VERSION ""

NS_ :

BS_:

BU_: VCM FAS EBS

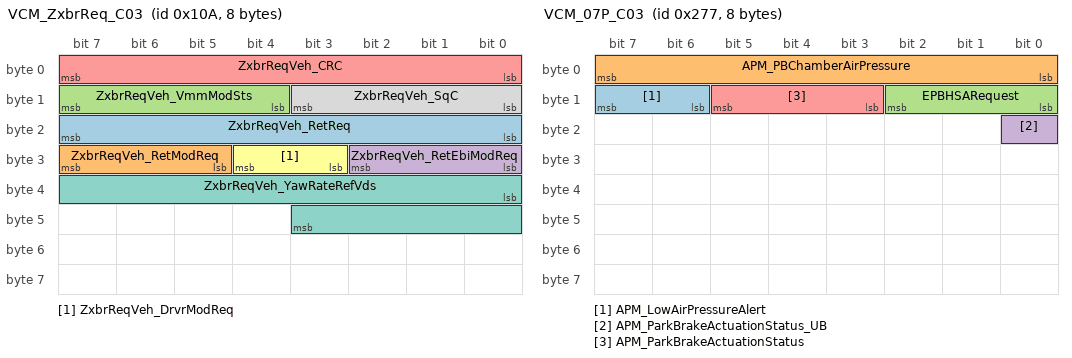
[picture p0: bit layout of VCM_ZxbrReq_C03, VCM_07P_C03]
BO_ 266 VCM_ZxbrReq_C03: 8 VCM
 SG_ ZxbrReqVeh_RetReq : 16|8@1+ (0.005,0) [0|1.275] "NotApplicable"  EBS
 SG_ ZxbrReqVeh_RetModReq : 29|3@1+ (1,0) [0|0] ""  EBS
 SG_ ZxbrReqVeh_VmmModSts : 12|4@1+ (1,0) [0|0] ""  EBS
 SG_ ZxbrReqVeh_RetEbiModReq : 24|3@1+ (1,0) [0|0] ""  EBS
 SG_ ZxbrReqVeh_CRC : 0|8@1+ (1,0) [0|255] ""  EBS
 SG_ ZxbrReqVeh_DrvrModReq : 27|2@1+ (1,0) [0|0] ""  EBS
 SG_ ZxbrReqVeh_YawRateRefVds : 32|12@1+ (0.001,-2) [-2|2.095] "Rad_per_s"  EBS
 SG_ ZxbrReqVeh_SqC : 8|4@1+ (1,0) [0|14] "NotApplicable"  EBS

BO_ 262 VCM_IxbrReqAx456_C03: 48 VCM
 SG_ IxbrReqAxle4_SlipCtrlEna : 41|2@1+ (1,0) [0|0] ""  EBS
 SG_ IxbrReqAxle5_SqC : 128|4@1+ (1,0) [0|14] "NotApplicable"  EBS
 SG_ IxbrReqAxle4_BrkTqReqLe : 43|13@1+ (10,0) [0|81910] "Nm"  EBS
 SG_ IxbrReqAxle4_CRC : 0|8@1+ (1,0) [0|255] ""  EBS
 SG_ IxbrReqAxle5_VehSpdLgtWhlRi : 187|13@1+ (0.01,-40) [-40|41.91] "m_per_s"  EBS
 SG_ IxbrReqAxle6_WhlSlipLimLoLe : 272|9@1+ (0.005,-1) [-1|1.555] "NotApplicable"  EBS
 SG_ IxbrReqAxle5_BrkTqReqRi : 211|13@1+ (10,0) [0|81910] "Nm"  EBS
 SG_ IxbrReqAxle4_BrkTqReqRi : 91|13@1+ (10,0) [0|81910] "Nm"  EBS
 SG_ IxbrReqAxle6_WhlSlipLimHiRi : 344|9@1+ (0.005,-1) [-1|1.555] "NotApplicable"  EBS
 SG_ IxbrReqAxle6_SqC : 248|4@1+ (1,0) [0|14] "NotApplicable"  EBS
 SG_ IxbrReqAxle5_SlipCtrlEna : 161|2@1+ (1,0) [0|0] ""  EBS
 SG_ IxbrReqAxle5_WhlSlipLimLoRi : 200|9@1+ (0.005,-1) [-1|1.555] "NotApplicable"  EBS
 SG_ IxbrReqAxle5_VehSpdLgtWhlLe : 136|13@1+ (0.01,-40) [-40|41.91] "m_per_s"  EBS
 SG_ IxbrReqAxle6_WhlSlipLimLoRi : 320|9@1+ (0.005,-1) [-1|1.555] "NotApplicable"  EBS
 SG_ IxbrReqAxle6_VehSpdLgtWhlRi : 307|13@1+ (0.01,-40) [-40|41.91] "m_per_s"  EBS
 SG_ IxbrReqAxle5_VehSpdLgtWhlQltyLe : 132|4@1+ (1,0) [0|0] ""  EBS
 SG_ IxbrReqAxle6_CRC : 240|8@1+ (1,0) [0|255] ""  EBS
 SG_ IxbrReqAxle5_CRC : 120|8@1+ (1,0) [0|255] ""  EBS
 SG_ IxbrReqAxle4_SqC : 8|4@1+ (1,0) [0|14] "NotApplicable"  EBS
 SG_ IxbrReqAxle4_VehSpdLgtWhlRi : 67|13@1+ (0.01,-40) [-40|41.91] "m_per_s"  EBS
 SG_ IxbrReqAxle4_WhlSlipLimHiLe : 56|9@1+ (0.005,-1) [-1|1.555] "NotApplicable"  EBS
 SG_ IxbrReqAxle4_VehSpdLgtWhlLe : 16|13@1+ (0.01,-40) [-40|41.91] "m_per_s"  EBS
 SG_ IxbrReqAxle4_WhlSlipLimLoLe : 32|9@1+ (0.005,-1) [-1|1.555] "NotApplicable"  EBS
 SG_ IxbrReqAxle6_VehSpdLgtWhlQltyRi : 353|4@1+ (1,0) [0|0] ""  EBS
 SG_ IxbrReqAxle6_BrkTqReqLe : 283|13@1+ (10,0) [0|81910] "Nm"  EBS
 SG_ IxbrReqAxle4_WhlSlipLimLoRi : 80|9@1+ (0.005,-1) [-1|1.555] "NotApplicable"  EBS
 SG_ IxbrReqAxle4_VehSpdLgtWhlQltyRi : 113|4@1+ (1,0) [0|0] ""  EBS
 SG_ IxbrReqAxle4_IxbrModReq : 29|3@1+ (1,0) [0|0] ""  EBS
 SG_ IxbrReqAxle6_BrkTqReqRi : 331|13@1+ (10,0) [0|81910] "Nm"  EBS
 SG_ IxbrReqAxle6_SlipCtrlEna : 281|2@1+ (1,0) [0|0] ""  EBS
 SG_ IxbrReqAxle4_VehSpdLgtWhlQltyLe : 12|4@1+ (1,0) [0|0] ""  EBS
 SG_ IxbrReqAxle6_VehSpdLgtWhlQltyLe : 252|4@1+ (1,0) [0|0] ""  EBS
 SG_ IxbrReqAxle5_BrkTqReqLe : 163|13@1+ (10,0) [0|81910] "Nm"  EBS
 SG_ IxbrReqAxle5_VehSpdLgtWhlQltyRi : 233|4@1+ (1,0) [0|0] ""  EBS
 SG_ IxbrReqAxle5_WhlSlipLimHiRi : 224|9@1+ (0.005,-1) [-1|1.555] "NotApplicable"  EBS
 SG_ IxbrReqAxle5_WhlSlipLimLoLe : 152|9@1+ (0.005,-1) [-1|1.555] "NotApplicable"  EBS
 SG_ IxbrReqAxle5_IxbrModReq : 149|3@1+ (1,0) [0|0] ""  EBS
 SG_ IxbrReqAxle4_WhlSlipLimHiRi : 104|9@1+ (0.005,-1) [-1|1.555] "NotApplicable"  EBS
 SG_ IxbrReqAxle6_IxbrModReq : 269|3@1+ (1,0) [0|0] ""  EBS
 SG_ IxbrReqAxle5_WhlSlipLimHiLe : 176|9@1+ (0.005,-1) [-1|1.555] "NotApplicable"  EBS
 SG_ IxbrReqAxle6_WhlSlipLimHiLe : 296|9@1+ (0.005,-1) [-1|1.555] "NotApplicable"  EBS
 SG_ IxbrReqAxle6_VehSpdLgtWhlLe : 256|13@1+ (0.01,-40) [-40|41.91] "m_per_s"  EBS

BO_ 261 VCM_IxbrReqAx123_C03: 48 VCM
 SG_ IxbrReqAxle3_BrkTqReqLe : 283|13@1+ (10,0) [0|81910] "Nm"  EBS
 SG_ IxbrReqAxle3_WhlSlipLimHiLe : 296|9@1+ (0.005,-1) [-1|1.555] "NotApplicable"  EBS
 SG_ IxbrReqAxle1_BrkTqReqLe : 43|13@1+ (10,0) [0|81910] "Nm"  EBS
 SG_ IxbrReqAxle2_WhlSlipLimHiRi : 224|9@1+ (0.005,-1) [-1|1.555] "NotApplicable"  EBS
 SG_ IxbrReqAxle3_WhlSlipLimLoRi : 320|9@1+ (0.005,-1) [-1|1.555] "NotApplicable"  EBS
 SG_ IxbrReqAxle1_WhlSlipLimLoLe : 32|9@1+ (0.005,-1) [-1|1.555] "NotApplicable"  EBS
 SG_ IxbrReqAxle3_BrkTqReqRi : 331|13@1+ (10,0) [0|81910] "Nm"  EBS
 SG_ IxbrReqAxle2_BrkTqReqLe : 163|13@1+ (10,0) [0|81910] "Nm"  EBS
 SG_ IxbrReqAxle1_VehSpdLgtWhlQltyRi : 113|4@1+ (1,0) [0|0] ""  EBS
 SG_ IxbrReqAxle2_BrkTqReqRi : 211|13@1+ (10,0) [0|81910] "Nm"  EBS
 SG_ IxbrReqAxle1_WhlSlipLimHiLe : 56|9@1+ (0.005,-1) [-1|1.555] "NotApplicable"  EBS
 SG_ IxbrReqAxle1_SlipCtrlEna : 41|2@1+ (1,0) [0|0] ""  EBS
 SG_ IxbrReqAxle1_WhlSlipLimLoRi : 80|9@1+ (0.005,-1) [-1|1.555] "NotApplicable"  EBS
 SG_ IxbrReqAxle2_SlipCtrlEna : 161|2@1+ (1,0) [0|0] ""  EBS
 SG_ IxbrReqAxle1_IxbrModReq : 29|3@1+ (1,0) [0|0] ""  EBS
 SG_ IxbrReqAxle1_SqC : 8|4@1+ (1,0) [0|14] "NotApplicable"  EBS
 SG_ IxbrReqAxle3_VehSpdLgtWhlQltyLe : 252|4@1+ (1,0) [0|0] ""  EBS
 SG_ IxbrReqAxle3_SqC : 248|4@1+ (1,0) [0|14] "NotApplicable"  EBS
 SG_ IxbrReqAxle2_WhlSlipLimLoRi : 200|9@1+ (0.005,-1) [-1|1.555] "NotApplicable"  EBS
 SG_ IxbrReqAxle1_WhlSlipLimHiRi : 104|9@1+ (0.005,-1) [-1|1.555] "NotApplicable"  EBS
 SG_ IxbrReqAxle2_IxbrModReq : 149|3@1+ (1,0) [0|0] ""  EBS
 SG_ IxbrReqAxle3_WhlSlipLimLoLe : 272|9@1+ (0.005,-1) [-1|1.555] "NotApplicable"  EBS
 SG_ IxbrReqAxle2_SqC : 128|4@1+ (1,0) [0|14] "NotApplicable"  EBS
 SG_ IxbrReqAxle1_VehSpdLgtWhlLe : 16|13@1+ (0.01,-40) [-40|41.91] "m_per_s"  EBS
 SG_ IxbrReqAxle3_VehSpdLgtWhlRi : 307|13@1+ (0.01,-40) [-40|41.91] "m_per_s"  EBS
 SG_ IxbrReqAxle3_WhlSlipLimHiRi : 344|9@1+ (0.005,-1) [-1|1.555] "NotApplicable"  EBS
 SG_ IxbrReqAxle2_WhlSlipLimLoLe : 152|9@1+ (0.005,-1) [-1|1.555] "NotApplicable"  EBS
 SG_ IxbrReqAxle2_VehSpdLgtWhlLe : 136|13@1+ (0.01,-40) [-40|41.91] "m_per_s"  EBS
 SG_ IxbrReqAxle2_WhlSlipLimHiLe : 176|9@1+ (0.005,-1) [-1|1.555] "NotApplicable"  EBS
 SG_ IxbrReqAxle3_VehSpdLgtWhlQltyRi : 353|4@1+ (1,0) [0|0] ""  EBS
 SG_ IxbrReqAxle1_VehSpdLgtWhlQltyLe : 12|4@1+ (1,0) [0|0] ""  EBS
 SG_ IxbrReqAxle1_BrkTqReqRi : 91|13@1+ (10,0) [0|81910] "Nm"  EBS
 SG_ IxbrReqAxle1_VehSpdLgtWhlRi : 67|13@1+ (0.01,-40) [-40|41.91] "m_per_s"  EBS
 SG_ IxbrReqAxle3_IxbrModReq : 269|3@1+ (1,0) [0|0] ""  EBS
 SG_ IxbrReqAxle2_CRC : 120|8@1+ (1,0) [0|255] ""  EBS
 SG_ IxbrReqAxle2_VehSpdLgtWhlQltyLe : 132|4@1+ (1,0) [0|0] ""  EBS
 SG_ IxbrReqAxle3_VehSpdLgtWhlLe : 256|13@1+ (0.01,-40) [-40|41.91] "m_per_s"  EBS
 SG_ IxbrReqAxle3_SlipCtrlEna : 281|2@1+ (1,0) [0|0] ""  EBS
 SG_ IxbrReqAxle3_CRC : 240|8@1+ (1,0) [0|255] ""  EBS
 SG_ IxbrReqAxle2_VehSpdLgtWhlRi : 187|13@1+ (0.01,-40) [-40|41.91] "m_per_s"  EBS
 SG_ IxbrReqAxle2_VehSpdLgtWhlQltyRi : 233|4@1+ (1,0) [0|0] ""  EBS
 SG_ IxbrReqAxle1_CRC : 0|8@1+ (1,0) [0|255] ""  EBS

BO_ 554 VCM_EstAxles_C03: 48 VCM
 SG_ EstAxle3_LoadNormLe : 144|8@1+ (100,0) [0|25500] "N"  EBS
 SG_ EstAxle6_WhlRdEstQltyRi : 362|4@1+ (1,0) [0|0] ""  EBS
 SG_ EstAxle5_WhlRdEstQltyRi : 298|4@1+ (1,0) [0|0] ""  EBS
 SG_ EstAxle2_LoadNormQltyLe : 120|4@1+ (1,0) [0|0] ""  EBS
 SG_ EstAxle3_LoadNormQltyRi : 188|4@1+ (1,0) [0|0] ""  EBS
 SG_ EstAxle6_SqC : 328|4@1+ (1,0) [0|14] "NotApplicable"  EBS
 SG_ EstAxle4_LoadNormQltyRi : 252|4@1+ (1,0) [0|0] ""  EBS
 SG_ EstAxle6_LoadNormRi : 344|8@1+ (100,0) [0|25500] "N"  EBS
 SG_ EstAxle5_SqC : 264|4@1+ (1,0) [0|14] "NotApplicable"  EBS
 SG_ EstAxle6_CRC : 320|8@1+ (1,0) [0|255] ""  EBS
 SG_ EstAxle2_WhlRdEstLe : 96|10@1+ (0.001,0.35) [0.35|1.373] "m"  EBS
 SG_ EstAxle3_WhlRdEstRi : 174|10@1+ (0.001,0.35) [0.35|1.373] "m"  EBS
 SG_ EstAxle5_LoadNormQltyRi : 316|4@1+ (1,0) [0|0] ""  EBS
 SG_ EstAxle6_WhlRdEstLe : 352|10@1+ (0.001,0.35) [0.35|1.373] "m"  EBS
 SG_ EstAxle6_WhlRdEstQltyLe : 332|4@1+ (1,0) [0|0] ""  EBS
 SG_ EstAxle6_LoadNormLe : 336|8@1+ (100,0) [0|25500] "N"  EBS
 SG_ EstAxle5_LoadNormRi : 280|8@1+ (100,0) [0|25500] "N"  EBS
 SG_ EstAxle5_LoadNormQltyLe : 312|4@1+ (1,0) [0|0] ""  EBS
 SG_ EstAxle5_CRC : 256|8@1+ (1,0) [0|255] ""  EBS
 SG_ EstAxle1_WhlRdEstRi : 46|10@1+ (0.001,0.35) [0.35|1.373] "m"  EBS
 SG_ EstAxle4_LoadNormRi : 216|8@1+ (100,0) [0|25500] "N"  EBS
 SG_ EstAxle3_WhlRdEstQltyLe : 140|4@1+ (1,0) [0|0] ""  EBS
 SG_ EstAxle4_WhlRdEstRi : 238|10@1+ (0.001,0.35) [0.35|1.373] "m"  EBS
 SG_ EstAxle6_WhlRdEstRi : 366|10@1+ (0.001,0.35) [0.35|1.373] "m"  EBS
 SG_ EstAxle5_LoadNormLe : 272|8@1+ (100,0) [0|25500] "N"  EBS
 SG_ EstAxle5_WhlRdEstLe : 288|10@1+ (0.001,0.35) [0.35|1.373] "m"  EBS
 SG_ EstAxle3_CRC : 128|8@1+ (1,0) [0|255] ""  EBS
 SG_ EstAxle2_LoadNormRi : 88|8@1+ (100,0) [0|25500] "N"  EBS
 SG_ EstAxle4_SqC : 200|4@1+ (1,0) [0|14] "NotApplicable"  EBS
 SG_ EstAxle4_WhlRdEstQltyRi : 234|4@1+ (1,0) [0|0] ""  EBS
 SG_ EstAxle6_LoadNormQltyRi : 380|4@1+ (1,0) [0|0] ""  EBS
 SG_ EstAxle1_LoadNormQltyRi : 60|4@1+ (1,0) [0|0] ""  EBS
 SG_ EstAxle1_LoadNormQltyLe : 56|4@1+ (1,0) [0|0] ""  EBS
 SG_ EstAxle2_LoadNormLe : 80|8@1+ (100,0) [0|25500] "N"  EBS
 SG_ EstAxle4_WhlRdEstQltyLe : 204|4@1+ (1,0) [0|0] ""  EBS
 SG_ EstAxle4_WhlRdEstLe : 224|10@1+ (0.001,0.35) [0.35|1.373] "m"  EBS
 SG_ EstAxle1_WhlRdEstQltyLe : 12|4@1+ (1,0) [0|0] ""  EBS
 SG_ EstAxle2_LoadNormQltyRi : 124|4@1+ (1,0) [0|0] ""  EBS
 SG_ EstAxle3_LoadNormQltyLe : 184|4@1+ (1,0) [0|0] ""  EBS
 SG_ EstAxle4_LoadNormQltyLe : 248|4@1+ (1,0) [0|0] ""  EBS
 SG_ EstAxle2_WhlRdEstQltyRi : 106|4@1+ (1,0) [0|0] ""  EBS
 SG_ EstAxle6_LoadNormQltyLe : 376|4@1+ (1,0) [0|0] ""  EBS
 SG_ EstAxle2_WhlRdEstRi : 110|10@1+ (0.001,0.35) [0.35|1.373] "m"  EBS
 SG_ EstAxle3_WhlRdEstQltyRi : 170|4@1+ (1,0) [0|0] ""  EBS
 SG_ EstAxle1_LoadNormLe : 16|8@1+ (100,0) [0|25500] "N"  EBS
 SG_ EstAxle1_CRC : 0|8@1+ (1,0) [0|255] ""  EBS
 SG_ EstAxle5_WhlRdEstRi : 302|10@1+ (0.001,0.35) [0.35|1.373] "m"  EBS
 SG_ EstAxle2_CRC : 64|8@1+ (1,0) [0|255] ""  EBS
 SG_ EstAxle1_LoadNormRi : 24|8@1+ (100,0) [0|25500] "N"  EBS
 SG_ EstAxle2_WhlRdEstQltyLe : 76|4@1+ (1,0) [0|0] ""  EBS
 SG_ EstAxle4_CRC : 192|8@1+ (1,0) [0|255] ""  EBS
 SG_ EstAxle3_LoadNormRi : 152|8@1+ (100,0) [0|25500] "N"  EBS
 SG_ EstAxle5_WhlRdEstQltyLe : 268|4@1+ (1,0) [0|0] ""  EBS
 SG_ EstAxle3_SqC : 136|4@1+ (1,0) [0|14] "NotApplicable"  EBS
 SG_ EstAxle1_WhlRdEstLe : 32|10@1+ (0.001,0.35) [0.35|1.373] "m"  EBS
 SG_ EstAxle4_LoadNormLe : 208|8@1+ (100,0) [0|25500] "N"  EBS
 SG_ EstAxle1_SqC : 8|4@1+ (1,0) [0|14] "NotApplicable"  EBS
 SG_ EstAxle1_WhlRdEstQltyRi : 42|4@1+ (1,0) [0|0] ""  EBS
 SG_ EstAxle2_SqC : 72|4@1+ (1,0) [0|14] "NotApplicable"  EBS
 SG_ EstAxle3_WhlRdEstLe : 160|10@1+ (0.001,0.35) [0.35|1.373] "m"  EBS

BO_ 631 VCM_07P_C03: 8 VCM
 SG_ APM_LowAirPressureAlert : 14|2@1+ (1,0) [0|0] ""  EBS
 SG_ APM_PBChamberAirPressure : 0|8@1+ (8,0) [0|2040] "kPa"  EBS
 SG_ EPBHSARequest : 8|3@1+ (1,0) [0|0] ""  EBS
 SG_ APM_ParkBrakeActuationStatus_UB : 16|1@1+ (1,0) [0|0] ""  EBS
 SG_ APM_ParkBrakeActuationStatus : 11|3@1+ (1,0) [0|0] ""  EBS

BO_ 1448 VCM_06P_C03: 8 VCM
 SG_ TotalVehicleDistanceHighRes : 0|32@1+ (5,0) [0|21474836475] "m"  FAS
 SG_ AmbientAirTemperature : 32|16@1+ (0.03125,-273) [-273|1774.96875] "DegreeC"  FAS

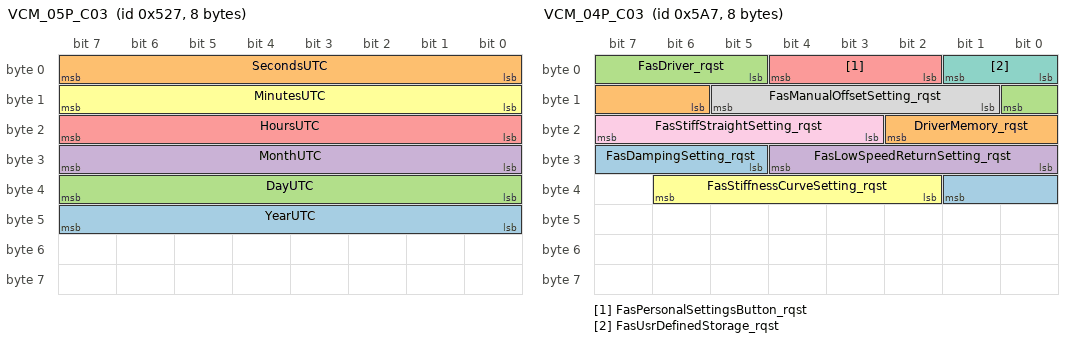
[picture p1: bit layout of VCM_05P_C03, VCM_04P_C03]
BO_ 1319 VCM_05P_C03: 8 VCM
 SG_ YearUTC : 40|8@1+ (1,1985) [1985|2240] "Years"  FAS
 SG_ SecondsUTC : 0|8@1+ (0.25,0) [0|63.75] "s"  FAS
 SG_ DayUTC : 32|8@1+ (0.25,0) [0|63.75] "Days"  FAS
 SG_ MonthUTC : 24|8@1+ (1,0) [0|255] "Months"  FAS
 SG_ HoursUTC : 16|8@1+ (1,0) [0|255] "h"  FAS
 SG_ MinutesUTC : 8|8@1+ (1,0) [0|255] "min"  FAS

BO_ 1447 VCM_04P_C03: 8 VCM
 SG_ FasDampingSetting_rqst : 29|5@1+ (1,-10) [-10|21] ""  FAS
 SG_ DriverMemory_rqst : 14|5@1+ (1,0) [0|0] ""  FAS
 SG_ FasDriver_rqst : 5|4@1+ (1,0) [0|0] ""  FAS
 SG_ FasLowSpeedReturnSetting_rqst : 24|5@1+ (1,-10) [-10|21] ""  FAS
 SG_ FasPersonalSettingsButton_rqst : 2|3@1+ (1,0) [0|0] ""  FAS
 SG_ FasStiffnessCurveSetting_rqst : 34|5@1+ (1,-10) [-10|21] ""  FAS
 SG_ FasUsrDefinedStorage_rqst : 0|2@1+ (1,0) [0|0] ""  FAS
 SG_ FasManualOffsetSetting_rqst : 9|5@1+ (1,-10) [-10|21] ""  FAS
 SG_ FasStiffStraightSetting_rqst : 19|5@1+ (1,-10) [-10|21] ""  FAS

BO_ 1034 VCM_03P_C03: 32 VCM
 SG_ RelativeLevelFrontAxleLeft : 96|16@1+ (0.1,-3200) [-3200|3353.5] "mm"  FAS
 SG_ FrontAxle1Load : 0|16@1+ (0.5,0) [0|32767.5] "kg"  FAS,EBS
 SG_ PusherAxleLoad : 64|16@1+ (0.5,0) [0|32767.5] "kg"  FAS,EBS
 SG_ SecondaryDriveAxleLoad : 48|16@1+ (0.5,0) [0|32767.5] "kg"  FAS,EBS
 SG_ TagAxleLoad : 80|16@1+ (0.5,0) [0|32767.5] "kg"  FAS,EBS
 SG_ ContTrailerBrake_MsgCounter : 136|4@1+ (1,0) [0|15] "Count"  EBS
 SG_ FrontAxle2Load : 16|16@1+ (0.5,0) [0|32767.5] "kg"  FAS,EBS
 SG_ DriveAxleLoad : 32|16@1+ (0.5,0) [0|32767.5] "kg"  EBS,FAS
 SG_ PBAirLvl_AntiCompoundRatio : 156|8@1+ (0.004,0) [0|1.02] ""  EBS
 SG_ ContTrailerBrake_MsgChecksum : 131|5@1+ (1,0) [0|31] ""  EBS
 SG_ PBAirLvl_SqC : 148|4@1+ (1,0) [0|14] "NotApplicable"  EBS
 SG_ PBStatus_CRC : 172|8@1+ (1,0) [0|255] ""  EBS
 SG_ TertiaryDriveAxleLoad : 112|16@1+ (0.5,0) [0|32767.5] "kg"  EBS
 SG_ PBStatus_Actuation : 184|3@1+ (1,0) [0|0] ""  EBS
 SG_ PBStatus_SqC : 180|4@1+ (1,0) [0|14] "NotApplicable"  EBS
 SG_ PBAirLvl_CRC : 140|8@1+ (1,0) [0|255] ""  EBS
 SG_ PBStatus_IntegrityLvl : 188|2@1+ (1,0) [0|0] ""  EBS
 SG_ ContTrailerBrake_Request : 128|3@1+ (1,0) [0|0] ""  EBS
 SG_ PBAirLvl_PressureInChamber : 164|8@1+ (8,0) [0|2040] "kPa"  EBS

BO_ 426 VCM_02P_C03: 32 VCM
 SG_ ChangeKneelACK : 126|2@1+ (1,0) [0|0] ""  EBS
 SG_ LiftAxle1PositionStatus : 112|3@1+ (1,0) [0|0] ""  EBS
 SG_ FrontFerryFunctionCmd : 128|3@1+ (1,0) [0|0] ""  EBS
 SG_ APM_ParkingBrake_stat_UB : 180|1@1+ (1,0) [0|0] ""  EBS
 SG_ ReverseGearEngaged : 22|2@1+ (1,0) [0|0] ""  FAS
 SG_ AirDumpStatus : 104|3@1+ (1,0) [0|0] ""  EBS
 SG_ EngineActiveStatus : 16|4@1+ (1,0) [0|0] ""  FAS
 SG_ FerryFunctionStatus : 107|3@1+ (1,0) [0|0] ""  EBS
 SG_ PitchAngleRef : 56|16@1+ (0.001,-30) [-30|35.535] "deg"  EBS
 SG_ APM_LowVMPBInfoReq : 165|3@1+ (1,0) [0|0] ""  EBS
 SG_ KneelingInformation : 80|4@1+ (1,0) [0|0] ""  EBS
 SG_ FASHapticFeedbackRequest : 28|4@1+ (1,0) [0|0] ""  FAS
 SG_ HeightControlMode : 84|4@1+ (1,0) [0|0] ""  EBS
 SG_ LoadDistributionFuncSelected : 92|4@1+ (1,0) [0|0] ""  EBS
 SG_ PitchAngle : 40|16@1+ (0.001,-30) [-30|35.535] "deg"  EBS
 SG_ RollEndPositionStatus : 123|3@1+ (1,0) [0|0] ""  EBS
 SG_ SupplyPressure : 72|8@1+ (8,0) [0|2040] "kPa"  EBS
 SG_ WheelBasedVehicleSpeed : 0|16@1+ (0.00390625,0) [0|255.99609375] "Km_per_h"  FAS
 SG_ RearAxle2DiffLock_stat : 142|2@1+ (1,0) [0|0] ""  EBS
 SG_ KneelingStatusHMI : 134|2@1+ (1,0) [0|0] ""  EBS
 SG_ HeightAdjustmentAllowed : 110|2@1+ (1,0) [0|0] ""  EBS
 SG_ RideHeightStatus : 100|4@1+ (1,0) [0|0] ""  EBS
 SG_ CentralRearDiffLock_stat : 136|2@1+ (1,0) [0|0] ""  EBS
 SG_ ParkBrakeReleaseMode2 : 172|4@1+ (1,0) [0|0] ""  EBS
 SG_ LiftAxle2PositionStatus : 115|3@1+ (1,0) [0|0] ""  EBS
 SG_ RampHeightOutsideTargetRange : 131|3@1+ (1,0) [0|0] ""  EBS
 SG_ DirInd_Rear_Status : 160|3@1+ (1,0) [0|0] ""  EBS
 SG_ ExternalRequestManualStiffness : 32|4@1+ (0.1,0) [0|1.5] "NotApplicable"  FAS
 SG_ APM_ParkingBrake_stat : 178|2@1+ (1,0) [0|0] ""  EBS
 SG_ VehicleDistanceRollingCounter : 144|16@1+ (0.03125,0) [0|2047.96875] "m"  EBS
 SG_ BackToDriveReqACK : 118|2@1+ (1,0) [0|0] ""  EBS
 SG_ RearAxle1DiffLock_stat : 140|2@1+ (1,0) [0|0] ""  EBS
 SG_ LevelControlInformation : 88|4@1+ (1,0) [0|0] ""  EBS
 SG_ VehicleMode : 36|4@1+ (1,0) [0|0] ""  FAS,EBS
 SG_ ACC_SGO_Status : 24|4@1+ (1,0) [0|0] ""  FAS
 SG_ RearEndPositionStatus : 120|3@1+ (1,0) [0|0] ""  EBS
 SG_ ECSShutdownCmd : 138|2@1+ (1,0) [0|0] ""  EBS
 SG_ APM_ParkBrakeApplicationMode2 : 168|4@1+ (1,0) [0|0] ""  EBS
 SG_ VehicleDynamicSuspProhibitStat : 163|2@1+ (1,0) [0|0] ""  EBS
 SG_ ParkingBrake_stat : 20|2@1+ (1,0) [0|0] ""  FAS
 SG_ RideHeightFunctionStatus : 96|4@1+ (1,0) [0|0] ""  EBS
 SG_ APM_TrailerCircPressureStatus : 176|2@1+ (1,0) [0|0] ""  EBS

CM_ "COM_MATRIX_T3_1.9.0";
CM_ BU_ VCM "Vehicle Control Module";
CM_ BU_ FAS "Front Active Steering";
CM_ BU_ EBS "Electronic Braking System";
BA_DEF_ BO_  "GenMsgStartDelayTime" INT 0 0;
BA_DEF_ BO_  "GenMsgDelayTime" INT 0 0;
BA_DEF_ BO_  "GenMsgCycleTime" INT 0 0;
BA_DEF_ BO_  "GenMsgSendType" ENUM  "Cyclic","NotUsed","NotUsed","NotUsed","NotUsed","NotUsed","NotUsed","IfActive","NoMsgSendType","NotUsed";
BA_DEF_ SG_  "GenSigStartValue" INT 0 0;
BA_DEF_ SG_  "GenSigCycleTimeActive" INT 0 0;
BA_DEF_ SG_  "GenSigCycleTime" INT 0 0;
BA_DEF_ SG_  "GenSigSendType" ENUM  "Cyclic","OnWrite","OnWriteWithRepetition","OnChange","OnChangeWithRepetition","IfActive","IfActiveWithRepetition","NoSigSendType","NotUsed","NotUsed","NotUsed","NotUsed","NotUsed";
BA_DEF_  "Baudrate" INT 0 1000000;
BA_DEF_  "NmType" STRING ;
BA_DEF_  "Manufacturer" STRING ;
BA_DEF_  "VersionYear" INT 0 99;
BA_DEF_  "VersionNumber" INT 0 99;
BA_DEF_  "VersionMonth" INT 1 12;
BA_DEF_  "VersionDay" INT 1 31;
BA_DEF_ BO_  "VFrameFormat" ENUM  "StandardCAN","ExtendedCAN","reserved","J1939PG","reserved","reserved","reserved","reserved","reserved","reserved","reserved","reserved","reserved","reserved","StandardCAN_FD","ExtendedCAN_FD";
BA_DEF_ BU_  "TpOwnSystemEcuNumber" HEX 0 255;
BA_DEF_ SG_  "SigType" ENUM  "Default","Range","RangeSigned","ASCII","Discrete","Control","ReferencePGN","DTC","StringDelimiter","StringLength","StringLengthControl";
BA_DEF_ BU_  "NmStationAddress" INT 0 255;
BA_DEF_  "NmAsrWaitBusSleepTime" INT 0 65535;
BA_DEF_  "NmAsrTimeoutTime" INT 0 65535;
BA_DEF_  "NmAsrRepeatMessageTime" INT 0 65535;
BA_DEF_ BU_  "NmAsrNodeIdentifier" HEX 0 253;
BA_DEF_ BU_  "NmAsrNode" ENUM  "No","Yes";
BA_DEF_  "NmAsrMessageCount" INT 1 256;
BA_DEF_ BO_  "NmAsrMessage" ENUM  "No","Yes";
BA_DEF_  "NmAsrCanMsgCycleTime" INT 0 65535;
BA_DEF_  "NmAsrBaseAddress" HEX 0 536870911;
BA_DEF_ SG_  "NeedsUpdateBit" ENUM  "No","Yes";
BA_DEF_ SG_  "MmAnSignal" ENUM  "No","Yes";
BA_DEF_ BU_  "IsOBDrelevant" ENUM  "No","Yes";
BA_DEF_ SG_  "GenSigMaxLatency" INT 0 65535;
BA_DEF_ SG_  "GenSigILSupport" ENUM  "Yes","No";
BA_DEF_ BO_  "GenMsgILSupport" ENUM  "No","Yes";
BA_DEF_ SG_  "E2EProfile" STRING ;
BA_DEF_  "E2EP05WindowSize" INT 0 65535;
BA_DEF_  "E2EP05ProfileName" STRING ;
BA_DEF_  "E2EP05MinOkStateValid" INT 0 65535;
BA_DEF_  "E2EP05MinOkStateInvalid" INT 0 65535;
BA_DEF_  "E2EP05MinOkStateInit" INT 0 65535;
BA_DEF_  "E2EP05MaxErrorStateValid" INT 0 65535;
BA_DEF_  "E2EP05MaxErrorStateInvalid" INT 0 65535;
BA_DEF_  "E2EP05MaxErrorStateInit" INT 0 65535;
BA_DEF_  "E2EP05MaxDeltaCounter" INT 0 65535;
BA_DEF_  "E2EP01WindowSize" INT 0 65535;
BA_DEF_  "E2EP01SyncCounterInit" INT 0 65535;
BA_DEF_  "E2EP01ProfileName" STRING ;
BA_DEF_  "E2EP01MinOkStateValid" INT 0 65535;
BA_DEF_  "E2EP01MinOkStateInvalid" INT 0 65535;
BA_DEF_  "E2EP01MinOkStateInit" INT 0 65535;
BA_DEF_  "E2EP01MaxNoNewOrRepeatedData" INT 0 65535;
BA_DEF_  "E2EP01MaxErrorStateValid" INT 0 65535;
BA_DEF_  "E2EP01MaxErrorStateInvalid" INT 0 65535;
BA_DEF_  "E2EP01MaxErrorStateInit" INT 0 65535;
BA_DEF_  "E2EP01MaxDeltaCounter" INT 0 65535;
BA_DEF_  "E2EP01DataIdMode" ENUM  "all16Bit","alternating8Bit","lower12Bit","lower8Bit";
BA_DEF_  "E2EP01CounterOffset" INT 0 65535;
BA_DEF_ SG_  "E2EDataLength" INT 0 65535;
BA_DEF_ SG_  "E2EDataId" INT 0 65535;
BA_DEF_ BU_  "DiagnosticClientAddress" HEX 0 255;
BA_DEF_ BO_  "DiagUUDTResponse" ENUM  "No","Yes";
BA_DEF_ BO_  "DiagState" ENUM  "No","Yes";
BA_DEF_ BU_  "DiagRole" ENUM  "None","OBDTester","ExternalTester","InternalTester";
BA_DEF_ BO_  "DiagResponse" ENUM  "No","Yes";
BA_DEF_ BO_  "DiagRequest" ENUM  "No","Yes";
BA_DEF_ BO_  "DiagConnection" HEX 0 65535;
BA_DEF_  "DBName" STRING ;
BA_DEF_ BO_  "CanTpFcFrameId" HEX 0 2147483647;
BA_DEF_ BO_  "CanTpBs" INT 0 255;
BA_DEF_ BO_  "CANFD_BRS" ENUM  "0","1";
BA_DEF_  "BusType" STRING ;
BA_DEF_  "BaudrateCANFD" INT 0 5000000;
BA_DEF_REL_ BU_SG_REL_  "GenSigTimeoutTime" INT 0 65535;
BA_DEF_REL_ BU_SG_REL_  "GenSigFirstTimeoutTime" INT 0 65535;
BA_DEF_DEF_  "GenMsgStartDelayTime" 0;
BA_DEF_DEF_  "GenMsgDelayTime" 0;
BA_DEF_DEF_  "GenMsgCycleTime" 0;
BA_DEF_DEF_  "GenMsgSendType" "Cyclic";
BA_DEF_DEF_  "GenSigStartValue" 0;
BA_DEF_DEF_  "GenSigCycleTimeActive" 0;
BA_DEF_DEF_  "GenSigCycleTime" 0;
BA_DEF_DEF_  "GenSigSendType" "Cyclic";
BA_DEF_DEF_  "Baudrate" 500000;
BA_DEF_DEF_  "NmType" "";
BA_DEF_DEF_  "Manufacturer" "VOLVO_AB";
BA_DEF_DEF_  "VersionYear" 0;
BA_DEF_DEF_  "VersionNumber" 0;
BA_DEF_DEF_  "VersionMonth" 1;
BA_DEF_DEF_  "VersionDay" 1;
BA_DEF_DEF_  "VFrameFormat" "ExtendedCAN";
BA_DEF_DEF_  "TpOwnSystemEcuNumber" 0;
BA_DEF_DEF_  "SigType" "Default";
BA_DEF_DEF_  "NmStationAddress" 254;
BA_DEF_DEF_  "NmAsrWaitBusSleepTime" 750;
BA_DEF_DEF_  "NmAsrTimeoutTime" 5000;
BA_DEF_DEF_  "NmAsrRepeatMessageTime" 300;
BA_DEF_DEF_  "NmAsrNodeIdentifier" 0;
BA_DEF_DEF_  "NmAsrNode" "Yes";
BA_DEF_DEF_  "NmAsrMessageCount" 256;
BA_DEF_DEF_  "NmAsrMessage" "No";
BA_DEF_DEF_  "NmAsrCanMsgCycleTime" 200;
BA_DEF_DEF_  "NmAsrBaseAddress" 486506496;
BA_DEF_DEF_  "NeedsUpdateBit" "No";
BA_DEF_DEF_  "MmAnSignal" "No";
BA_DEF_DEF_  "IsOBDrelevant" "No";
BA_DEF_DEF_  "GenSigMaxLatency" 0;
BA_DEF_DEF_  "GenSigILSupport" "Yes";
BA_DEF_DEF_  "GenMsgILSupport" "Yes";
BA_DEF_DEF_  "E2EProfile" "none";
BA_DEF_DEF_  "E2EP05WindowSize" 5;
BA_DEF_DEF_  "E2EP05ProfileName" "PROFILE_05";
BA_DEF_DEF_  "E2EP05MinOkStateValid" 1;
BA_DEF_DEF_  "E2EP05MinOkStateInvalid" 3;
BA_DEF_DEF_  "E2EP05MinOkStateInit" 1;
BA_DEF_DEF_  "E2EP05MaxErrorStateValid" 3;
BA_DEF_DEF_  "E2EP05MaxErrorStateInvalid" 1;
BA_DEF_DEF_  "E2EP05MaxErrorStateInit" 2;
BA_DEF_DEF_  "E2EP05MaxDeltaCounter" 1;
BA_DEF_DEF_  "E2EP01WindowSize" 5;
BA_DEF_DEF_  "E2EP01SyncCounterInit" 1;
BA_DEF_DEF_  "E2EP01ProfileName" "PROFILE_01";
BA_DEF_DEF_  "E2EP01MinOkStateValid" 1;
BA_DEF_DEF_  "E2EP01MinOkStateInvalid" 3;
BA_DEF_DEF_  "E2EP01MinOkStateInit" 1;
BA_DEF_DEF_  "E2EP01MaxNoNewOrRepeatedData" 5;
BA_DEF_DEF_  "E2EP01MaxErrorStateValid" 3;
BA_DEF_DEF_  "E2EP01MaxErrorStateInvalid" 1;
BA_DEF_DEF_  "E2EP01MaxErrorStateInit" 2;
BA_DEF_DEF_  "E2EP01MaxDeltaCounter" 1;
BA_DEF_DEF_  "E2EP01DataIdMode" "all16Bit";
BA_DEF_DEF_  "E2EP01CounterOffset" 8;
BA_DEF_DEF_  "E2EDataLength" 0;
BA_DEF_DEF_  "E2EDataId" 0;
BA_DEF_DEF_  "DiagnosticClientAddress" 0;
BA_DEF_DEF_  "DiagUUDTResponse" "No";
BA_DEF_DEF_  "DiagState" "No";
BA_DEF_DEF_  "DiagRole" "None";
BA_DEF_DEF_  "DiagResponse" "No";
BA_DEF_DEF_  "DiagRequest" "No";
BA_DEF_DEF_  "DiagConnection" 0;
BA_DEF_DEF_  "DBName" "";
BA_DEF_DEF_  "CanTpFcFrameId" 2147483647;
BA_DEF_DEF_  "CanTpBs" 255;
BA_DEF_DEF_  "CANFD_BRS" "0";
BA_DEF_DEF_  "BusType" "";
BA_DEF_DEF_  "BaudrateCANFD" 0;
BA_DEF_DEF_REL_ "GenSigTimeoutTime" 0;
BA_DEF_DEF_REL_ "GenSigFirstTimeoutTime" 0;
BA_ "NmType" "NmAsr";
BA_ "BusType" "CAN FD";
BA_ "BaudrateCANFD" 1000000;
BA_ "VersionDay" 24;
BA_ "VersionMonth" 2;
BA_ "VersionNumber" 1;
BA_ "VersionYear" 22;
BA_ "DBName" "CAN03";
BA_ "DiagRole" BU_ VCM 3;
BA_ "DiagnosticClientAddress" BU_ VCM 244;
BA_ "IsOBDrelevant" BU_ VCM 1;
BA_ "TpOwnSystemEcuNumber" BU_ VCM 36;
BA_ "NmAsrNodeIdentifier" BU_ VCM 36;
BA_ "TpOwnSystemEcuNumber" BU_ FAS 48;
BA_ "NmAsrNodeIdentifier" BU_ FAS 48;
BA_ "TpOwnSystemEcuNumber" BU_ EBS 40;
BA_ "NmAsrNodeIdentifier" BU_ EBS 40;
BA_ "CANFD_BRS" BO_ 266 1;
BA_ "GenMsgCycleTime" BO_ 266 10;
BA_ "VFrameFormat" BO_ 266 14;
BA_ "CANFD_BRS" BO_ 262 1;
BA_ "GenMsgCycleTime" BO_ 262 10;
BA_ "GenMsgStartDelayTime" BO_ 262 5;
BA_ "VFrameFormat" BO_ 262 14;
BA_ "CANFD_BRS" BO_ 261 1;
BA_ "GenMsgCycleTime" BO_ 261 10;
BA_ "VFrameFormat" BO_ 261 14;
BA_ "CANFD_BRS" BO_ 554 1;
BA_ "GenMsgCycleTime" BO_ 554 50;
BA_ "GenMsgStartDelayTime" BO_ 554 10;
BA_ "VFrameFormat" BO_ 554 14;
BA_ "GenMsgCycleTime" BO_ 631 50;
BA_ "GenMsgStartDelayTime" BO_ 631 35;
BA_ "VFrameFormat" BO_ 631 14;
BA_ "CANFD_BRS" BO_ 1448 1;
BA_ "GenMsgCycleTime" BO_ 1448 1000;
BA_ "GenMsgStartDelayTime" BO_ 1448 225;
BA_ "VFrameFormat" BO_ 1448 14;
BA_ "CANFD_BRS" BO_ 1319 1;
BA_ "GenMsgCycleTime" BO_ 1319 250;
BA_ "GenMsgStartDelayTime" BO_ 1319 50;
BA_ "VFrameFormat" BO_ 1319 14;
BA_ "CANFD_BRS" BO_ 1447 1;
BA_ "GenMsgCycleTime" BO_ 1447 1000;
BA_ "GenMsgStartDelayTime" BO_ 1447 110;
BA_ "VFrameFormat" BO_ 1447 14;
BA_ "CANFD_BRS" BO_ 1034 1;
BA_ "GenMsgCycleTime" BO_ 1034 100;
BA_ "GenMsgStartDelayTime" BO_ 1034 25;
BA_ "VFrameFormat" BO_ 1034 14;
BA_ "CANFD_BRS" BO_ 426 1;
BA_ "GenMsgCycleTime" BO_ 426 20;
BA_ "GenMsgStartDelayTime" BO_ 426 5;
BA_ "VFrameFormat" BO_ 426 14;
BA_ "GenSigCycleTime" SG_ 266 ZxbrReqVeh_RetReq 100;
BA_ "GenSigCycleTimeActive" SG_ 266 ZxbrReqVeh_RetReq 100;
BA_ "GenSigStartValue" SG_ 266 ZxbrReqVeh_RetReq 255;
BA_ "GenSigCycleTime" SG_ 266 ZxbrReqVeh_RetModReq 100;
BA_ "GenSigCycleTimeActive" SG_ 266 ZxbrReqVeh_RetModReq 100;
BA_ "GenSigStartValue" SG_ 266 ZxbrReqVeh_RetModReq 7;
BA_ "GenSigCycleTime" SG_ 266 ZxbrReqVeh_VmmModSts 100;
BA_ "GenSigCycleTimeActive" SG_ 266 ZxbrReqVeh_VmmModSts 100;
BA_ "GenSigStartValue" SG_ 266 ZxbrReqVeh_VmmModSts 15;
BA_ "GenSigCycleTime" SG_ 266 ZxbrReqVeh_RetEbiModReq 100;
BA_ "GenSigCycleTimeActive" SG_ 266 ZxbrReqVeh_RetEbiModReq 100;
BA_ "GenSigStartValue" SG_ 266 ZxbrReqVeh_RetEbiModReq 7;
BA_ "GenSigCycleTime" SG_ 266 ZxbrReqVeh_CRC 100;
BA_ "GenSigCycleTimeActive" SG_ 266 ZxbrReqVeh_CRC 100;
BA_ "GenSigStartValue" SG_ 266 ZxbrReqVeh_CRC 255;
BA_ "E2EDataId" SG_ 266 ZxbrReqVeh_CRC 198;
BA_ "E2EDataLength" SG_ 266 ZxbrReqVeh_CRC 48;
BA_ "E2EProfile" SG_ 266 ZxbrReqVeh_CRC "P01";
BA_ "GenSigCycleTime" SG_ 266 ZxbrReqVeh_DrvrModReq 100;
BA_ "GenSigCycleTimeActive" SG_ 266 ZxbrReqVeh_DrvrModReq 100;
BA_ "GenSigStartValue" SG_ 266 ZxbrReqVeh_DrvrModReq 3;
BA_ "GenSigCycleTime" SG_ 266 ZxbrReqVeh_YawRateRefVds 100;
BA_ "GenSigCycleTimeActive" SG_ 266 ZxbrReqVeh_YawRateRefVds 100;
BA_ "GenSigStartValue" SG_ 266 ZxbrReqVeh_YawRateRefVds 4095;
BA_ "GenSigCycleTime" SG_ 266 ZxbrReqVeh_SqC 100;
BA_ "GenSigCycleTimeActive" SG_ 266 ZxbrReqVeh_SqC 100;
BA_ "GenSigStartValue" SG_ 266 ZxbrReqVeh_SqC 14;
BA_ "GenSigCycleTime" SG_ 262 IxbrReqAxle4_SlipCtrlEna 100;
BA_ "GenSigCycleTimeActive" SG_ 262 IxbrReqAxle4_SlipCtrlEna 100;
BA_ "GenSigStartValue" SG_ 262 IxbrReqAxle4_SlipCtrlEna 3;
BA_ "GenSigCycleTime" SG_ 262 IxbrReqAxle5_SqC 100;
BA_ "GenSigCycleTimeActive" SG_ 262 IxbrReqAxle5_SqC 100;
BA_ "GenSigStartValue" SG_ 262 IxbrReqAxle5_SqC 14;
BA_ "GenSigCycleTime" SG_ 262 IxbrReqAxle4_BrkTqReqLe 100;
BA_ "GenSigCycleTimeActive" SG_ 262 IxbrReqAxle4_BrkTqReqLe 100;
BA_ "GenSigStartValue" SG_ 262 IxbrReqAxle4_BrkTqReqLe 8191;
BA_ "GenSigCycleTime" SG_ 262 IxbrReqAxle4_CRC 100;
BA_ "GenSigCycleTimeActive" SG_ 262 IxbrReqAxle4_CRC 100;
BA_ "GenSigStartValue" SG_ 262 IxbrReqAxle4_CRC 255;
BA_ "E2EDataId" SG_ 262 IxbrReqAxle4_CRC 218;
BA_ "E2EDataLength" SG_ 262 IxbrReqAxle4_CRC 120;
BA_ "E2EProfile" SG_ 262 IxbrReqAxle4_CRC "P01";
BA_ "GenSigCycleTime" SG_ 262 IxbrReqAxle5_VehSpdLgtWhlRi 100;
BA_ "GenSigCycleTimeActive" SG_ 262 IxbrReqAxle5_VehSpdLgtWhlRi 100;
BA_ "GenSigStartValue" SG_ 262 IxbrReqAxle5_VehSpdLgtWhlRi 8191;
BA_ "GenSigCycleTime" SG_ 262 IxbrReqAxle6_WhlSlipLimLoLe 100;
BA_ "GenSigCycleTimeActive" SG_ 262 IxbrReqAxle6_WhlSlipLimLoLe 100;
BA_ "GenSigStartValue" SG_ 262 IxbrReqAxle6_WhlSlipLimLoLe 511;
BA_ "GenSigCycleTime" SG_ 262 IxbrReqAxle5_BrkTqReqRi 100;
BA_ "GenSigCycleTimeActive" SG_ 262 IxbrReqAxle5_BrkTqReqRi 100;
BA_ "GenSigStartValue" SG_ 262 IxbrReqAxle5_BrkTqReqRi 8191;
BA_ "GenSigCycleTime" SG_ 262 IxbrReqAxle4_BrkTqReqRi 100;
BA_ "GenSigCycleTimeActive" SG_ 262 IxbrReqAxle4_BrkTqReqRi 100;
BA_ "GenSigStartValue" SG_ 262 IxbrReqAxle4_BrkTqReqRi 8191;
BA_ "GenSigCycleTime" SG_ 262 IxbrReqAxle6_WhlSlipLimHiRi 100;
BA_ "GenSigCycleTimeActive" SG_ 262 IxbrReqAxle6_WhlSlipLimHiRi 100;
BA_ "GenSigStartValue" SG_ 262 IxbrReqAxle6_WhlSlipLimHiRi 511;
BA_ "GenSigCycleTime" SG_ 262 IxbrReqAxle6_SqC 100;
BA_ "GenSigCycleTimeActive" SG_ 262 IxbrReqAxle6_SqC 100;
BA_ "GenSigStartValue" SG_ 262 IxbrReqAxle6_SqC 14;
BA_ "GenSigCycleTime" SG_ 262 IxbrReqAxle5_SlipCtrlEna 100;
BA_ "GenSigCycleTimeActive" SG_ 262 IxbrReqAxle5_SlipCtrlEna 100;
BA_ "GenSigStartValue" SG_ 262 IxbrReqAxle5_SlipCtrlEna 3;
BA_ "GenSigCycleTime" SG_ 262 IxbrReqAxle5_WhlSlipLimLoRi 100;
BA_ "GenSigCycleTimeActive" SG_ 262 IxbrReqAxle5_WhlSlipLimLoRi 100;
BA_ "GenSigStartValue" SG_ 262 IxbrReqAxle5_WhlSlipLimLoRi 511;
BA_ "GenSigCycleTime" SG_ 262 IxbrReqAxle5_VehSpdLgtWhlLe 100;
BA_ "GenSigCycleTimeActive" SG_ 262 IxbrReqAxle5_VehSpdLgtWhlLe 100;
BA_ "GenSigStartValue" SG_ 262 IxbrReqAxle5_VehSpdLgtWhlLe 8191;
BA_ "GenSigCycleTime" SG_ 262 IxbrReqAxle6_WhlSlipLimLoRi 100;
BA_ "GenSigCycleTimeActive" SG_ 262 IxbrReqAxle6_WhlSlipLimLoRi 100;
BA_ "GenSigStartValue" SG_ 262 IxbrReqAxle6_WhlSlipLimLoRi 511;
BA_ "GenSigCycleTime" SG_ 262 IxbrReqAxle6_VehSpdLgtWhlRi 100;
BA_ "GenSigCycleTimeActive" SG_ 262 IxbrReqAxle6_VehSpdLgtWhlRi 100;
BA_ "GenSigStartValue" SG_ 262 IxbrReqAxle6_VehSpdLgtWhlRi 8191;
BA_ "GenSigCycleTime" SG_ 262 IxbrReqAxle5_VehSpdLgtWhlQltyLe 100;
BA_ "GenSigCycleTimeActive" SG_ 262 IxbrReqAxle5_VehSpdLgtWhlQltyLe 100;
BA_ "GenSigStartValue" SG_ 262 IxbrReqAxle5_VehSpdLgtWhlQltyLe 15;
BA_ "GenSigCycleTime" SG_ 262 IxbrReqAxle6_CRC 100;
BA_ "GenSigCycleTimeActive" SG_ 262 IxbrReqAxle6_CRC 100;
BA_ "GenSigStartValue" SG_ 262 IxbrReqAxle6_CRC 255;
BA_ "E2EDataId" SG_ 262 IxbrReqAxle6_CRC 220;
BA_ "E2EDataLength" SG_ 262 IxbrReqAxle6_CRC 120;
BA_ "E2EProfile" SG_ 262 IxbrReqAxle6_CRC "P01";
BA_ "GenSigCycleTime" SG_ 262 IxbrReqAxle5_CRC 100;
BA_ "GenSigCycleTimeActive" SG_ 262 IxbrReqAxle5_CRC 100;
BA_ "GenSigStartValue" SG_ 262 IxbrReqAxle5_CRC 255;
BA_ "E2EDataId" SG_ 262 IxbrReqAxle5_CRC 219;
BA_ "E2EDataLength" SG_ 262 IxbrReqAxle5_CRC 120;
BA_ "E2EProfile" SG_ 262 IxbrReqAxle5_CRC "P01";
BA_ "GenSigCycleTime" SG_ 262 IxbrReqAxle4_SqC 100;
BA_ "GenSigCycleTimeActive" SG_ 262 IxbrReqAxle4_SqC 100;
BA_ "GenSigStartValue" SG_ 262 IxbrReqAxle4_SqC 14;
BA_ "GenSigCycleTime" SG_ 262 IxbrReqAxle4_VehSpdLgtWhlRi 100;
BA_ "GenSigCycleTimeActive" SG_ 262 IxbrReqAxle4_VehSpdLgtWhlRi 100;
BA_ "GenSigStartValue" SG_ 262 IxbrReqAxle4_VehSpdLgtWhlRi 8191;
BA_ "GenSigCycleTime" SG_ 262 IxbrReqAxle4_WhlSlipLimHiLe 100;
BA_ "GenSigCycleTimeActive" SG_ 262 IxbrReqAxle4_WhlSlipLimHiLe 100;
BA_ "GenSigStartValue" SG_ 262 IxbrReqAxle4_WhlSlipLimHiLe 511;
BA_ "GenSigCycleTime" SG_ 262 IxbrReqAxle4_VehSpdLgtWhlLe 100;
BA_ "GenSigCycleTimeActive" SG_ 262 IxbrReqAxle4_VehSpdLgtWhlLe 100;
BA_ "GenSigStartValue" SG_ 262 IxbrReqAxle4_VehSpdLgtWhlLe 8191;
BA_ "GenSigCycleTime" SG_ 262 IxbrReqAxle4_WhlSlipLimLoLe 100;
BA_ "GenSigCycleTimeActive" SG_ 262 IxbrReqAxle4_WhlSlipLimLoLe 100;
BA_ "GenSigStartValue" SG_ 262 IxbrReqAxle4_WhlSlipLimLoLe 511;
BA_ "GenSigCycleTime" SG_ 262 IxbrReqAxle6_VehSpdLgtWhlQltyRi 100;
BA_ "GenSigCycleTimeActive" SG_ 262 IxbrReqAxle6_VehSpdLgtWhlQltyRi 100;
BA_ "GenSigStartValue" SG_ 262 IxbrReqAxle6_VehSpdLgtWhlQltyRi 15;
BA_ "GenSigCycleTime" SG_ 262 IxbrReqAxle6_BrkTqReqLe 100;
BA_ "GenSigCycleTimeActive" SG_ 262 IxbrReqAxle6_BrkTqReqLe 100;
BA_ "GenSigStartValue" SG_ 262 IxbrReqAxle6_BrkTqReqLe 8191;
BA_ "GenSigCycleTime" SG_ 262 IxbrReqAxle4_WhlSlipLimLoRi 100;
BA_ "GenSigCycleTimeActive" SG_ 262 IxbrReqAxle4_WhlSlipLimLoRi 100;
BA_ "GenSigStartValue" SG_ 262 IxbrReqAxle4_WhlSlipLimLoRi 511;
BA_ "GenSigCycleTime" SG_ 262 IxbrReqAxle4_VehSpdLgtWhlQltyRi 100;
BA_ "GenSigCycleTimeActive" SG_ 262 IxbrReqAxle4_VehSpdLgtWhlQltyRi 100;
BA_ "GenSigStartValue" SG_ 262 IxbrReqAxle4_VehSpdLgtWhlQltyRi 15;
BA_ "GenSigCycleTime" SG_ 262 IxbrReqAxle4_IxbrModReq 100;
BA_ "GenSigCycleTimeActive" SG_ 262 IxbrReqAxle4_IxbrModReq 100;
BA_ "GenSigStartValue" SG_ 262 IxbrReqAxle4_IxbrModReq 7;
BA_ "GenSigCycleTime" SG_ 262 IxbrReqAxle6_BrkTqReqRi 100;
BA_ "GenSigCycleTimeActive" SG_ 262 IxbrReqAxle6_BrkTqReqRi 100;
BA_ "GenSigStartValue" SG_ 262 IxbrReqAxle6_BrkTqReqRi 8191;
BA_ "GenSigCycleTime" SG_ 262 IxbrReqAxle6_SlipCtrlEna 100;
BA_ "GenSigCycleTimeActive" SG_ 262 IxbrReqAxle6_SlipCtrlEna 100;
BA_ "GenSigStartValue" SG_ 262 IxbrReqAxle6_SlipCtrlEna 3;
BA_ "GenSigCycleTime" SG_ 262 IxbrReqAxle4_VehSpdLgtWhlQltyLe 100;
BA_ "GenSigCycleTimeActive" SG_ 262 IxbrReqAxle4_VehSpdLgtWhlQltyLe 100;
BA_ "GenSigStartValue" SG_ 262 IxbrReqAxle4_VehSpdLgtWhlQltyLe 15;
BA_ "GenSigCycleTime" SG_ 262 IxbrReqAxle6_VehSpdLgtWhlQltyLe 100;
BA_ "GenSigCycleTimeActive" SG_ 262 IxbrReqAxle6_VehSpdLgtWhlQltyLe 100;
BA_ "GenSigStartValue" SG_ 262 IxbrReqAxle6_VehSpdLgtWhlQltyLe 15;
BA_ "GenSigCycleTime" SG_ 262 IxbrReqAxle5_BrkTqReqLe 100;
BA_ "GenSigCycleTimeActive" SG_ 262 IxbrReqAxle5_BrkTqReqLe 100;
BA_ "GenSigStartValue" SG_ 262 IxbrReqAxle5_BrkTqReqLe 8191;
BA_ "GenSigCycleTime" SG_ 262 IxbrReqAxle5_VehSpdLgtWhlQltyRi 100;
BA_ "GenSigCycleTimeActive" SG_ 262 IxbrReqAxle5_VehSpdLgtWhlQltyRi 100;
BA_ "GenSigStartValue" SG_ 262 IxbrReqAxle5_VehSpdLgtWhlQltyRi 15;
BA_ "GenSigCycleTime" SG_ 262 IxbrReqAxle5_WhlSlipLimHiRi 100;
BA_ "GenSigCycleTimeActive" SG_ 262 IxbrReqAxle5_WhlSlipLimHiRi 100;
BA_ "GenSigStartValue" SG_ 262 IxbrReqAxle5_WhlSlipLimHiRi 511;
BA_ "GenSigCycleTime" SG_ 262 IxbrReqAxle5_WhlSlipLimLoLe 100;
BA_ "GenSigCycleTimeActive" SG_ 262 IxbrReqAxle5_WhlSlipLimLoLe 100;
BA_ "GenSigStartValue" SG_ 262 IxbrReqAxle5_WhlSlipLimLoLe 511;
BA_ "GenSigCycleTime" SG_ 262 IxbrReqAxle5_IxbrModReq 100;
BA_ "GenSigCycleTimeActive" SG_ 262 IxbrReqAxle5_IxbrModReq 100;
BA_ "GenSigStartValue" SG_ 262 IxbrReqAxle5_IxbrModReq 7;
BA_ "GenSigCycleTime" SG_ 262 IxbrReqAxle4_WhlSlipLimHiRi 100;
BA_ "GenSigCycleTimeActive" SG_ 262 IxbrReqAxle4_WhlSlipLimHiRi 100;
BA_ "GenSigStartValue" SG_ 262 IxbrReqAxle4_WhlSlipLimHiRi 511;
BA_ "GenSigCycleTime" SG_ 262 IxbrReqAxle6_IxbrModReq 100;
BA_ "GenSigCycleTimeActive" SG_ 262 IxbrReqAxle6_IxbrModReq 100;
BA_ "GenSigStartValue" SG_ 262 IxbrReqAxle6_IxbrModReq 7;
BA_ "GenSigCycleTime" SG_ 262 IxbrReqAxle5_WhlSlipLimHiLe 100;
BA_ "GenSigCycleTimeActive" SG_ 262 IxbrReqAxle5_WhlSlipLimHiLe 100;
BA_ "GenSigStartValue" SG_ 262 IxbrReqAxle5_WhlSlipLimHiLe 511;
BA_ "GenSigCycleTime" SG_ 262 IxbrReqAxle6_WhlSlipLimHiLe 100;
BA_ "GenSigCycleTimeActive" SG_ 262 IxbrReqAxle6_WhlSlipLimHiLe 100;
BA_ "GenSigStartValue" SG_ 262 IxbrReqAxle6_WhlSlipLimHiLe 511;
BA_ "GenSigCycleTime" SG_ 262 IxbrReqAxle6_VehSpdLgtWhlLe 100;
BA_ "GenSigCycleTimeActive" SG_ 262 IxbrReqAxle6_VehSpdLgtWhlLe 100;
BA_ "GenSigStartValue" SG_ 262 IxbrReqAxle6_VehSpdLgtWhlLe 8191;
BA_ "GenSigCycleTime" SG_ 261 IxbrReqAxle3_BrkTqReqLe 100;
BA_ "GenSigCycleTimeActive" SG_ 261 IxbrReqAxle3_BrkTqReqLe 100;
BA_ "GenSigStartValue" SG_ 261 IxbrReqAxle3_BrkTqReqLe 8191;
BA_ "GenSigCycleTime" SG_ 261 IxbrReqAxle3_WhlSlipLimHiLe 100;
BA_ "GenSigCycleTimeActive" SG_ 261 IxbrReqAxle3_WhlSlipLimHiLe 100;
BA_ "GenSigStartValue" SG_ 261 IxbrReqAxle3_WhlSlipLimHiLe 511;
BA_ "GenSigCycleTime" SG_ 261 IxbrReqAxle1_BrkTqReqLe 100;
BA_ "GenSigCycleTimeActive" SG_ 261 IxbrReqAxle1_BrkTqReqLe 100;
BA_ "GenSigStartValue" SG_ 261 IxbrReqAxle1_BrkTqReqLe 8191;
BA_ "GenSigCycleTime" SG_ 261 IxbrReqAxle2_WhlSlipLimHiRi 100;
BA_ "GenSigCycleTimeActive" SG_ 261 IxbrReqAxle2_WhlSlipLimHiRi 100;
BA_ "GenSigStartValue" SG_ 261 IxbrReqAxle2_WhlSlipLimHiRi 511;
BA_ "GenSigCycleTime" SG_ 261 IxbrReqAxle3_WhlSlipLimLoRi 100;
BA_ "GenSigCycleTimeActive" SG_ 261 IxbrReqAxle3_WhlSlipLimLoRi 100;
BA_ "GenSigStartValue" SG_ 261 IxbrReqAxle3_WhlSlipLimLoRi 511;
BA_ "GenSigCycleTime" SG_ 261 IxbrReqAxle1_WhlSlipLimLoLe 100;
BA_ "GenSigCycleTimeActive" SG_ 261 IxbrReqAxle1_WhlSlipLimLoLe 100;
BA_ "GenSigStartValue" SG_ 261 IxbrReqAxle1_WhlSlipLimLoLe 511;
BA_ "GenSigCycleTime" SG_ 261 IxbrReqAxle3_BrkTqReqRi 100;
BA_ "GenSigCycleTimeActive" SG_ 261 IxbrReqAxle3_BrkTqReqRi 100;
BA_ "GenSigStartValue" SG_ 261 IxbrReqAxle3_BrkTqReqRi 8191;
BA_ "GenSigCycleTime" SG_ 261 IxbrReqAxle2_BrkTqReqLe 100;
BA_ "GenSigCycleTimeActive" SG_ 261 IxbrReqAxle2_BrkTqReqLe 100;
BA_ "GenSigStartValue" SG_ 261 IxbrReqAxle2_BrkTqReqLe 8191;
BA_ "GenSigCycleTime" SG_ 261 IxbrReqAxle1_VehSpdLgtWhlQltyRi 100;
BA_ "GenSigCycleTimeActive" SG_ 261 IxbrReqAxle1_VehSpdLgtWhlQltyRi 100;
BA_ "GenSigStartValue" SG_ 261 IxbrReqAxle1_VehSpdLgtWhlQltyRi 15;
BA_ "GenSigCycleTime" SG_ 261 IxbrReqAxle2_BrkTqReqRi 100;
BA_ "GenSigCycleTimeActive" SG_ 261 IxbrReqAxle2_BrkTqReqRi 100;
BA_ "GenSigStartValue" SG_ 261 IxbrReqAxle2_BrkTqReqRi 8191;
BA_ "GenSigCycleTime" SG_ 261 IxbrReqAxle1_WhlSlipLimHiLe 100;
BA_ "GenSigCycleTimeActive" SG_ 261 IxbrReqAxle1_WhlSlipLimHiLe 100;
BA_ "GenSigStartValue" SG_ 261 IxbrReqAxle1_WhlSlipLimHiLe 511;
BA_ "GenSigCycleTime" SG_ 261 IxbrReqAxle1_SlipCtrlEna 100;
BA_ "GenSigCycleTimeActive" SG_ 261 IxbrReqAxle1_SlipCtrlEna 100;
BA_ "GenSigStartValue" SG_ 261 IxbrReqAxle1_SlipCtrlEna 3;
BA_ "GenSigCycleTime" SG_ 261 IxbrReqAxle1_WhlSlipLimLoRi 100;
BA_ "GenSigCycleTimeActive" SG_ 261 IxbrReqAxle1_WhlSlipLimLoRi 100;
BA_ "GenSigStartValue" SG_ 261 IxbrReqAxle1_WhlSlipLimLoRi 511;
BA_ "GenSigCycleTime" SG_ 261 IxbrReqAxle2_SlipCtrlEna 100;
BA_ "GenSigCycleTimeActive" SG_ 261 IxbrReqAxle2_SlipCtrlEna 100;
BA_ "GenSigStartValue" SG_ 261 IxbrReqAxle2_SlipCtrlEna 3;
BA_ "GenSigCycleTime" SG_ 261 IxbrReqAxle1_IxbrModReq 100;
BA_ "GenSigCycleTimeActive" SG_ 261 IxbrReqAxle1_IxbrModReq 100;
BA_ "GenSigStartValue" SG_ 261 IxbrReqAxle1_IxbrModReq 7;
BA_ "GenSigCycleTime" SG_ 261 IxbrReqAxle1_SqC 100;
BA_ "GenSigCycleTimeActive" SG_ 261 IxbrReqAxle1_SqC 100;
BA_ "GenSigStartValue" SG_ 261 IxbrReqAxle1_SqC 14;
BA_ "GenSigCycleTime" SG_ 261 IxbrReqAxle3_VehSpdLgtWhlQltyLe 100;
BA_ "GenSigCycleTimeActive" SG_ 261 IxbrReqAxle3_VehSpdLgtWhlQltyLe 100;
BA_ "GenSigStartValue" SG_ 261 IxbrReqAxle3_VehSpdLgtWhlQltyLe 15;
BA_ "GenSigCycleTime" SG_ 261 IxbrReqAxle3_SqC 100;
BA_ "GenSigCycleTimeActive" SG_ 261 IxbrReqAxle3_SqC 100;
BA_ "GenSigStartValue" SG_ 261 IxbrReqAxle3_SqC 14;
BA_ "GenSigCycleTime" SG_ 261 IxbrReqAxle2_WhlSlipLimLoRi 100;
BA_ "GenSigCycleTimeActive" SG_ 261 IxbrReqAxle2_WhlSlipLimLoRi 100;
BA_ "GenSigStartValue" SG_ 261 IxbrReqAxle2_WhlSlipLimLoRi 511;
BA_ "GenSigCycleTime" SG_ 261 IxbrReqAxle1_WhlSlipLimHiRi 100;
BA_ "GenSigCycleTimeActive" SG_ 261 IxbrReqAxle1_WhlSlipLimHiRi 100;
BA_ "GenSigStartValue" SG_ 261 IxbrReqAxle1_WhlSlipLimHiRi 511;
BA_ "GenSigCycleTime" SG_ 261 IxbrReqAxle2_IxbrModReq 100;
BA_ "GenSigCycleTimeActive" SG_ 261 IxbrReqAxle2_IxbrModReq 100;
BA_ "GenSigStartValue" SG_ 261 IxbrReqAxle2_IxbrModReq 7;
BA_ "GenSigCycleTime" SG_ 261 IxbrReqAxle3_WhlSlipLimLoLe 100;
BA_ "GenSigCycleTimeActive" SG_ 261 IxbrReqAxle3_WhlSlipLimLoLe 100;
BA_ "GenSigStartValue" SG_ 261 IxbrReqAxle3_WhlSlipLimLoLe 511;
BA_ "GenSigCycleTime" SG_ 261 IxbrReqAxle2_SqC 100;
BA_ "GenSigCycleTimeActive" SG_ 261 IxbrReqAxle2_SqC 100;
BA_ "GenSigStartValue" SG_ 261 IxbrReqAxle2_SqC 14;
BA_ "GenSigCycleTime" SG_ 261 IxbrReqAxle1_VehSpdLgtWhlLe 100;
BA_ "GenSigCycleTimeActive" SG_ 261 IxbrReqAxle1_VehSpdLgtWhlLe 100;
BA_ "GenSigStartValue" SG_ 261 IxbrReqAxle1_VehSpdLgtWhlLe 8191;
BA_ "GenSigCycleTime" SG_ 261 IxbrReqAxle3_VehSpdLgtWhlRi 100;
BA_ "GenSigCycleTimeActive" SG_ 261 IxbrReqAxle3_VehSpdLgtWhlRi 100;
BA_ "GenSigStartValue" SG_ 261 IxbrReqAxle3_VehSpdLgtWhlRi 8191;
BA_ "GenSigCycleTime" SG_ 261 IxbrReqAxle3_WhlSlipLimHiRi 100;
BA_ "GenSigCycleTimeActive" SG_ 261 IxbrReqAxle3_WhlSlipLimHiRi 100;
BA_ "GenSigStartValue" SG_ 261 IxbrReqAxle3_WhlSlipLimHiRi 511;
BA_ "GenSigCycleTime" SG_ 261 IxbrReqAxle2_WhlSlipLimLoLe 100;
BA_ "GenSigCycleTimeActive" SG_ 261 IxbrReqAxle2_WhlSlipLimLoLe 100;
BA_ "GenSigStartValue" SG_ 261 IxbrReqAxle2_WhlSlipLimLoLe 511;
BA_ "GenSigCycleTime" SG_ 261 IxbrReqAxle2_VehSpdLgtWhlLe 100;
BA_ "GenSigCycleTimeActive" SG_ 261 IxbrReqAxle2_VehSpdLgtWhlLe 100;
BA_ "GenSigStartValue" SG_ 261 IxbrReqAxle2_VehSpdLgtWhlLe 8191;
BA_ "GenSigCycleTime" SG_ 261 IxbrReqAxle2_WhlSlipLimHiLe 100;
BA_ "GenSigCycleTimeActive" SG_ 261 IxbrReqAxle2_WhlSlipLimHiLe 100;
BA_ "GenSigStartValue" SG_ 261 IxbrReqAxle2_WhlSlipLimHiLe 511;
BA_ "GenSigCycleTime" SG_ 261 IxbrReqAxle3_VehSpdLgtWhlQltyRi 100;
BA_ "GenSigCycleTimeActive" SG_ 261 IxbrReqAxle3_VehSpdLgtWhlQltyRi 100;
BA_ "GenSigStartValue" SG_ 261 IxbrReqAxle3_VehSpdLgtWhlQltyRi 15;
BA_ "GenSigCycleTime" SG_ 261 IxbrReqAxle1_VehSpdLgtWhlQltyLe 100;
BA_ "GenSigCycleTimeActive" SG_ 261 IxbrReqAxle1_VehSpdLgtWhlQltyLe 100;
BA_ "GenSigStartValue" SG_ 261 IxbrReqAxle1_VehSpdLgtWhlQltyLe 15;
BA_ "GenSigCycleTime" SG_ 261 IxbrReqAxle1_BrkTqReqRi 100;
BA_ "GenSigCycleTimeActive" SG_ 261 IxbrReqAxle1_BrkTqReqRi 100;
BA_ "GenSigStartValue" SG_ 261 IxbrReqAxle1_BrkTqReqRi 8191;
BA_ "GenSigCycleTime" SG_ 261 IxbrReqAxle1_VehSpdLgtWhlRi 100;
BA_ "GenSigCycleTimeActive" SG_ 261 IxbrReqAxle1_VehSpdLgtWhlRi 100;
BA_ "GenSigStartValue" SG_ 261 IxbrReqAxle1_VehSpdLgtWhlRi 8191;
BA_ "GenSigCycleTime" SG_ 261 IxbrReqAxle3_IxbrModReq 100;
BA_ "GenSigCycleTimeActive" SG_ 261 IxbrReqAxle3_IxbrModReq 100;
BA_ "GenSigStartValue" SG_ 261 IxbrReqAxle3_IxbrModReq 7;
BA_ "GenSigCycleTime" SG_ 261 IxbrReqAxle2_CRC 100;
BA_ "GenSigCycleTimeActive" SG_ 261 IxbrReqAxle2_CRC 100;
BA_ "GenSigStartValue" SG_ 261 IxbrReqAxle2_CRC 255;
BA_ "E2EDataId" SG_ 261 IxbrReqAxle2_CRC 216;
BA_ "E2EDataLength" SG_ 261 IxbrReqAxle2_CRC 120;
BA_ "E2EProfile" SG_ 261 IxbrReqAxle2_CRC "P01";
BA_ "GenSigCycleTime" SG_ 261 IxbrReqAxle2_VehSpdLgtWhlQltyLe 100;
BA_ "GenSigCycleTimeActive" SG_ 261 IxbrReqAxle2_VehSpdLgtWhlQltyLe 100;
BA_ "GenSigStartValue" SG_ 261 IxbrReqAxle2_VehSpdLgtWhlQltyLe 15;
BA_ "GenSigCycleTime" SG_ 261 IxbrReqAxle3_VehSpdLgtWhlLe 100;
BA_ "GenSigCycleTimeActive" SG_ 261 IxbrReqAxle3_VehSpdLgtWhlLe 100;
BA_ "GenSigStartValue" SG_ 261 IxbrReqAxle3_VehSpdLgtWhlLe 8191;
BA_ "GenSigCycleTime" SG_ 261 IxbrReqAxle3_SlipCtrlEna 100;
BA_ "GenSigCycleTimeActive" SG_ 261 IxbrReqAxle3_SlipCtrlEna 100;
BA_ "GenSigStartValue" SG_ 261 IxbrReqAxle3_SlipCtrlEna 3;
BA_ "GenSigCycleTime" SG_ 261 IxbrReqAxle3_CRC 100;
BA_ "GenSigCycleTimeActive" SG_ 261 IxbrReqAxle3_CRC 100;
BA_ "GenSigStartValue" SG_ 261 IxbrReqAxle3_CRC 255;
BA_ "E2EDataId" SG_ 261 IxbrReqAxle3_CRC 217;
BA_ "E2EDataLength" SG_ 261 IxbrReqAxle3_CRC 120;
BA_ "E2EProfile" SG_ 261 IxbrReqAxle3_CRC "P01";
BA_ "GenSigCycleTime" SG_ 261 IxbrReqAxle2_VehSpdLgtWhlRi 100;
BA_ "GenSigCycleTimeActive" SG_ 261 IxbrReqAxle2_VehSpdLgtWhlRi 100;
BA_ "GenSigStartValue" SG_ 261 IxbrReqAxle2_VehSpdLgtWhlRi 8191;
BA_ "GenSigCycleTime" SG_ 261 IxbrReqAxle2_VehSpdLgtWhlQltyRi 100;
BA_ "GenSigCycleTimeActive" SG_ 261 IxbrReqAxle2_VehSpdLgtWhlQltyRi 100;
BA_ "GenSigStartValue" SG_ 261 IxbrReqAxle2_VehSpdLgtWhlQltyRi 15;
BA_ "GenSigCycleTime" SG_ 261 IxbrReqAxle1_CRC 100;
BA_ "GenSigCycleTimeActive" SG_ 261 IxbrReqAxle1_CRC 100;
BA_ "GenSigStartValue" SG_ 261 IxbrReqAxle1_CRC 255;
BA_ "E2EDataId" SG_ 261 IxbrReqAxle1_CRC 215;
BA_ "E2EDataLength" SG_ 261 IxbrReqAxle1_CRC 120;
BA_ "E2EProfile" SG_ 261 IxbrReqAxle1_CRC "P01";
BA_ "GenSigCycleTime" SG_ 554 EstAxle3_LoadNormLe 100;
BA_ "GenSigCycleTimeActive" SG_ 554 EstAxle3_LoadNormLe 100;
BA_ "GenSigStartValue" SG_ 554 EstAxle3_LoadNormLe 255;
BA_ "GenSigCycleTime" SG_ 554 EstAxle6_WhlRdEstQltyRi 100;
BA_ "GenSigCycleTimeActive" SG_ 554 EstAxle6_WhlRdEstQltyRi 100;
BA_ "GenSigStartValue" SG_ 554 EstAxle6_WhlRdEstQltyRi 15;
BA_ "GenSigCycleTime" SG_ 554 EstAxle5_WhlRdEstQltyRi 100;
BA_ "GenSigCycleTimeActive" SG_ 554 EstAxle5_WhlRdEstQltyRi 100;
BA_ "GenSigStartValue" SG_ 554 EstAxle5_WhlRdEstQltyRi 15;
BA_ "GenSigCycleTime" SG_ 554 EstAxle2_LoadNormQltyLe 100;
BA_ "GenSigCycleTimeActive" SG_ 554 EstAxle2_LoadNormQltyLe 100;
BA_ "GenSigStartValue" SG_ 554 EstAxle2_LoadNormQltyLe 15;
BA_ "GenSigCycleTime" SG_ 554 EstAxle3_LoadNormQltyRi 100;
BA_ "GenSigCycleTimeActive" SG_ 554 EstAxle3_LoadNormQltyRi 100;
BA_ "GenSigStartValue" SG_ 554 EstAxle3_LoadNormQltyRi 15;
BA_ "GenSigCycleTime" SG_ 554 EstAxle6_SqC 100;
BA_ "GenSigCycleTimeActive" SG_ 554 EstAxle6_SqC 100;
BA_ "GenSigStartValue" SG_ 554 EstAxle6_SqC 14;
BA_ "GenSigCycleTime" SG_ 554 EstAxle4_LoadNormQltyRi 100;
BA_ "GenSigCycleTimeActive" SG_ 554 EstAxle4_LoadNormQltyRi 100;
BA_ "GenSigStartValue" SG_ 554 EstAxle4_LoadNormQltyRi 15;
BA_ "GenSigCycleTime" SG_ 554 EstAxle6_LoadNormRi 100;
BA_ "GenSigCycleTimeActive" SG_ 554 EstAxle6_LoadNormRi 100;
BA_ "GenSigStartValue" SG_ 554 EstAxle6_LoadNormRi 255;
BA_ "GenSigCycleTime" SG_ 554 EstAxle5_SqC 100;
BA_ "GenSigCycleTimeActive" SG_ 554 EstAxle5_SqC 100;
BA_ "GenSigStartValue" SG_ 554 EstAxle5_SqC 14;
BA_ "GenSigCycleTime" SG_ 554 EstAxle6_CRC 100;
BA_ "GenSigCycleTimeActive" SG_ 554 EstAxle6_CRC 100;
BA_ "GenSigStartValue" SG_ 554 EstAxle6_CRC 255;
BA_ "E2EDataId" SG_ 554 EstAxle6_CRC 214;
BA_ "E2EDataLength" SG_ 554 EstAxle6_CRC 64;
BA_ "E2EProfile" SG_ 554 EstAxle6_CRC "P01";
BA_ "GenSigCycleTime" SG_ 554 EstAxle2_WhlRdEstLe 100;
BA_ "GenSigCycleTimeActive" SG_ 554 EstAxle2_WhlRdEstLe 100;
BA_ "GenSigStartValue" SG_ 554 EstAxle2_WhlRdEstLe 1023;
BA_ "GenSigCycleTime" SG_ 554 EstAxle3_WhlRdEstRi 100;
BA_ "GenSigCycleTimeActive" SG_ 554 EstAxle3_WhlRdEstRi 100;
BA_ "GenSigStartValue" SG_ 554 EstAxle3_WhlRdEstRi 1023;
BA_ "GenSigCycleTime" SG_ 554 EstAxle5_LoadNormQltyRi 100;
BA_ "GenSigCycleTimeActive" SG_ 554 EstAxle5_LoadNormQltyRi 100;
BA_ "GenSigStartValue" SG_ 554 EstAxle5_LoadNormQltyRi 15;
BA_ "GenSigCycleTime" SG_ 554 EstAxle6_WhlRdEstLe 100;
BA_ "GenSigCycleTimeActive" SG_ 554 EstAxle6_WhlRdEstLe 100;
BA_ "GenSigStartValue" SG_ 554 EstAxle6_WhlRdEstLe 1023;
BA_ "GenSigCycleTime" SG_ 554 EstAxle6_WhlRdEstQltyLe 100;
BA_ "GenSigCycleTimeActive" SG_ 554 EstAxle6_WhlRdEstQltyLe 100;
BA_ "GenSigStartValue" SG_ 554 EstAxle6_WhlRdEstQltyLe 15;
BA_ "GenSigCycleTime" SG_ 554 EstAxle6_LoadNormLe 100;
BA_ "GenSigCycleTimeActive" SG_ 554 EstAxle6_LoadNormLe 100;
BA_ "GenSigStartValue" SG_ 554 EstAxle6_LoadNormLe 255;
BA_ "GenSigCycleTime" SG_ 554 EstAxle5_LoadNormRi 100;
BA_ "GenSigCycleTimeActive" SG_ 554 EstAxle5_LoadNormRi 100;
BA_ "GenSigStartValue" SG_ 554 EstAxle5_LoadNormRi 255;
BA_ "GenSigCycleTime" SG_ 554 EstAxle5_LoadNormQltyLe 100;
BA_ "GenSigCycleTimeActive" SG_ 554 EstAxle5_LoadNormQltyLe 100;
BA_ "GenSigStartValue" SG_ 554 EstAxle5_LoadNormQltyLe 15;
BA_ "GenSigCycleTime" SG_ 554 EstAxle5_CRC 100;
BA_ "GenSigCycleTimeActive" SG_ 554 EstAxle5_CRC 100;
BA_ "GenSigStartValue" SG_ 554 EstAxle5_CRC 255;
BA_ "E2EDataId" SG_ 554 EstAxle5_CRC 213;
BA_ "E2EDataLength" SG_ 554 EstAxle5_CRC 64;
BA_ "E2EProfile" SG_ 554 EstAxle5_CRC "P01";
BA_ "GenSigCycleTime" SG_ 554 EstAxle1_WhlRdEstRi 100;
BA_ "GenSigCycleTimeActive" SG_ 554 EstAxle1_WhlRdEstRi 100;
BA_ "GenSigStartValue" SG_ 554 EstAxle1_WhlRdEstRi 1023;
BA_ "GenSigCycleTime" SG_ 554 EstAxle4_LoadNormRi 100;
BA_ "GenSigCycleTimeActive" SG_ 554 EstAxle4_LoadNormRi 100;
BA_ "GenSigStartValue" SG_ 554 EstAxle4_LoadNormRi 255;
BA_ "GenSigCycleTime" SG_ 554 EstAxle3_WhlRdEstQltyLe 100;
BA_ "GenSigCycleTimeActive" SG_ 554 EstAxle3_WhlRdEstQltyLe 100;
BA_ "GenSigStartValue" SG_ 554 EstAxle3_WhlRdEstQltyLe 15;
BA_ "GenSigCycleTime" SG_ 554 EstAxle4_WhlRdEstRi 100;
BA_ "GenSigCycleTimeActive" SG_ 554 EstAxle4_WhlRdEstRi 100;
BA_ "GenSigStartValue" SG_ 554 EstAxle4_WhlRdEstRi 1023;
BA_ "GenSigCycleTime" SG_ 554 EstAxle6_WhlRdEstRi 100;
BA_ "GenSigCycleTimeActive" SG_ 554 EstAxle6_WhlRdEstRi 100;
BA_ "GenSigStartValue" SG_ 554 EstAxle6_WhlRdEstRi 1023;
BA_ "GenSigCycleTime" SG_ 554 EstAxle5_LoadNormLe 100;
BA_ "GenSigCycleTimeActive" SG_ 554 EstAxle5_LoadNormLe 100;
BA_ "GenSigStartValue" SG_ 554 EstAxle5_LoadNormLe 255;
BA_ "GenSigCycleTime" SG_ 554 EstAxle5_WhlRdEstLe 100;
BA_ "GenSigCycleTimeActive" SG_ 554 EstAxle5_WhlRdEstLe 100;
BA_ "GenSigStartValue" SG_ 554 EstAxle5_WhlRdEstLe 1023;
BA_ "GenSigCycleTime" SG_ 554 EstAxle3_CRC 100;
BA_ "GenSigCycleTimeActive" SG_ 554 EstAxle3_CRC 100;
BA_ "GenSigStartValue" SG_ 554 EstAxle3_CRC 255;
BA_ "E2EDataId" SG_ 554 EstAxle3_CRC 211;
BA_ "E2EDataLength" SG_ 554 EstAxle3_CRC 64;
BA_ "E2EProfile" SG_ 554 EstAxle3_CRC "P01";
BA_ "GenSigCycleTime" SG_ 554 EstAxle2_LoadNormRi 100;
BA_ "GenSigCycleTimeActive" SG_ 554 EstAxle2_LoadNormRi 100;
BA_ "GenSigStartValue" SG_ 554 EstAxle2_LoadNormRi 255;
BA_ "GenSigCycleTime" SG_ 554 EstAxle4_SqC 100;
BA_ "GenSigCycleTimeActive" SG_ 554 EstAxle4_SqC 100;
BA_ "GenSigStartValue" SG_ 554 EstAxle4_SqC 14;
BA_ "GenSigCycleTime" SG_ 554 EstAxle4_WhlRdEstQltyRi 100;
BA_ "GenSigCycleTimeActive" SG_ 554 EstAxle4_WhlRdEstQltyRi 100;
BA_ "GenSigStartValue" SG_ 554 EstAxle4_WhlRdEstQltyRi 15;
BA_ "GenSigCycleTime" SG_ 554 EstAxle6_LoadNormQltyRi 100;
BA_ "GenSigCycleTimeActive" SG_ 554 EstAxle6_LoadNormQltyRi 100;
BA_ "GenSigStartValue" SG_ 554 EstAxle6_LoadNormQltyRi 15;
BA_ "GenSigCycleTime" SG_ 554 EstAxle1_LoadNormQltyRi 100;
BA_ "GenSigCycleTimeActive" SG_ 554 EstAxle1_LoadNormQltyRi 100;
BA_ "GenSigStartValue" SG_ 554 EstAxle1_LoadNormQltyRi 15;
BA_ "GenSigCycleTime" SG_ 554 EstAxle1_LoadNormQltyLe 100;
BA_ "GenSigCycleTimeActive" SG_ 554 EstAxle1_LoadNormQltyLe 100;
BA_ "GenSigStartValue" SG_ 554 EstAxle1_LoadNormQltyLe 15;
BA_ "GenSigCycleTime" SG_ 554 EstAxle2_LoadNormLe 100;
BA_ "GenSigCycleTimeActive" SG_ 554 EstAxle2_LoadNormLe 100;
BA_ "GenSigStartValue" SG_ 554 EstAxle2_LoadNormLe 255;
BA_ "GenSigCycleTime" SG_ 554 EstAxle4_WhlRdEstQltyLe 100;
BA_ "GenSigCycleTimeActive" SG_ 554 EstAxle4_WhlRdEstQltyLe 100;
BA_ "GenSigStartValue" SG_ 554 EstAxle4_WhlRdEstQltyLe 15;
BA_ "GenSigCycleTime" SG_ 554 EstAxle4_WhlRdEstLe 100;
BA_ "GenSigCycleTimeActive" SG_ 554 EstAxle4_WhlRdEstLe 100;
BA_ "GenSigStartValue" SG_ 554 EstAxle4_WhlRdEstLe 1023;
BA_ "GenSigCycleTime" SG_ 554 EstAxle1_WhlRdEstQltyLe 100;
BA_ "GenSigCycleTimeActive" SG_ 554 EstAxle1_WhlRdEstQltyLe 100;
BA_ "GenSigStartValue" SG_ 554 EstAxle1_WhlRdEstQltyLe 15;
BA_ "GenSigCycleTime" SG_ 554 EstAxle2_LoadNormQltyRi 100;
BA_ "GenSigCycleTimeActive" SG_ 554 EstAxle2_LoadNormQltyRi 100;
BA_ "GenSigStartValue" SG_ 554 EstAxle2_LoadNormQltyRi 15;
BA_ "GenSigCycleTime" SG_ 554 EstAxle3_LoadNormQltyLe 100;
BA_ "GenSigCycleTimeActive" SG_ 554 EstAxle3_LoadNormQltyLe 100;
BA_ "GenSigStartValue" SG_ 554 EstAxle3_LoadNormQltyLe 15;
BA_ "GenSigCycleTime" SG_ 554 EstAxle4_LoadNormQltyLe 100;
BA_ "GenSigCycleTimeActive" SG_ 554 EstAxle4_LoadNormQltyLe 100;
BA_ "GenSigStartValue" SG_ 554 EstAxle4_LoadNormQltyLe 15;
BA_ "GenSigCycleTime" SG_ 554 EstAxle2_WhlRdEstQltyRi 100;
BA_ "GenSigCycleTimeActive" SG_ 554 EstAxle2_WhlRdEstQltyRi 100;
BA_ "GenSigStartValue" SG_ 554 EstAxle2_WhlRdEstQltyRi 15;
BA_ "GenSigCycleTime" SG_ 554 EstAxle6_LoadNormQltyLe 100;
BA_ "GenSigCycleTimeActive" SG_ 554 EstAxle6_LoadNormQltyLe 100;
BA_ "GenSigStartValue" SG_ 554 EstAxle6_LoadNormQltyLe 15;
BA_ "GenSigCycleTime" SG_ 554 EstAxle2_WhlRdEstRi 100;
BA_ "GenSigCycleTimeActive" SG_ 554 EstAxle2_WhlRdEstRi 100;
BA_ "GenSigStartValue" SG_ 554 EstAxle2_WhlRdEstRi 1023;
BA_ "GenSigCycleTime" SG_ 554 EstAxle3_WhlRdEstQltyRi 100;
BA_ "GenSigCycleTimeActive" SG_ 554 EstAxle3_WhlRdEstQltyRi 100;
BA_ "GenSigStartValue" SG_ 554 EstAxle3_WhlRdEstQltyRi 15;
BA_ "GenSigCycleTime" SG_ 554 EstAxle1_LoadNormLe 100;
BA_ "GenSigCycleTimeActive" SG_ 554 EstAxle1_LoadNormLe 100;
BA_ "GenSigStartValue" SG_ 554 EstAxle1_LoadNormLe 255;
BA_ "GenSigCycleTime" SG_ 554 EstAxle1_CRC 100;
BA_ "GenSigCycleTimeActive" SG_ 554 EstAxle1_CRC 100;
BA_ "GenSigStartValue" SG_ 554 EstAxle1_CRC 255;
BA_ "E2EDataId" SG_ 554 EstAxle1_CRC 209;
BA_ "E2EDataLength" SG_ 554 EstAxle1_CRC 64;
BA_ "E2EProfile" SG_ 554 EstAxle1_CRC "P01";
BA_ "GenSigCycleTime" SG_ 554 EstAxle5_WhlRdEstRi 100;
BA_ "GenSigCycleTimeActive" SG_ 554 EstAxle5_WhlRdEstRi 100;
BA_ "GenSigStartValue" SG_ 554 EstAxle5_WhlRdEstRi 1023;
BA_ "GenSigCycleTime" SG_ 554 EstAxle2_CRC 100;
BA_ "GenSigCycleTimeActive" SG_ 554 EstAxle2_CRC 100;
BA_ "GenSigStartValue" SG_ 554 EstAxle2_CRC 255;
BA_ "E2EDataId" SG_ 554 EstAxle2_CRC 210;
BA_ "E2EDataLength" SG_ 554 EstAxle2_CRC 64;
BA_ "E2EProfile" SG_ 554 EstAxle2_CRC "P01";
BA_ "GenSigCycleTime" SG_ 554 EstAxle1_LoadNormRi 100;
BA_ "GenSigCycleTimeActive" SG_ 554 EstAxle1_LoadNormRi 100;
BA_ "GenSigStartValue" SG_ 554 EstAxle1_LoadNormRi 255;
BA_ "GenSigCycleTime" SG_ 554 EstAxle2_WhlRdEstQltyLe 100;
BA_ "GenSigCycleTimeActive" SG_ 554 EstAxle2_WhlRdEstQltyLe 100;
BA_ "GenSigStartValue" SG_ 554 EstAxle2_WhlRdEstQltyLe 15;
BA_ "GenSigCycleTime" SG_ 554 EstAxle4_CRC 100;
BA_ "GenSigCycleTimeActive" SG_ 554 EstAxle4_CRC 100;
BA_ "GenSigStartValue" SG_ 554 EstAxle4_CRC 255;
BA_ "E2EDataId" SG_ 554 EstAxle4_CRC 212;
BA_ "E2EDataLength" SG_ 554 EstAxle4_CRC 64;
BA_ "E2EProfile" SG_ 554 EstAxle4_CRC "P01";
BA_ "GenSigCycleTime" SG_ 554 EstAxle3_LoadNormRi 100;
BA_ "GenSigCycleTimeActive" SG_ 554 EstAxle3_LoadNormRi 100;
BA_ "GenSigStartValue" SG_ 554 EstAxle3_LoadNormRi 255;
BA_ "GenSigCycleTime" SG_ 554 EstAxle5_WhlRdEstQltyLe 100;
BA_ "GenSigCycleTimeActive" SG_ 554 EstAxle5_WhlRdEstQltyLe 100;
BA_ "GenSigStartValue" SG_ 554 EstAxle5_WhlRdEstQltyLe 15;
BA_ "GenSigCycleTime" SG_ 554 EstAxle3_SqC 100;
BA_ "GenSigCycleTimeActive" SG_ 554 EstAxle3_SqC 100;
BA_ "GenSigStartValue" SG_ 554 EstAxle3_SqC 14;
BA_ "GenSigCycleTime" SG_ 554 EstAxle1_WhlRdEstLe 100;
BA_ "GenSigCycleTimeActive" SG_ 554 EstAxle1_WhlRdEstLe 100;
BA_ "GenSigStartValue" SG_ 554 EstAxle1_WhlRdEstLe 1023;
BA_ "GenSigCycleTime" SG_ 554 EstAxle4_LoadNormLe 100;
BA_ "GenSigCycleTimeActive" SG_ 554 EstAxle4_LoadNormLe 100;
BA_ "GenSigStartValue" SG_ 554 EstAxle4_LoadNormLe 255;
BA_ "GenSigCycleTime" SG_ 554 EstAxle1_SqC 100;
BA_ "GenSigCycleTimeActive" SG_ 554 EstAxle1_SqC 100;
BA_ "GenSigStartValue" SG_ 554 EstAxle1_SqC 14;
BA_ "GenSigCycleTime" SG_ 554 EstAxle1_WhlRdEstQltyRi 100;
BA_ "GenSigCycleTimeActive" SG_ 554 EstAxle1_WhlRdEstQltyRi 100;
BA_ "GenSigStartValue" SG_ 554 EstAxle1_WhlRdEstQltyRi 15;
BA_ "GenSigCycleTime" SG_ 554 EstAxle2_SqC 100;
BA_ "GenSigCycleTimeActive" SG_ 554 EstAxle2_SqC 100;
BA_ "GenSigStartValue" SG_ 554 EstAxle2_SqC 14;
BA_ "GenSigCycleTime" SG_ 554 EstAxle3_WhlRdEstLe 100;
BA_ "GenSigCycleTimeActive" SG_ 554 EstAxle3_WhlRdEstLe 100;
BA_ "GenSigStartValue" SG_ 554 EstAxle3_WhlRdEstLe 1023;
BA_ "GenSigCycleTime" SG_ 631 APM_LowAirPressureAlert 100;
BA_ "GenSigCycleTimeActive" SG_ 631 APM_LowAirPressureAlert 100;
BA_ "GenSigStartValue" SG_ 631 APM_LowAirPressureAlert 3;
BA_ "GenSigMaxLatency" SG_ 631 APM_LowAirPressureAlert 50;
BA_ "GenSigCycleTime" SG_ 631 APM_PBChamberAirPressure 100;
BA_ "GenSigCycleTimeActive" SG_ 631 APM_PBChamberAirPressure 100;
BA_ "GenSigStartValue" SG_ 631 APM_PBChamberAirPressure 255;
BA_ "GenSigMaxLatency" SG_ 631 APM_PBChamberAirPressure 50;
BA_ "GenSigCycleTime" SG_ 631 EPBHSARequest 100;
BA_ "GenSigCycleTimeActive" SG_ 631 EPBHSARequest 100;
BA_ "GenSigStartValue" SG_ 631 EPBHSARequest 7;
BA_ "GenSigMaxLatency" SG_ 631 EPBHSARequest 50;
BA_ "GenSigSendType" SG_ 631 APM_ParkBrakeActuationStatus_UB 7;
BA_ "GenSigCycleTime" SG_ 631 APM_ParkBrakeActuationStatus 100;
BA_ "GenSigCycleTimeActive" SG_ 631 APM_ParkBrakeActuationStatus 100;
BA_ "GenSigStartValue" SG_ 631 APM_ParkBrakeActuationStatus 7;
BA_ "GenSigMaxLatency" SG_ 631 APM_ParkBrakeActuationStatus 50;
BA_ "NeedsUpdateBit" SG_ 631 APM_ParkBrakeActuationStatus 1;
BA_ "GenSigCycleTime" SG_ 1448 TotalVehicleDistanceHighRes 100;
BA_ "GenSigCycleTimeActive" SG_ 1448 TotalVehicleDistanceHighRes 100;
BA_ "GenSigStartValue" SG_ 1448 TotalVehicleDistanceHighRes 4294967295;
BA_ "GenSigCycleTime" SG_ 1448 AmbientAirTemperature 100;
BA_ "GenSigCycleTimeActive" SG_ 1448 AmbientAirTemperature 100;
BA_ "GenSigStartValue" SG_ 1448 AmbientAirTemperature 65535;
BA_ "GenSigCycleTime" SG_ 1319 YearUTC 100;
BA_ "GenSigCycleTimeActive" SG_ 1319 YearUTC 100;
BA_ "GenSigStartValue" SG_ 1319 YearUTC 255;
BA_ "GenSigCycleTime" SG_ 1319 SecondsUTC 100;
BA_ "GenSigCycleTimeActive" SG_ 1319 SecondsUTC 100;
BA_ "GenSigStartValue" SG_ 1319 SecondsUTC 255;
BA_ "GenSigCycleTime" SG_ 1319 DayUTC 100;
BA_ "GenSigCycleTimeActive" SG_ 1319 DayUTC 100;
BA_ "GenSigStartValue" SG_ 1319 DayUTC 255;
BA_ "GenSigCycleTime" SG_ 1319 MonthUTC 100;
BA_ "GenSigCycleTimeActive" SG_ 1319 MonthUTC 100;
BA_ "GenSigStartValue" SG_ 1319 MonthUTC 255;
BA_ "GenSigCycleTime" SG_ 1319 HoursUTC 100;
BA_ "GenSigCycleTimeActive" SG_ 1319 HoursUTC 100;
BA_ "GenSigStartValue" SG_ 1319 HoursUTC 255;
BA_ "GenSigCycleTime" SG_ 1319 MinutesUTC 100;
BA_ "GenSigCycleTimeActive" SG_ 1319 MinutesUTC 100;
BA_ "GenSigStartValue" SG_ 1319 MinutesUTC 255;
BA_ "GenSigCycleTime" SG_ 1447 FasDampingSetting_rqst 100;
BA_ "GenSigCycleTimeActive" SG_ 1447 FasDampingSetting_rqst 100;
BA_ "GenSigStartValue" SG_ 1447 FasDampingSetting_rqst 31;
BA_ "GenSigMaxLatency" SG_ 1447 FasDampingSetting_rqst 1000;
BA_ "GenSigCycleTime" SG_ 1447 DriverMemory_rqst 100;
BA_ "GenSigCycleTimeActive" SG_ 1447 DriverMemory_rqst 100;
BA_ "GenSigStartValue" SG_ 1447 DriverMemory_rqst 31;
BA_ "GenSigMaxLatency" SG_ 1447 DriverMemory_rqst 1000;
BA_ "GenSigCycleTime" SG_ 1447 FasDriver_rqst 100;
BA_ "GenSigCycleTimeActive" SG_ 1447 FasDriver_rqst 100;
BA_ "GenSigStartValue" SG_ 1447 FasDriver_rqst 15;
BA_ "GenSigMaxLatency" SG_ 1447 FasDriver_rqst 1000;
BA_ "GenSigCycleTime" SG_ 1447 FasLowSpeedReturnSetting_rqst 100;
BA_ "GenSigCycleTimeActive" SG_ 1447 FasLowSpeedReturnSetting_rqst 100;
BA_ "GenSigStartValue" SG_ 1447 FasLowSpeedReturnSetting_rqst 31;
BA_ "GenSigMaxLatency" SG_ 1447 FasLowSpeedReturnSetting_rqst 1000;
BA_ "GenSigCycleTime" SG_ 1447 FasPersonalSettingsButton_rqst 100;
BA_ "GenSigCycleTimeActive" SG_ 1447 FasPersonalSettingsButton_rqst 100;
BA_ "GenSigStartValue" SG_ 1447 FasPersonalSettingsButton_rqst 7;
BA_ "GenSigMaxLatency" SG_ 1447 FasPersonalSettingsButton_rqst 1000;
BA_ "GenSigCycleTime" SG_ 1447 FasStiffnessCurveSetting_rqst 100;
BA_ "GenSigCycleTimeActive" SG_ 1447 FasStiffnessCurveSetting_rqst 100;
BA_ "GenSigStartValue" SG_ 1447 FasStiffnessCurveSetting_rqst 31;
BA_ "GenSigMaxLatency" SG_ 1447 FasStiffnessCurveSetting_rqst 1000;
BA_ "GenSigCycleTime" SG_ 1447 FasUsrDefinedStorage_rqst 100;
BA_ "GenSigCycleTimeActive" SG_ 1447 FasUsrDefinedStorage_rqst 100;
BA_ "GenSigStartValue" SG_ 1447 FasUsrDefinedStorage_rqst 3;
BA_ "GenSigMaxLatency" SG_ 1447 FasUsrDefinedStorage_rqst 1000;
BA_ "GenSigCycleTime" SG_ 1447 FasManualOffsetSetting_rqst 100;
BA_ "GenSigCycleTimeActive" SG_ 1447 FasManualOffsetSetting_rqst 100;
BA_ "GenSigStartValue" SG_ 1447 FasManualOffsetSetting_rqst 31;
BA_ "GenSigMaxLatency" SG_ 1447 FasManualOffsetSetting_rqst 1000;
BA_ "GenSigCycleTime" SG_ 1447 FasStiffStraightSetting_rqst 100;
BA_ "GenSigCycleTimeActive" SG_ 1447 FasStiffStraightSetting_rqst 100;
BA_ "GenSigStartValue" SG_ 1447 FasStiffStraightSetting_rqst 31;
BA_ "GenSigMaxLatency" SG_ 1447 FasStiffStraightSetting_rqst 1000;
BA_ "GenSigCycleTime" SG_ 1034 RelativeLevelFrontAxleLeft 100;
BA_ "GenSigCycleTimeActive" SG_ 1034 RelativeLevelFrontAxleLeft 100;
BA_ "GenSigStartValue" SG_ 1034 RelativeLevelFrontAxleLeft 65535;
BA_ "GenSigMaxLatency" SG_ 1034 RelativeLevelFrontAxleLeft 100;
BA_ "GenSigCycleTime" SG_ 1034 FrontAxle1Load 100;
BA_ "GenSigCycleTimeActive" SG_ 1034 FrontAxle1Load 100;
BA_ "GenSigStartValue" SG_ 1034 FrontAxle1Load 65535;
BA_ "GenSigMaxLatency" SG_ 1034 FrontAxle1Load 100;
BA_ "GenSigCycleTime" SG_ 1034 PusherAxleLoad 100;
BA_ "GenSigCycleTimeActive" SG_ 1034 PusherAxleLoad 100;
BA_ "GenSigStartValue" SG_ 1034 PusherAxleLoad 65535;
BA_ "GenSigMaxLatency" SG_ 1034 PusherAxleLoad 100;
BA_ "GenSigCycleTime" SG_ 1034 SecondaryDriveAxleLoad 100;
BA_ "GenSigCycleTimeActive" SG_ 1034 SecondaryDriveAxleLoad 100;
BA_ "GenSigStartValue" SG_ 1034 SecondaryDriveAxleLoad 65535;
BA_ "GenSigMaxLatency" SG_ 1034 SecondaryDriveAxleLoad 100;
BA_ "GenSigCycleTime" SG_ 1034 TagAxleLoad 100;
BA_ "GenSigCycleTimeActive" SG_ 1034 TagAxleLoad 100;
BA_ "GenSigStartValue" SG_ 1034 TagAxleLoad 65535;
BA_ "GenSigMaxLatency" SG_ 1034 TagAxleLoad 100;
BA_ "GenSigCycleTime" SG_ 1034 ContTrailerBrake_MsgCounter 100;
BA_ "GenSigCycleTimeActive" SG_ 1034 ContTrailerBrake_MsgCounter 100;
BA_ "GenSigStartValue" SG_ 1034 ContTrailerBrake_MsgCounter 15;
BA_ "GenSigMaxLatency" SG_ 1034 ContTrailerBrake_MsgCounter 100;
BA_ "GenSigCycleTime" SG_ 1034 FrontAxle2Load 100;
BA_ "GenSigCycleTimeActive" SG_ 1034 FrontAxle2Load 100;
BA_ "GenSigStartValue" SG_ 1034 FrontAxle2Load 65535;
BA_ "GenSigMaxLatency" SG_ 1034 FrontAxle2Load 100;
BA_ "GenSigCycleTime" SG_ 1034 DriveAxleLoad 100;
BA_ "GenSigCycleTimeActive" SG_ 1034 DriveAxleLoad 100;
BA_ "GenSigStartValue" SG_ 1034 DriveAxleLoad 65535;
BA_ "GenSigMaxLatency" SG_ 1034 DriveAxleLoad 100;
BA_ "GenSigCycleTime" SG_ 1034 PBAirLvl_AntiCompoundRatio 100;
BA_ "GenSigCycleTimeActive" SG_ 1034 PBAirLvl_AntiCompoundRatio 100;
BA_ "GenSigStartValue" SG_ 1034 PBAirLvl_AntiCompoundRatio 255;
BA_ "GenSigMaxLatency" SG_ 1034 PBAirLvl_AntiCompoundRatio 100;
BA_ "GenSigCycleTime" SG_ 1034 ContTrailerBrake_MsgChecksum 100;
BA_ "GenSigCycleTimeActive" SG_ 1034 ContTrailerBrake_MsgChecksum 100;
BA_ "GenSigStartValue" SG_ 1034 ContTrailerBrake_MsgChecksum 31;
BA_ "GenSigMaxLatency" SG_ 1034 ContTrailerBrake_MsgChecksum 100;
BA_ "GenSigCycleTime" SG_ 1034 PBAirLvl_SqC 100;
BA_ "GenSigCycleTimeActive" SG_ 1034 PBAirLvl_SqC 100;
BA_ "GenSigStartValue" SG_ 1034 PBAirLvl_SqC 14;
BA_ "GenSigMaxLatency" SG_ 1034 PBAirLvl_SqC 100;
BA_ "GenSigCycleTime" SG_ 1034 PBStatus_CRC 100;
BA_ "GenSigCycleTimeActive" SG_ 1034 PBStatus_CRC 100;
BA_ "GenSigStartValue" SG_ 1034 PBStatus_CRC 255;
BA_ "GenSigMaxLatency" SG_ 1034 PBStatus_CRC 100;
BA_ "E2EDataId" SG_ 1034 PBStatus_CRC 107;
BA_ "E2EDataLength" SG_ 1034 PBStatus_CRC 24;
BA_ "E2EProfile" SG_ 1034 PBStatus_CRC "P01";
BA_ "GenSigCycleTime" SG_ 1034 TertiaryDriveAxleLoad 100;
BA_ "GenSigCycleTimeActive" SG_ 1034 TertiaryDriveAxleLoad 100;
BA_ "GenSigStartValue" SG_ 1034 TertiaryDriveAxleLoad 65535;
BA_ "GenSigMaxLatency" SG_ 1034 TertiaryDriveAxleLoad 250;
BA_ "GenSigCycleTime" SG_ 1034 PBStatus_Actuation 100;
BA_ "GenSigCycleTimeActive" SG_ 1034 PBStatus_Actuation 100;
BA_ "GenSigStartValue" SG_ 1034 PBStatus_Actuation 7;
BA_ "GenSigMaxLatency" SG_ 1034 PBStatus_Actuation 100;
BA_ "GenSigCycleTime" SG_ 1034 PBStatus_SqC 100;
BA_ "GenSigCycleTimeActive" SG_ 1034 PBStatus_SqC 100;
BA_ "GenSigStartValue" SG_ 1034 PBStatus_SqC 14;
BA_ "GenSigMaxLatency" SG_ 1034 PBStatus_SqC 100;
BA_ "GenSigCycleTime" SG_ 1034 PBAirLvl_CRC 100;
BA_ "GenSigCycleTimeActive" SG_ 1034 PBAirLvl_CRC 100;
BA_ "GenSigStartValue" SG_ 1034 PBAirLvl_CRC 255;
BA_ "GenSigMaxLatency" SG_ 1034 PBAirLvl_CRC 100;
BA_ "E2EDataId" SG_ 1034 PBAirLvl_CRC 108;
BA_ "E2EDataLength" SG_ 1034 PBAirLvl_CRC 32;
BA_ "E2EProfile" SG_ 1034 PBAirLvl_CRC "P01";
BA_ "GenSigCycleTime" SG_ 1034 PBStatus_IntegrityLvl 100;
BA_ "GenSigCycleTimeActive" SG_ 1034 PBStatus_IntegrityLvl 100;
BA_ "GenSigStartValue" SG_ 1034 PBStatus_IntegrityLvl 3;
BA_ "GenSigMaxLatency" SG_ 1034 PBStatus_IntegrityLvl 100;
BA_ "GenSigCycleTime" SG_ 1034 ContTrailerBrake_Request 100;
BA_ "GenSigCycleTimeActive" SG_ 1034 ContTrailerBrake_Request 100;
BA_ "GenSigStartValue" SG_ 1034 ContTrailerBrake_Request 7;
BA_ "GenSigMaxLatency" SG_ 1034 ContTrailerBrake_Request 100;
BA_ "GenSigCycleTime" SG_ 1034 PBAirLvl_PressureInChamber 100;
BA_ "GenSigCycleTimeActive" SG_ 1034 PBAirLvl_PressureInChamber 100;
BA_ "GenSigStartValue" SG_ 1034 PBAirLvl_PressureInChamber 255;
BA_ "GenSigMaxLatency" SG_ 1034 PBAirLvl_PressureInChamber 100;
BA_ "GenSigCycleTime" SG_ 426 ChangeKneelACK 100;
BA_ "GenSigCycleTimeActive" SG_ 426 ChangeKneelACK 100;
BA_ "GenSigStartValue" SG_ 426 ChangeKneelACK 3;
BA_ "GenSigMaxLatency" SG_ 426 ChangeKneelACK 20;
BA_ "GenSigCycleTime" SG_ 426 LiftAxle1PositionStatus 100;
BA_ "GenSigCycleTimeActive" SG_ 426 LiftAxle1PositionStatus 100;
BA_ "GenSigStartValue" SG_ 426 LiftAxle1PositionStatus 7;
BA_ "GenSigMaxLatency" SG_ 426 LiftAxle1PositionStatus 20;
BA_ "GenSigCycleTime" SG_ 426 FrontFerryFunctionCmd 100;
BA_ "GenSigCycleTimeActive" SG_ 426 FrontFerryFunctionCmd 100;
BA_ "GenSigStartValue" SG_ 426 FrontFerryFunctionCmd 7;
BA_ "GenSigMaxLatency" SG_ 426 FrontFerryFunctionCmd 20;
BA_ "GenSigSendType" SG_ 426 APM_ParkingBrake_stat_UB 7;
BA_ "GenSigCycleTime" SG_ 426 ReverseGearEngaged 100;
BA_ "GenSigCycleTimeActive" SG_ 426 ReverseGearEngaged 100;
BA_ "GenSigStartValue" SG_ 426 ReverseGearEngaged 3;
BA_ "GenSigMaxLatency" SG_ 426 ReverseGearEngaged 20;
BA_ "GenSigCycleTime" SG_ 426 AirDumpStatus 100;
BA_ "GenSigCycleTimeActive" SG_ 426 AirDumpStatus 100;
BA_ "GenSigStartValue" SG_ 426 AirDumpStatus 7;
BA_ "GenSigMaxLatency" SG_ 426 AirDumpStatus 20;
BA_ "GenSigCycleTime" SG_ 426 EngineActiveStatus 100;
BA_ "GenSigCycleTimeActive" SG_ 426 EngineActiveStatus 100;
BA_ "GenSigStartValue" SG_ 426 EngineActiveStatus 15;
BA_ "GenSigMaxLatency" SG_ 426 EngineActiveStatus 20;
BA_ "GenSigCycleTime" SG_ 426 FerryFunctionStatus 100;
BA_ "GenSigCycleTimeActive" SG_ 426 FerryFunctionStatus 100;
BA_ "GenSigStartValue" SG_ 426 FerryFunctionStatus 7;
BA_ "GenSigMaxLatency" SG_ 426 FerryFunctionStatus 20;
BA_ "GenSigCycleTime" SG_ 426 PitchAngleRef 100;
BA_ "GenSigCycleTimeActive" SG_ 426 PitchAngleRef 100;
BA_ "GenSigStartValue" SG_ 426 PitchAngleRef 65535;
BA_ "GenSigMaxLatency" SG_ 426 PitchAngleRef 20;
BA_ "GenSigCycleTime" SG_ 426 APM_LowVMPBInfoReq 100;
BA_ "GenSigCycleTimeActive" SG_ 426 APM_LowVMPBInfoReq 100;
BA_ "GenSigStartValue" SG_ 426 APM_LowVMPBInfoReq 7;
BA_ "GenSigMaxLatency" SG_ 426 APM_LowVMPBInfoReq 30;
BA_ "GenSigCycleTime" SG_ 426 KneelingInformation 100;
BA_ "GenSigCycleTimeActive" SG_ 426 KneelingInformation 100;
BA_ "GenSigStartValue" SG_ 426 KneelingInformation 15;
BA_ "GenSigMaxLatency" SG_ 426 KneelingInformation 20;
BA_ "GenSigCycleTime" SG_ 426 FASHapticFeedbackRequest 100;
BA_ "GenSigCycleTimeActive" SG_ 426 FASHapticFeedbackRequest 100;
BA_ "GenSigStartValue" SG_ 426 FASHapticFeedbackRequest 15;
BA_ "GenSigMaxLatency" SG_ 426 FASHapticFeedbackRequest 20;
BA_ "GenSigCycleTime" SG_ 426 HeightControlMode 100;
BA_ "GenSigCycleTimeActive" SG_ 426 HeightControlMode 100;
BA_ "GenSigStartValue" SG_ 426 HeightControlMode 15;
BA_ "GenSigMaxLatency" SG_ 426 HeightControlMode 20;
BA_ "GenSigCycleTime" SG_ 426 LoadDistributionFuncSelected 100;
BA_ "GenSigCycleTimeActive" SG_ 426 LoadDistributionFuncSelected 100;
BA_ "GenSigStartValue" SG_ 426 LoadDistributionFuncSelected 15;
BA_ "GenSigMaxLatency" SG_ 426 LoadDistributionFuncSelected 20;
BA_ "GenSigCycleTime" SG_ 426 PitchAngle 100;
BA_ "GenSigCycleTimeActive" SG_ 426 PitchAngle 100;
BA_ "GenSigStartValue" SG_ 426 PitchAngle 65535;
BA_ "GenSigMaxLatency" SG_ 426 PitchAngle 20;
BA_ "GenSigCycleTime" SG_ 426 RollEndPositionStatus 100;
BA_ "GenSigCycleTimeActive" SG_ 426 RollEndPositionStatus 100;
BA_ "GenSigStartValue" SG_ 426 RollEndPositionStatus 7;
BA_ "GenSigMaxLatency" SG_ 426 RollEndPositionStatus 20;
BA_ "GenSigCycleTime" SG_ 426 SupplyPressure 100;
BA_ "GenSigCycleTimeActive" SG_ 426 SupplyPressure 100;
BA_ "GenSigStartValue" SG_ 426 SupplyPressure 255;
BA_ "GenSigMaxLatency" SG_ 426 SupplyPressure 20;
BA_ "GenSigCycleTime" SG_ 426 WheelBasedVehicleSpeed 100;
BA_ "GenSigCycleTimeActive" SG_ 426 WheelBasedVehicleSpeed 100;
BA_ "GenSigStartValue" SG_ 426 WheelBasedVehicleSpeed 65535;
BA_ "GenSigMaxLatency" SG_ 426 WheelBasedVehicleSpeed 20;
BA_ "GenSigCycleTime" SG_ 426 RearAxle2DiffLock_stat 100;
BA_ "GenSigCycleTimeActive" SG_ 426 RearAxle2DiffLock_stat 100;
BA_ "GenSigStartValue" SG_ 426 RearAxle2DiffLock_stat 3;
BA_ "GenSigMaxLatency" SG_ 426 RearAxle2DiffLock_stat 20;
BA_ "GenSigCycleTime" SG_ 426 KneelingStatusHMI 100;
BA_ "GenSigCycleTimeActive" SG_ 426 KneelingStatusHMI 100;
BA_ "GenSigStartValue" SG_ 426 KneelingStatusHMI 3;
BA_ "GenSigMaxLatency" SG_ 426 KneelingStatusHMI 20;
BA_ "GenSigCycleTime" SG_ 426 HeightAdjustmentAllowed 100;
BA_ "GenSigCycleTimeActive" SG_ 426 HeightAdjustmentAllowed 100;
BA_ "GenSigStartValue" SG_ 426 HeightAdjustmentAllowed 3;
BA_ "GenSigMaxLatency" SG_ 426 HeightAdjustmentAllowed 20;
BA_ "GenSigCycleTime" SG_ 426 RideHeightStatus 100;
BA_ "GenSigCycleTimeActive" SG_ 426 RideHeightStatus 100;
BA_ "GenSigStartValue" SG_ 426 RideHeightStatus 15;
BA_ "GenSigMaxLatency" SG_ 426 RideHeightStatus 20;
BA_ "GenSigCycleTime" SG_ 426 CentralRearDiffLock_stat 100;
BA_ "GenSigCycleTimeActive" SG_ 426 CentralRearDiffLock_stat 100;
BA_ "GenSigStartValue" SG_ 426 CentralRearDiffLock_stat 3;
BA_ "GenSigMaxLatency" SG_ 426 CentralRearDiffLock_stat 20;
BA_ "GenSigCycleTime" SG_ 426 ParkBrakeReleaseMode2 100;
BA_ "GenSigCycleTimeActive" SG_ 426 ParkBrakeReleaseMode2 100;
BA_ "GenSigStartValue" SG_ 426 ParkBrakeReleaseMode2 15;
BA_ "GenSigMaxLatency" SG_ 426 ParkBrakeReleaseMode2 30;
BA_ "GenSigCycleTime" SG_ 426 LiftAxle2PositionStatus 100;
BA_ "GenSigCycleTimeActive" SG_ 426 LiftAxle2PositionStatus 100;
BA_ "GenSigStartValue" SG_ 426 LiftAxle2PositionStatus 7;
BA_ "GenSigMaxLatency" SG_ 426 LiftAxle2PositionStatus 20;
BA_ "GenSigCycleTime" SG_ 426 RampHeightOutsideTargetRange 100;
BA_ "GenSigCycleTimeActive" SG_ 426 RampHeightOutsideTargetRange 100;
BA_ "GenSigStartValue" SG_ 426 RampHeightOutsideTargetRange 7;
BA_ "GenSigMaxLatency" SG_ 426 RampHeightOutsideTargetRange 20;
BA_ "GenSigCycleTime" SG_ 426 DirInd_Rear_Status 100;
BA_ "GenSigCycleTimeActive" SG_ 426 DirInd_Rear_Status 100;
BA_ "GenSigStartValue" SG_ 426 DirInd_Rear_Status 7;
BA_ "GenSigMaxLatency" SG_ 426 DirInd_Rear_Status 20;
BA_ "GenSigCycleTime" SG_ 426 ExternalRequestManualStiffness 100;
BA_ "GenSigCycleTimeActive" SG_ 426 ExternalRequestManualStiffness 100;
BA_ "GenSigStartValue" SG_ 426 ExternalRequestManualStiffness 15;
BA_ "GenSigMaxLatency" SG_ 426 ExternalRequestManualStiffness 20;
BA_ "GenSigCycleTime" SG_ 426 APM_ParkingBrake_stat 100;
BA_ "GenSigCycleTimeActive" SG_ 426 APM_ParkingBrake_stat 100;
BA_ "GenSigStartValue" SG_ 426 APM_ParkingBrake_stat 3;
BA_ "GenSigMaxLatency" SG_ 426 APM_ParkingBrake_stat 30;
BA_ "NeedsUpdateBit" SG_ 426 APM_ParkingBrake_stat 1;
BA_ "GenSigCycleTime" SG_ 426 VehicleDistanceRollingCounter 100;
BA_ "GenSigCycleTimeActive" SG_ 426 VehicleDistanceRollingCounter 100;
BA_ "GenSigStartValue" SG_ 426 VehicleDistanceRollingCounter 65535;
BA_ "GenSigMaxLatency" SG_ 426 VehicleDistanceRollingCounter 50;
BA_ "GenSigCycleTime" SG_ 426 BackToDriveReqACK 100;
BA_ "GenSigCycleTimeActive" SG_ 426 BackToDriveReqACK 100;
BA_ "GenSigStartValue" SG_ 426 BackToDriveReqACK 3;
BA_ "GenSigMaxLatency" SG_ 426 BackToDriveReqACK 20;
BA_ "GenSigCycleTime" SG_ 426 RearAxle1DiffLock_stat 100;
BA_ "GenSigCycleTimeActive" SG_ 426 RearAxle1DiffLock_stat 100;
BA_ "GenSigStartValue" SG_ 426 RearAxle1DiffLock_stat 3;
BA_ "GenSigMaxLatency" SG_ 426 RearAxle1DiffLock_stat 20;
BA_ "GenSigCycleTime" SG_ 426 LevelControlInformation 100;
BA_ "GenSigCycleTimeActive" SG_ 426 LevelControlInformation 100;
BA_ "GenSigStartValue" SG_ 426 LevelControlInformation 15;
BA_ "GenSigMaxLatency" SG_ 426 LevelControlInformation 20;
BA_ "GenSigCycleTime" SG_ 426 VehicleMode 100;
BA_ "GenSigCycleTimeActive" SG_ 426 VehicleMode 100;
BA_ "GenSigStartValue" SG_ 426 VehicleMode 15;
BA_ "GenSigCycleTime" SG_ 426 ACC_SGO_Status 100;
BA_ "GenSigCycleTimeActive" SG_ 426 ACC_SGO_Status 100;
BA_ "GenSigStartValue" SG_ 426 ACC_SGO_Status 15;
BA_ "GenSigMaxLatency" SG_ 426 ACC_SGO_Status 100;
BA_ "GenSigCycleTime" SG_ 426 RearEndPositionStatus 100;
BA_ "GenSigCycleTimeActive" SG_ 426 RearEndPositionStatus 100;
BA_ "GenSigStartValue" SG_ 426 RearEndPositionStatus 7;
BA_ "GenSigMaxLatency" SG_ 426 RearEndPositionStatus 20;
BA_ "GenSigCycleTime" SG_ 426 ECSShutdownCmd 100;
BA_ "GenSigCycleTimeActive" SG_ 426 ECSShutdownCmd 100;
BA_ "GenSigStartValue" SG_ 426 ECSShutdownCmd 3;
BA_ "GenSigMaxLatency" SG_ 426 ECSShutdownCmd 20;
BA_ "GenSigCycleTime" SG_ 426 APM_ParkBrakeApplicationMode2 100;
BA_ "GenSigCycleTimeActive" SG_ 426 APM_ParkBrakeApplicationMode2 100;
BA_ "GenSigStartValue" SG_ 426 APM_ParkBrakeApplicationMode2 15;
BA_ "GenSigMaxLatency" SG_ 426 APM_ParkBrakeApplicationMode2 30;
BA_ "GenSigCycleTime" SG_ 426 VehicleDynamicSuspProhibitStat 100;
BA_ "GenSigCycleTimeActive" SG_ 426 VehicleDynamicSuspProhibitStat 100;
BA_ "GenSigStartValue" SG_ 426 VehicleDynamicSuspProhibitStat 3;
BA_ "GenSigMaxLatency" SG_ 426 VehicleDynamicSuspProhibitStat 20;
BA_ "GenSigCycleTime" SG_ 426 ParkingBrake_stat 100;
BA_ "GenSigCycleTimeActive" SG_ 426 ParkingBrake_stat 100;
BA_ "GenSigStartValue" SG_ 426 ParkingBrake_stat 3;
BA_ "GenSigMaxLatency" SG_ 426 ParkingBrake_stat 20;
BA_ "GenSigCycleTime" SG_ 426 RideHeightFunctionStatus 100;
BA_ "GenSigCycleTimeActive" SG_ 426 RideHeightFunctionStatus 100;
BA_ "GenSigStartValue" SG_ 426 RideHeightFunctionStatus 15;
BA_ "GenSigMaxLatency" SG_ 426 RideHeightFunctionStatus 20;
BA_ "GenSigCycleTime" SG_ 426 APM_TrailerCircPressureStatus 100;
BA_ "GenSigCycleTimeActive" SG_ 426 APM_TrailerCircPressureStatus 100;
BA_ "GenSigStartValue" SG_ 426 APM_TrailerCircPressureStatus 3;
BA_ "GenSigMaxLatency" SG_ 426 APM_TrailerCircPressureStatus 30;
BA_REL_ "GenSigFirstTimeoutTime" BU_SG_REL_ EBS SG_ 266 ZxbrReqVeh_RetReq 3000;
BA_REL_ "GenSigTimeoutTime" BU_SG_REL_ EBS SG_ 266 ZxbrReqVeh_RetReq 100;
BA_REL_ "GenSigFirstTimeoutTime" BU_SG_REL_ EBS SG_ 266 ZxbrReqVeh_RetModReq 3000;
BA_REL_ "GenSigTimeoutTime" BU_SG_REL_ EBS SG_ 266 ZxbrReqVeh_RetModReq 100;
BA_REL_ "GenSigFirstTimeoutTime" BU_SG_REL_ EBS SG_ 266 ZxbrReqVeh_VmmModSts 3000;
BA_REL_ "GenSigTimeoutTime" BU_SG_REL_ EBS SG_ 266 ZxbrReqVeh_VmmModSts 100;
BA_REL_ "GenSigFirstTimeoutTime" BU_SG_REL_ EBS SG_ 266 ZxbrReqVeh_RetEbiModReq 3000;
BA_REL_ "GenSigTimeoutTime" BU_SG_REL_ EBS SG_ 266 ZxbrReqVeh_RetEbiModReq 100;
BA_REL_ "GenSigFirstTimeoutTime" BU_SG_REL_ EBS SG_ 266 ZxbrReqVeh_CRC 3000;
BA_REL_ "GenSigTimeoutTime" BU_SG_REL_ EBS SG_ 266 ZxbrReqVeh_CRC 100;
BA_REL_ "GenSigFirstTimeoutTime" BU_SG_REL_ EBS SG_ 266 ZxbrReqVeh_DrvrModReq 3000;
BA_REL_ "GenSigTimeoutTime" BU_SG_REL_ EBS SG_ 266 ZxbrReqVeh_DrvrModReq 100;
BA_REL_ "GenSigFirstTimeoutTime" BU_SG_REL_ EBS SG_ 266 ZxbrReqVeh_YawRateRefVds 3000;
BA_REL_ "GenSigTimeoutTime" BU_SG_REL_ EBS SG_ 266 ZxbrReqVeh_YawRateRefVds 100;
BA_REL_ "GenSigFirstTimeoutTime" BU_SG_REL_ EBS SG_ 266 ZxbrReqVeh_SqC 3000;
BA_REL_ "GenSigTimeoutTime" BU_SG_REL_ EBS SG_ 266 ZxbrReqVeh_SqC 100;
BA_REL_ "GenSigFirstTimeoutTime" BU_SG_REL_ EBS SG_ 262 IxbrReqAxle4_SlipCtrlEna 3000;
BA_REL_ "GenSigTimeoutTime" BU_SG_REL_ EBS SG_ 262 IxbrReqAxle4_SlipCtrlEna 100;
BA_REL_ "GenSigFirstTimeoutTime" BU_SG_REL_ EBS SG_ 262 IxbrReqAxle5_SqC 3000;
BA_REL_ "GenSigTimeoutTime" BU_SG_REL_ EBS SG_ 262 IxbrReqAxle5_SqC 100;
BA_REL_ "GenSigFirstTimeoutTime" BU_SG_REL_ EBS SG_ 262 IxbrReqAxle4_BrkTqReqLe 3000;
BA_REL_ "GenSigTimeoutTime" BU_SG_REL_ EBS SG_ 262 IxbrReqAxle4_BrkTqReqLe 100;
BA_REL_ "GenSigFirstTimeoutTime" BU_SG_REL_ EBS SG_ 262 IxbrReqAxle4_CRC 3000;
BA_REL_ "GenSigTimeoutTime" BU_SG_REL_ EBS SG_ 262 IxbrReqAxle4_CRC 100;
BA_REL_ "GenSigFirstTimeoutTime" BU_SG_REL_ EBS SG_ 262 IxbrReqAxle5_VehSpdLgtWhlRi 3000;
BA_REL_ "GenSigTimeoutTime" BU_SG_REL_ EBS SG_ 262 IxbrReqAxle5_VehSpdLgtWhlRi 100;
BA_REL_ "GenSigFirstTimeoutTime" BU_SG_REL_ EBS SG_ 262 IxbrReqAxle6_WhlSlipLimLoLe 3000;
BA_REL_ "GenSigTimeoutTime" BU_SG_REL_ EBS SG_ 262 IxbrReqAxle6_WhlSlipLimLoLe 100;
BA_REL_ "GenSigFirstTimeoutTime" BU_SG_REL_ EBS SG_ 262 IxbrReqAxle5_BrkTqReqRi 3000;
BA_REL_ "GenSigTimeoutTime" BU_SG_REL_ EBS SG_ 262 IxbrReqAxle5_BrkTqReqRi 100;
BA_REL_ "GenSigFirstTimeoutTime" BU_SG_REL_ EBS SG_ 262 IxbrReqAxle4_BrkTqReqRi 3000;
BA_REL_ "GenSigTimeoutTime" BU_SG_REL_ EBS SG_ 262 IxbrReqAxle4_BrkTqReqRi 100;
BA_REL_ "GenSigFirstTimeoutTime" BU_SG_REL_ EBS SG_ 262 IxbrReqAxle6_WhlSlipLimHiRi 3000;
BA_REL_ "GenSigTimeoutTime" BU_SG_REL_ EBS SG_ 262 IxbrReqAxle6_WhlSlipLimHiRi 100;
BA_REL_ "GenSigFirstTimeoutTime" BU_SG_REL_ EBS SG_ 262 IxbrReqAxle6_SqC 3000;
BA_REL_ "GenSigTimeoutTime" BU_SG_REL_ EBS SG_ 262 IxbrReqAxle6_SqC 100;
BA_REL_ "GenSigFirstTimeoutTime" BU_SG_REL_ EBS SG_ 262 IxbrReqAxle5_SlipCtrlEna 3000;
BA_REL_ "GenSigTimeoutTime" BU_SG_REL_ EBS SG_ 262 IxbrReqAxle5_SlipCtrlEna 100;
BA_REL_ "GenSigFirstTimeoutTime" BU_SG_REL_ EBS SG_ 262 IxbrReqAxle5_WhlSlipLimLoRi 3000;
BA_REL_ "GenSigTimeoutTime" BU_SG_REL_ EBS SG_ 262 IxbrReqAxle5_WhlSlipLimLoRi 100;
BA_REL_ "GenSigFirstTimeoutTime" BU_SG_REL_ EBS SG_ 262 IxbrReqAxle5_VehSpdLgtWhlLe 3000;
BA_REL_ "GenSigTimeoutTime" BU_SG_REL_ EBS SG_ 262 IxbrReqAxle5_VehSpdLgtWhlLe 100;
BA_REL_ "GenSigFirstTimeoutTime" BU_SG_REL_ EBS SG_ 262 IxbrReqAxle6_WhlSlipLimLoRi 3000;
BA_REL_ "GenSigTimeoutTime" BU_SG_REL_ EBS SG_ 262 IxbrReqAxle6_WhlSlipLimLoRi 100;
BA_REL_ "GenSigFirstTimeoutTime" BU_SG_REL_ EBS SG_ 262 IxbrReqAxle6_VehSpdLgtWhlRi 3000;
BA_REL_ "GenSigTimeoutTime" BU_SG_REL_ EBS SG_ 262 IxbrReqAxle6_VehSpdLgtWhlRi 100;
BA_REL_ "GenSigFirstTimeoutTime" BU_SG_REL_ EBS SG_ 262 IxbrReqAxle5_VehSpdLgtWhlQltyLe 3000;
BA_REL_ "GenSigTimeoutTime" BU_SG_REL_ EBS SG_ 262 IxbrReqAxle5_VehSpdLgtWhlQltyLe 100;
BA_REL_ "GenSigFirstTimeoutTime" BU_SG_REL_ EBS SG_ 262 IxbrReqAxle6_CRC 3000;
BA_REL_ "GenSigTimeoutTime" BU_SG_REL_ EBS SG_ 262 IxbrReqAxle6_CRC 100;
BA_REL_ "GenSigFirstTimeoutTime" BU_SG_REL_ EBS SG_ 262 IxbrReqAxle5_CRC 3000;
BA_REL_ "GenSigTimeoutTime" BU_SG_REL_ EBS SG_ 262 IxbrReqAxle5_CRC 100;
BA_REL_ "GenSigFirstTimeoutTime" BU_SG_REL_ EBS SG_ 262 IxbrReqAxle4_SqC 3000;
BA_REL_ "GenSigTimeoutTime" BU_SG_REL_ EBS SG_ 262 IxbrReqAxle4_SqC 100;
BA_REL_ "GenSigFirstTimeoutTime" BU_SG_REL_ EBS SG_ 262 IxbrReqAxle4_VehSpdLgtWhlRi 3000;
BA_REL_ "GenSigTimeoutTime" BU_SG_REL_ EBS SG_ 262 IxbrReqAxle4_VehSpdLgtWhlRi 100;
BA_REL_ "GenSigFirstTimeoutTime" BU_SG_REL_ EBS SG_ 262 IxbrReqAxle4_WhlSlipLimHiLe 3000;
BA_REL_ "GenSigTimeoutTime" BU_SG_REL_ EBS SG_ 262 IxbrReqAxle4_WhlSlipLimHiLe 100;
BA_REL_ "GenSigFirstTimeoutTime" BU_SG_REL_ EBS SG_ 262 IxbrReqAxle4_VehSpdLgtWhlLe 3000;
BA_REL_ "GenSigTimeoutTime" BU_SG_REL_ EBS SG_ 262 IxbrReqAxle4_VehSpdLgtWhlLe 100;
BA_REL_ "GenSigFirstTimeoutTime" BU_SG_REL_ EBS SG_ 262 IxbrReqAxle4_WhlSlipLimLoLe 3000;
BA_REL_ "GenSigTimeoutTime" BU_SG_REL_ EBS SG_ 262 IxbrReqAxle4_WhlSlipLimLoLe 100;
BA_REL_ "GenSigFirstTimeoutTime" BU_SG_REL_ EBS SG_ 262 IxbrReqAxle6_VehSpdLgtWhlQltyRi 3000;
BA_REL_ "GenSigTimeoutTime" BU_SG_REL_ EBS SG_ 262 IxbrReqAxle6_VehSpdLgtWhlQltyRi 100;
BA_REL_ "GenSigFirstTimeoutTime" BU_SG_REL_ EBS SG_ 262 IxbrReqAxle6_BrkTqReqLe 3000;
BA_REL_ "GenSigTimeoutTime" BU_SG_REL_ EBS SG_ 262 IxbrReqAxle6_BrkTqReqLe 100;
BA_REL_ "GenSigFirstTimeoutTime" BU_SG_REL_ EBS SG_ 262 IxbrReqAxle4_WhlSlipLimLoRi 3000;
BA_REL_ "GenSigTimeoutTime" BU_SG_REL_ EBS SG_ 262 IxbrReqAxle4_WhlSlipLimLoRi 100;
BA_REL_ "GenSigFirstTimeoutTime" BU_SG_REL_ EBS SG_ 262 IxbrReqAxle4_VehSpdLgtWhlQltyRi 3000;
BA_REL_ "GenSigTimeoutTime" BU_SG_REL_ EBS SG_ 262 IxbrReqAxle4_VehSpdLgtWhlQltyRi 100;
BA_REL_ "GenSigFirstTimeoutTime" BU_SG_REL_ EBS SG_ 262 IxbrReqAxle4_IxbrModReq 3000;
BA_REL_ "GenSigTimeoutTime" BU_SG_REL_ EBS SG_ 262 IxbrReqAxle4_IxbrModReq 100;
BA_REL_ "GenSigFirstTimeoutTime" BU_SG_REL_ EBS SG_ 262 IxbrReqAxle6_BrkTqReqRi 3000;
BA_REL_ "GenSigTimeoutTime" BU_SG_REL_ EBS SG_ 262 IxbrReqAxle6_BrkTqReqRi 100;
BA_REL_ "GenSigFirstTimeoutTime" BU_SG_REL_ EBS SG_ 262 IxbrReqAxle6_SlipCtrlEna 3000;
BA_REL_ "GenSigTimeoutTime" BU_SG_REL_ EBS SG_ 262 IxbrReqAxle6_SlipCtrlEna 100;
BA_REL_ "GenSigFirstTimeoutTime" BU_SG_REL_ EBS SG_ 262 IxbrReqAxle4_VehSpdLgtWhlQltyLe 3000;
BA_REL_ "GenSigTimeoutTime" BU_SG_REL_ EBS SG_ 262 IxbrReqAxle4_VehSpdLgtWhlQltyLe 100;
BA_REL_ "GenSigFirstTimeoutTime" BU_SG_REL_ EBS SG_ 262 IxbrReqAxle6_VehSpdLgtWhlQltyLe 3000;
BA_REL_ "GenSigTimeoutTime" BU_SG_REL_ EBS SG_ 262 IxbrReqAxle6_VehSpdLgtWhlQltyLe 100;
BA_REL_ "GenSigFirstTimeoutTime" BU_SG_REL_ EBS SG_ 262 IxbrReqAxle5_BrkTqReqLe 3000;
BA_REL_ "GenSigTimeoutTime" BU_SG_REL_ EBS SG_ 262 IxbrReqAxle5_BrkTqReqLe 100;
BA_REL_ "GenSigFirstTimeoutTime" BU_SG_REL_ EBS SG_ 262 IxbrReqAxle5_VehSpdLgtWhlQltyRi 3000;
BA_REL_ "GenSigTimeoutTime" BU_SG_REL_ EBS SG_ 262 IxbrReqAxle5_VehSpdLgtWhlQltyRi 100;
BA_REL_ "GenSigFirstTimeoutTime" BU_SG_REL_ EBS SG_ 262 IxbrReqAxle5_WhlSlipLimHiRi 3000;
BA_REL_ "GenSigTimeoutTime" BU_SG_REL_ EBS SG_ 262 IxbrReqAxle5_WhlSlipLimHiRi 100;
BA_REL_ "GenSigFirstTimeoutTime" BU_SG_REL_ EBS SG_ 262 IxbrReqAxle5_WhlSlipLimLoLe 3000;
BA_REL_ "GenSigTimeoutTime" BU_SG_REL_ EBS SG_ 262 IxbrReqAxle5_WhlSlipLimLoLe 100;
BA_REL_ "GenSigFirstTimeoutTime" BU_SG_REL_ EBS SG_ 262 IxbrReqAxle5_IxbrModReq 3000;
BA_REL_ "GenSigTimeoutTime" BU_SG_REL_ EBS SG_ 262 IxbrReqAxle5_IxbrModReq 100;
BA_REL_ "GenSigFirstTimeoutTime" BU_SG_REL_ EBS SG_ 262 IxbrReqAxle4_WhlSlipLimHiRi 3000;
BA_REL_ "GenSigTimeoutTime" BU_SG_REL_ EBS SG_ 262 IxbrReqAxle4_WhlSlipLimHiRi 100;
BA_REL_ "GenSigFirstTimeoutTime" BU_SG_REL_ EBS SG_ 262 IxbrReqAxle6_IxbrModReq 3000;
BA_REL_ "GenSigTimeoutTime" BU_SG_REL_ EBS SG_ 262 IxbrReqAxle6_IxbrModReq 100;
BA_REL_ "GenSigFirstTimeoutTime" BU_SG_REL_ EBS SG_ 262 IxbrReqAxle5_WhlSlipLimHiLe 3000;
BA_REL_ "GenSigTimeoutTime" BU_SG_REL_ EBS SG_ 262 IxbrReqAxle5_WhlSlipLimHiLe 100;
BA_REL_ "GenSigFirstTimeoutTime" BU_SG_REL_ EBS SG_ 262 IxbrReqAxle6_WhlSlipLimHiLe 3000;
BA_REL_ "GenSigTimeoutTime" BU_SG_REL_ EBS SG_ 262 IxbrReqAxle6_WhlSlipLimHiLe 100;
BA_REL_ "GenSigFirstTimeoutTime" BU_SG_REL_ EBS SG_ 262 IxbrReqAxle6_VehSpdLgtWhlLe 3000;
BA_REL_ "GenSigTimeoutTime" BU_SG_REL_ EBS SG_ 262 IxbrReqAxle6_VehSpdLgtWhlLe 100;
BA_REL_ "GenSigFirstTimeoutTime" BU_SG_REL_ EBS SG_ 261 IxbrReqAxle3_BrkTqReqLe 3000;
BA_REL_ "GenSigTimeoutTime" BU_SG_REL_ EBS SG_ 261 IxbrReqAxle3_BrkTqReqLe 100;
BA_REL_ "GenSigFirstTimeoutTime" BU_SG_REL_ EBS SG_ 261 IxbrReqAxle3_WhlSlipLimHiLe 3000;
BA_REL_ "GenSigTimeoutTime" BU_SG_REL_ EBS SG_ 261 IxbrReqAxle3_WhlSlipLimHiLe 100;
BA_REL_ "GenSigFirstTimeoutTime" BU_SG_REL_ EBS SG_ 261 IxbrReqAxle1_BrkTqReqLe 3000;
BA_REL_ "GenSigTimeoutTime" BU_SG_REL_ EBS SG_ 261 IxbrReqAxle1_BrkTqReqLe 100;
BA_REL_ "GenSigFirstTimeoutTime" BU_SG_REL_ EBS SG_ 261 IxbrReqAxle2_WhlSlipLimHiRi 3000;
BA_REL_ "GenSigTimeoutTime" BU_SG_REL_ EBS SG_ 261 IxbrReqAxle2_WhlSlipLimHiRi 100;
BA_REL_ "GenSigFirstTimeoutTime" BU_SG_REL_ EBS SG_ 261 IxbrReqAxle3_WhlSlipLimLoRi 3000;
BA_REL_ "GenSigTimeoutTime" BU_SG_REL_ EBS SG_ 261 IxbrReqAxle3_WhlSlipLimLoRi 100;
BA_REL_ "GenSigFirstTimeoutTime" BU_SG_REL_ EBS SG_ 261 IxbrReqAxle1_WhlSlipLimLoLe 3000;
BA_REL_ "GenSigTimeoutTime" BU_SG_REL_ EBS SG_ 261 IxbrReqAxle1_WhlSlipLimLoLe 100;
BA_REL_ "GenSigFirstTimeoutTime" BU_SG_REL_ EBS SG_ 261 IxbrReqAxle3_BrkTqReqRi 3000;
BA_REL_ "GenSigTimeoutTime" BU_SG_REL_ EBS SG_ 261 IxbrReqAxle3_BrkTqReqRi 100;
BA_REL_ "GenSigFirstTimeoutTime" BU_SG_REL_ EBS SG_ 261 IxbrReqAxle2_BrkTqReqLe 3000;
BA_REL_ "GenSigTimeoutTime" BU_SG_REL_ EBS SG_ 261 IxbrReqAxle2_BrkTqReqLe 100;
BA_REL_ "GenSigFirstTimeoutTime" BU_SG_REL_ EBS SG_ 261 IxbrReqAxle1_VehSpdLgtWhlQltyRi 3000;
BA_REL_ "GenSigTimeoutTime" BU_SG_REL_ EBS SG_ 261 IxbrReqAxle1_VehSpdLgtWhlQltyRi 100;
BA_REL_ "GenSigFirstTimeoutTime" BU_SG_REL_ EBS SG_ 261 IxbrReqAxle2_BrkTqReqRi 3000;
BA_REL_ "GenSigTimeoutTime" BU_SG_REL_ EBS SG_ 261 IxbrReqAxle2_BrkTqReqRi 100;
BA_REL_ "GenSigFirstTimeoutTime" BU_SG_REL_ EBS SG_ 261 IxbrReqAxle1_WhlSlipLimHiLe 3000;
BA_REL_ "GenSigTimeoutTime" BU_SG_REL_ EBS SG_ 261 IxbrReqAxle1_WhlSlipLimHiLe 100;
BA_REL_ "GenSigFirstTimeoutTime" BU_SG_REL_ EBS SG_ 261 IxbrReqAxle1_SlipCtrlEna 3000;
BA_REL_ "GenSigTimeoutTime" BU_SG_REL_ EBS SG_ 261 IxbrReqAxle1_SlipCtrlEna 100;
BA_REL_ "GenSigFirstTimeoutTime" BU_SG_REL_ EBS SG_ 261 IxbrReqAxle1_WhlSlipLimLoRi 3000;
BA_REL_ "GenSigTimeoutTime" BU_SG_REL_ EBS SG_ 261 IxbrReqAxle1_WhlSlipLimLoRi 100;
BA_REL_ "GenSigFirstTimeoutTime" BU_SG_REL_ EBS SG_ 261 IxbrReqAxle2_SlipCtrlEna 3000;
BA_REL_ "GenSigTimeoutTime" BU_SG_REL_ EBS SG_ 261 IxbrReqAxle2_SlipCtrlEna 100;
BA_REL_ "GenSigFirstTimeoutTime" BU_SG_REL_ EBS SG_ 261 IxbrReqAxle1_IxbrModReq 3000;
BA_REL_ "GenSigTimeoutTime" BU_SG_REL_ EBS SG_ 261 IxbrReqAxle1_IxbrModReq 100;
BA_REL_ "GenSigFirstTimeoutTime" BU_SG_REL_ EBS SG_ 261 IxbrReqAxle1_SqC 3000;
BA_REL_ "GenSigTimeoutTime" BU_SG_REL_ EBS SG_ 261 IxbrReqAxle1_SqC 100;
BA_REL_ "GenSigFirstTimeoutTime" BU_SG_REL_ EBS SG_ 261 IxbrReqAxle3_VehSpdLgtWhlQltyLe 3000;
BA_REL_ "GenSigTimeoutTime" BU_SG_REL_ EBS SG_ 261 IxbrReqAxle3_VehSpdLgtWhlQltyLe 100;
BA_REL_ "GenSigFirstTimeoutTime" BU_SG_REL_ EBS SG_ 261 IxbrReqAxle3_SqC 3000;
BA_REL_ "GenSigTimeoutTime" BU_SG_REL_ EBS SG_ 261 IxbrReqAxle3_SqC 100;
BA_REL_ "GenSigFirstTimeoutTime" BU_SG_REL_ EBS SG_ 261 IxbrReqAxle2_WhlSlipLimLoRi 3000;
BA_REL_ "GenSigTimeoutTime" BU_SG_REL_ EBS SG_ 261 IxbrReqAxle2_WhlSlipLimLoRi 100;
BA_REL_ "GenSigFirstTimeoutTime" BU_SG_REL_ EBS SG_ 261 IxbrReqAxle1_WhlSlipLimHiRi 3000;
BA_REL_ "GenSigTimeoutTime" BU_SG_REL_ EBS SG_ 261 IxbrReqAxle1_WhlSlipLimHiRi 100;
BA_REL_ "GenSigFirstTimeoutTime" BU_SG_REL_ EBS SG_ 261 IxbrReqAxle2_IxbrModReq 3000;
BA_REL_ "GenSigTimeoutTime" BU_SG_REL_ EBS SG_ 261 IxbrReqAxle2_IxbrModReq 100;
BA_REL_ "GenSigFirstTimeoutTime" BU_SG_REL_ EBS SG_ 261 IxbrReqAxle3_WhlSlipLimLoLe 3000;
BA_REL_ "GenSigTimeoutTime" BU_SG_REL_ EBS SG_ 261 IxbrReqAxle3_WhlSlipLimLoLe 100;
BA_REL_ "GenSigFirstTimeoutTime" BU_SG_REL_ EBS SG_ 261 IxbrReqAxle2_SqC 3000;
BA_REL_ "GenSigTimeoutTime" BU_SG_REL_ EBS SG_ 261 IxbrReqAxle2_SqC 100;
BA_REL_ "GenSigFirstTimeoutTime" BU_SG_REL_ EBS SG_ 261 IxbrReqAxle1_VehSpdLgtWhlLe 3000;
BA_REL_ "GenSigTimeoutTime" BU_SG_REL_ EBS SG_ 261 IxbrReqAxle1_VehSpdLgtWhlLe 100;
BA_REL_ "GenSigFirstTimeoutTime" BU_SG_REL_ EBS SG_ 261 IxbrReqAxle3_VehSpdLgtWhlRi 3000;
BA_REL_ "GenSigTimeoutTime" BU_SG_REL_ EBS SG_ 261 IxbrReqAxle3_VehSpdLgtWhlRi 100;
BA_REL_ "GenSigFirstTimeoutTime" BU_SG_REL_ EBS SG_ 261 IxbrReqAxle3_WhlSlipLimHiRi 3000;
BA_REL_ "GenSigTimeoutTime" BU_SG_REL_ EBS SG_ 261 IxbrReqAxle3_WhlSlipLimHiRi 100;
BA_REL_ "GenSigFirstTimeoutTime" BU_SG_REL_ EBS SG_ 261 IxbrReqAxle2_WhlSlipLimLoLe 3000;
BA_REL_ "GenSigTimeoutTime" BU_SG_REL_ EBS SG_ 261 IxbrReqAxle2_WhlSlipLimLoLe 100;
BA_REL_ "GenSigFirstTimeoutTime" BU_SG_REL_ EBS SG_ 261 IxbrReqAxle2_VehSpdLgtWhlLe 3000;
BA_REL_ "GenSigTimeoutTime" BU_SG_REL_ EBS SG_ 261 IxbrReqAxle2_VehSpdLgtWhlLe 100;
BA_REL_ "GenSigFirstTimeoutTime" BU_SG_REL_ EBS SG_ 261 IxbrReqAxle2_WhlSlipLimHiLe 3000;
BA_REL_ "GenSigTimeoutTime" BU_SG_REL_ EBS SG_ 261 IxbrReqAxle2_WhlSlipLimHiLe 100;
BA_REL_ "GenSigFirstTimeoutTime" BU_SG_REL_ EBS SG_ 261 IxbrReqAxle3_VehSpdLgtWhlQltyRi 3000;
BA_REL_ "GenSigTimeoutTime" BU_SG_REL_ EBS SG_ 261 IxbrReqAxle3_VehSpdLgtWhlQltyRi 100;
BA_REL_ "GenSigFirstTimeoutTime" BU_SG_REL_ EBS SG_ 261 IxbrReqAxle1_VehSpdLgtWhlQltyLe 3000;
BA_REL_ "GenSigTimeoutTime" BU_SG_REL_ EBS SG_ 261 IxbrReqAxle1_VehSpdLgtWhlQltyLe 100;
BA_REL_ "GenSigFirstTimeoutTime" BU_SG_REL_ EBS SG_ 261 IxbrReqAxle1_BrkTqReqRi 3000;
BA_REL_ "GenSigTimeoutTime" BU_SG_REL_ EBS SG_ 261 IxbrReqAxle1_BrkTqReqRi 100;
BA_REL_ "GenSigFirstTimeoutTime" BU_SG_REL_ EBS SG_ 261 IxbrReqAxle1_VehSpdLgtWhlRi 3000;
BA_REL_ "GenSigTimeoutTime" BU_SG_REL_ EBS SG_ 261 IxbrReqAxle1_VehSpdLgtWhlRi 100;
BA_REL_ "GenSigFirstTimeoutTime" BU_SG_REL_ EBS SG_ 261 IxbrReqAxle3_IxbrModReq 3000;
BA_REL_ "GenSigTimeoutTime" BU_SG_REL_ EBS SG_ 261 IxbrReqAxle3_IxbrModReq 100;
BA_REL_ "GenSigFirstTimeoutTime" BU_SG_REL_ EBS SG_ 261 IxbrReqAxle2_CRC 3000;
BA_REL_ "GenSigTimeoutTime" BU_SG_REL_ EBS SG_ 261 IxbrReqAxle2_CRC 100;
BA_REL_ "GenSigFirstTimeoutTime" BU_SG_REL_ EBS SG_ 261 IxbrReqAxle2_VehSpdLgtWhlQltyLe 3000;
BA_REL_ "GenSigTimeoutTime" BU_SG_REL_ EBS SG_ 261 IxbrReqAxle2_VehSpdLgtWhlQltyLe 100;
BA_REL_ "GenSigFirstTimeoutTime" BU_SG_REL_ EBS SG_ 261 IxbrReqAxle3_VehSpdLgtWhlLe 3000;
BA_REL_ "GenSigTimeoutTime" BU_SG_REL_ EBS SG_ 261 IxbrReqAxle3_VehSpdLgtWhlLe 100;
BA_REL_ "GenSigFirstTimeoutTime" BU_SG_REL_ EBS SG_ 261 IxbrReqAxle3_SlipCtrlEna 3000;
BA_REL_ "GenSigTimeoutTime" BU_SG_REL_ EBS SG_ 261 IxbrReqAxle3_SlipCtrlEna 100;
BA_REL_ "GenSigFirstTimeoutTime" BU_SG_REL_ EBS SG_ 261 IxbrReqAxle3_CRC 3000;
BA_REL_ "GenSigTimeoutTime" BU_SG_REL_ EBS SG_ 261 IxbrReqAxle3_CRC 100;
BA_REL_ "GenSigFirstTimeoutTime" BU_SG_REL_ EBS SG_ 261 IxbrReqAxle2_VehSpdLgtWhlRi 3000;
BA_REL_ "GenSigTimeoutTime" BU_SG_REL_ EBS SG_ 261 IxbrReqAxle2_VehSpdLgtWhlRi 100;
BA_REL_ "GenSigFirstTimeoutTime" BU_SG_REL_ EBS SG_ 261 IxbrReqAxle2_VehSpdLgtWhlQltyRi 3000;
BA_REL_ "GenSigTimeoutTime" BU_SG_REL_ EBS SG_ 261 IxbrReqAxle2_VehSpdLgtWhlQltyRi 100;
BA_REL_ "GenSigFirstTimeoutTime" BU_SG_REL_ EBS SG_ 261 IxbrReqAxle1_CRC 3000;
BA_REL_ "GenSigTimeoutTime" BU_SG_REL_ EBS SG_ 261 IxbrReqAxle1_CRC 100;
BA_REL_ "GenSigFirstTimeoutTime" BU_SG_REL_ EBS SG_ 554 EstAxle3_LoadNormLe 3000;
BA_REL_ "GenSigTimeoutTime" BU_SG_REL_ EBS SG_ 554 EstAxle3_LoadNormLe 300;
BA_REL_ "GenSigFirstTimeoutTime" BU_SG_REL_ EBS SG_ 554 EstAxle6_WhlRdEstQltyRi 3000;
BA_REL_ "GenSigTimeoutTime" BU_SG_REL_ EBS SG_ 554 EstAxle6_WhlRdEstQltyRi 300;
BA_REL_ "GenSigFirstTimeoutTime" BU_SG_REL_ EBS SG_ 554 EstAxle5_WhlRdEstQltyRi 3000;
BA_REL_ "GenSigTimeoutTime" BU_SG_REL_ EBS SG_ 554 EstAxle5_WhlRdEstQltyRi 300;
BA_REL_ "GenSigFirstTimeoutTime" BU_SG_REL_ EBS SG_ 554 EstAxle2_LoadNormQltyLe 3000;
BA_REL_ "GenSigTimeoutTime" BU_SG_REL_ EBS SG_ 554 EstAxle2_LoadNormQltyLe 300;
BA_REL_ "GenSigFirstTimeoutTime" BU_SG_REL_ EBS SG_ 554 EstAxle3_LoadNormQltyRi 3000;
BA_REL_ "GenSigTimeoutTime" BU_SG_REL_ EBS SG_ 554 EstAxle3_LoadNormQltyRi 300;
BA_REL_ "GenSigFirstTimeoutTime" BU_SG_REL_ EBS SG_ 554 EstAxle6_SqC 3000;
BA_REL_ "GenSigTimeoutTime" BU_SG_REL_ EBS SG_ 554 EstAxle6_SqC 300;
BA_REL_ "GenSigFirstTimeoutTime" BU_SG_REL_ EBS SG_ 554 EstAxle4_LoadNormQltyRi 3000;
BA_REL_ "GenSigTimeoutTime" BU_SG_REL_ EBS SG_ 554 EstAxle4_LoadNormQltyRi 300;
BA_REL_ "GenSigFirstTimeoutTime" BU_SG_REL_ EBS SG_ 554 EstAxle6_LoadNormRi 3000;
BA_REL_ "GenSigTimeoutTime" BU_SG_REL_ EBS SG_ 554 EstAxle6_LoadNormRi 300;
BA_REL_ "GenSigFirstTimeoutTime" BU_SG_REL_ EBS SG_ 554 EstAxle5_SqC 3000;
BA_REL_ "GenSigTimeoutTime" BU_SG_REL_ EBS SG_ 554 EstAxle5_SqC 300;
BA_REL_ "GenSigFirstTimeoutTime" BU_SG_REL_ EBS SG_ 554 EstAxle6_CRC 3000;
BA_REL_ "GenSigTimeoutTime" BU_SG_REL_ EBS SG_ 554 EstAxle6_CRC 300;
BA_REL_ "GenSigFirstTimeoutTime" BU_SG_REL_ EBS SG_ 554 EstAxle2_WhlRdEstLe 3000;
BA_REL_ "GenSigTimeoutTime" BU_SG_REL_ EBS SG_ 554 EstAxle2_WhlRdEstLe 300;
BA_REL_ "GenSigFirstTimeoutTime" BU_SG_REL_ EBS SG_ 554 EstAxle3_WhlRdEstRi 3000;
BA_REL_ "GenSigTimeoutTime" BU_SG_REL_ EBS SG_ 554 EstAxle3_WhlRdEstRi 300;
BA_REL_ "GenSigFirstTimeoutTime" BU_SG_REL_ EBS SG_ 554 EstAxle5_LoadNormQltyRi 3000;
BA_REL_ "GenSigTimeoutTime" BU_SG_REL_ EBS SG_ 554 EstAxle5_LoadNormQltyRi 300;
BA_REL_ "GenSigFirstTimeoutTime" BU_SG_REL_ EBS SG_ 554 EstAxle6_WhlRdEstLe 3000;
BA_REL_ "GenSigTimeoutTime" BU_SG_REL_ EBS SG_ 554 EstAxle6_WhlRdEstLe 300;
BA_REL_ "GenSigFirstTimeoutTime" BU_SG_REL_ EBS SG_ 554 EstAxle6_WhlRdEstQltyLe 3000;
BA_REL_ "GenSigTimeoutTime" BU_SG_REL_ EBS SG_ 554 EstAxle6_WhlRdEstQltyLe 300;
BA_REL_ "GenSigFirstTimeoutTime" BU_SG_REL_ EBS SG_ 554 EstAxle6_LoadNormLe 3000;
BA_REL_ "GenSigTimeoutTime" BU_SG_REL_ EBS SG_ 554 EstAxle6_LoadNormLe 300;
BA_REL_ "GenSigFirstTimeoutTime" BU_SG_REL_ EBS SG_ 554 EstAxle5_LoadNormRi 3000;
BA_REL_ "GenSigTimeoutTime" BU_SG_REL_ EBS SG_ 554 EstAxle5_LoadNormRi 300;
BA_REL_ "GenSigFirstTimeoutTime" BU_SG_REL_ EBS SG_ 554 EstAxle5_LoadNormQltyLe 3000;
BA_REL_ "GenSigTimeoutTime" BU_SG_REL_ EBS SG_ 554 EstAxle5_LoadNormQltyLe 300;
BA_REL_ "GenSigFirstTimeoutTime" BU_SG_REL_ EBS SG_ 554 EstAxle5_CRC 3000;
BA_REL_ "GenSigTimeoutTime" BU_SG_REL_ EBS SG_ 554 EstAxle5_CRC 300;
BA_REL_ "GenSigFirstTimeoutTime" BU_SG_REL_ EBS SG_ 554 EstAxle1_WhlRdEstRi 3000;
BA_REL_ "GenSigTimeoutTime" BU_SG_REL_ EBS SG_ 554 EstAxle1_WhlRdEstRi 300;
BA_REL_ "GenSigFirstTimeoutTime" BU_SG_REL_ EBS SG_ 554 EstAxle4_LoadNormRi 3000;
BA_REL_ "GenSigTimeoutTime" BU_SG_REL_ EBS SG_ 554 EstAxle4_LoadNormRi 300;
BA_REL_ "GenSigFirstTimeoutTime" BU_SG_REL_ EBS SG_ 554 EstAxle3_WhlRdEstQltyLe 3000;
BA_REL_ "GenSigTimeoutTime" BU_SG_REL_ EBS SG_ 554 EstAxle3_WhlRdEstQltyLe 300;
BA_REL_ "GenSigFirstTimeoutTime" BU_SG_REL_ EBS SG_ 554 EstAxle4_WhlRdEstRi 3000;
BA_REL_ "GenSigTimeoutTime" BU_SG_REL_ EBS SG_ 554 EstAxle4_WhlRdEstRi 300;
BA_REL_ "GenSigFirstTimeoutTime" BU_SG_REL_ EBS SG_ 554 EstAxle6_WhlRdEstRi 3000;
BA_REL_ "GenSigTimeoutTime" BU_SG_REL_ EBS SG_ 554 EstAxle6_WhlRdEstRi 300;
BA_REL_ "GenSigFirstTimeoutTime" BU_SG_REL_ EBS SG_ 554 EstAxle5_LoadNormLe 3000;
BA_REL_ "GenSigTimeoutTime" BU_SG_REL_ EBS SG_ 554 EstAxle5_LoadNormLe 300;
BA_REL_ "GenSigFirstTimeoutTime" BU_SG_REL_ EBS SG_ 554 EstAxle5_WhlRdEstLe 3000;
BA_REL_ "GenSigTimeoutTime" BU_SG_REL_ EBS SG_ 554 EstAxle5_WhlRdEstLe 300;
BA_REL_ "GenSigFirstTimeoutTime" BU_SG_REL_ EBS SG_ 554 EstAxle3_CRC 3000;
BA_REL_ "GenSigTimeoutTime" BU_SG_REL_ EBS SG_ 554 EstAxle3_CRC 300;
BA_REL_ "GenSigFirstTimeoutTime" BU_SG_REL_ EBS SG_ 554 EstAxle2_LoadNormRi 3000;
BA_REL_ "GenSigTimeoutTime" BU_SG_REL_ EBS SG_ 554 EstAxle2_LoadNormRi 300;
BA_REL_ "GenSigFirstTimeoutTime" BU_SG_REL_ EBS SG_ 554 EstAxle4_SqC 3000;
BA_REL_ "GenSigTimeoutTime" BU_SG_REL_ EBS SG_ 554 EstAxle4_SqC 300;
BA_REL_ "GenSigFirstTimeoutTime" BU_SG_REL_ EBS SG_ 554 EstAxle4_WhlRdEstQltyRi 3000;
BA_REL_ "GenSigTimeoutTime" BU_SG_REL_ EBS SG_ 554 EstAxle4_WhlRdEstQltyRi 300;
BA_REL_ "GenSigFirstTimeoutTime" BU_SG_REL_ EBS SG_ 554 EstAxle6_LoadNormQltyRi 3000;
BA_REL_ "GenSigTimeoutTime" BU_SG_REL_ EBS SG_ 554 EstAxle6_LoadNormQltyRi 300;
BA_REL_ "GenSigFirstTimeoutTime" BU_SG_REL_ EBS SG_ 554 EstAxle1_LoadNormQltyRi 3000;
BA_REL_ "GenSigTimeoutTime" BU_SG_REL_ EBS SG_ 554 EstAxle1_LoadNormQltyRi 300;
BA_REL_ "GenSigFirstTimeoutTime" BU_SG_REL_ EBS SG_ 554 EstAxle1_LoadNormQltyLe 3000;
BA_REL_ "GenSigTimeoutTime" BU_SG_REL_ EBS SG_ 554 EstAxle1_LoadNormQltyLe 300;
BA_REL_ "GenSigFirstTimeoutTime" BU_SG_REL_ EBS SG_ 554 EstAxle2_LoadNormLe 3000;
BA_REL_ "GenSigTimeoutTime" BU_SG_REL_ EBS SG_ 554 EstAxle2_LoadNormLe 300;
BA_REL_ "GenSigFirstTimeoutTime" BU_SG_REL_ EBS SG_ 554 EstAxle4_WhlRdEstQltyLe 3000;
BA_REL_ "GenSigTimeoutTime" BU_SG_REL_ EBS SG_ 554 EstAxle4_WhlRdEstQltyLe 300;
BA_REL_ "GenSigFirstTimeoutTime" BU_SG_REL_ EBS SG_ 554 EstAxle4_WhlRdEstLe 3000;
BA_REL_ "GenSigTimeoutTime" BU_SG_REL_ EBS SG_ 554 EstAxle4_WhlRdEstLe 300;
BA_REL_ "GenSigFirstTimeoutTime" BU_SG_REL_ EBS SG_ 554 EstAxle1_WhlRdEstQltyLe 3000;
BA_REL_ "GenSigTimeoutTime" BU_SG_REL_ EBS SG_ 554 EstAxle1_WhlRdEstQltyLe 300;
BA_REL_ "GenSigFirstTimeoutTime" BU_SG_REL_ EBS SG_ 554 EstAxle2_LoadNormQltyRi 3000;
BA_REL_ "GenSigTimeoutTime" BU_SG_REL_ EBS SG_ 554 EstAxle2_LoadNormQltyRi 300;
BA_REL_ "GenSigFirstTimeoutTime" BU_SG_REL_ EBS SG_ 554 EstAxle3_LoadNormQltyLe 3000;
BA_REL_ "GenSigTimeoutTime" BU_SG_REL_ EBS SG_ 554 EstAxle3_LoadNormQltyLe 300;
BA_REL_ "GenSigFirstTimeoutTime" BU_SG_REL_ EBS SG_ 554 EstAxle4_LoadNormQltyLe 3000;
BA_REL_ "GenSigTimeoutTime" BU_SG_REL_ EBS SG_ 554 EstAxle4_LoadNormQltyLe 300;
BA_REL_ "GenSigFirstTimeoutTime" BU_SG_REL_ EBS SG_ 554 EstAxle2_WhlRdEstQltyRi 3000;
BA_REL_ "GenSigTimeoutTime" BU_SG_REL_ EBS SG_ 554 EstAxle2_WhlRdEstQltyRi 300;
BA_REL_ "GenSigFirstTimeoutTime" BU_SG_REL_ EBS SG_ 554 EstAxle6_LoadNormQltyLe 3000;
BA_REL_ "GenSigTimeoutTime" BU_SG_REL_ EBS SG_ 554 EstAxle6_LoadNormQltyLe 300;
BA_REL_ "GenSigFirstTimeoutTime" BU_SG_REL_ EBS SG_ 554 EstAxle2_WhlRdEstRi 3000;
BA_REL_ "GenSigTimeoutTime" BU_SG_REL_ EBS SG_ 554 EstAxle2_WhlRdEstRi 300;
BA_REL_ "GenSigFirstTimeoutTime" BU_SG_REL_ EBS SG_ 554 EstAxle3_WhlRdEstQltyRi 3000;
BA_REL_ "GenSigTimeoutTime" BU_SG_REL_ EBS SG_ 554 EstAxle3_WhlRdEstQltyRi 300;
BA_REL_ "GenSigFirstTimeoutTime" BU_SG_REL_ EBS SG_ 554 EstAxle1_LoadNormLe 3000;
BA_REL_ "GenSigTimeoutTime" BU_SG_REL_ EBS SG_ 554 EstAxle1_LoadNormLe 300;
BA_REL_ "GenSigFirstTimeoutTime" BU_SG_REL_ EBS SG_ 554 EstAxle1_CRC 3000;
BA_REL_ "GenSigTimeoutTime" BU_SG_REL_ EBS SG_ 554 EstAxle1_CRC 300;
BA_REL_ "GenSigFirstTimeoutTime" BU_SG_REL_ EBS SG_ 554 EstAxle5_WhlRdEstRi 3000;
BA_REL_ "GenSigTimeoutTime" BU_SG_REL_ EBS SG_ 554 EstAxle5_WhlRdEstRi 300;
BA_REL_ "GenSigFirstTimeoutTime" BU_SG_REL_ EBS SG_ 554 EstAxle2_CRC 3000;
BA_REL_ "GenSigTimeoutTime" BU_SG_REL_ EBS SG_ 554 EstAxle2_CRC 300;
BA_REL_ "GenSigFirstTimeoutTime" BU_SG_REL_ EBS SG_ 554 EstAxle1_LoadNormRi 3000;
BA_REL_ "GenSigTimeoutTime" BU_SG_REL_ EBS SG_ 554 EstAxle1_LoadNormRi 300;
BA_REL_ "GenSigFirstTimeoutTime" BU_SG_REL_ EBS SG_ 554 EstAxle2_WhlRdEstQltyLe 3000;
BA_REL_ "GenSigTimeoutTime" BU_SG_REL_ EBS SG_ 554 EstAxle2_WhlRdEstQltyLe 300;
BA_REL_ "GenSigFirstTimeoutTime" BU_SG_REL_ EBS SG_ 554 EstAxle4_CRC 3000;
BA_REL_ "GenSigTimeoutTime" BU_SG_REL_ EBS SG_ 554 EstAxle4_CRC 300;
BA_REL_ "GenSigFirstTimeoutTime" BU_SG_REL_ EBS SG_ 554 EstAxle3_LoadNormRi 3000;
BA_REL_ "GenSigTimeoutTime" BU_SG_REL_ EBS SG_ 554 EstAxle3_LoadNormRi 300;
BA_REL_ "GenSigFirstTimeoutTime" BU_SG_REL_ EBS SG_ 554 EstAxle5_WhlRdEstQltyLe 3000;
BA_REL_ "GenSigTimeoutTime" BU_SG_REL_ EBS SG_ 554 EstAxle5_WhlRdEstQltyLe 300;
BA_REL_ "GenSigFirstTimeoutTime" BU_SG_REL_ EBS SG_ 554 EstAxle3_SqC 3000;
BA_REL_ "GenSigTimeoutTime" BU_SG_REL_ EBS SG_ 554 EstAxle3_SqC 300;
BA_REL_ "GenSigFirstTimeoutTime" BU_SG_REL_ EBS SG_ 554 EstAxle1_WhlRdEstLe 3000;
BA_REL_ "GenSigTimeoutTime" BU_SG_REL_ EBS SG_ 554 EstAxle1_WhlRdEstLe 300;
BA_REL_ "GenSigFirstTimeoutTime" BU_SG_REL_ EBS SG_ 554 EstAxle4_LoadNormLe 3000;
BA_REL_ "GenSigTimeoutTime" BU_SG_REL_ EBS SG_ 554 EstAxle4_LoadNormLe 300;
BA_REL_ "GenSigFirstTimeoutTime" BU_SG_REL_ EBS SG_ 554 EstAxle1_SqC 3000;
BA_REL_ "GenSigTimeoutTime" BU_SG_REL_ EBS SG_ 554 EstAxle1_SqC 300;
BA_REL_ "GenSigFirstTimeoutTime" BU_SG_REL_ EBS SG_ 554 EstAxle1_WhlRdEstQltyRi 3000;
BA_REL_ "GenSigTimeoutTime" BU_SG_REL_ EBS SG_ 554 EstAxle1_WhlRdEstQltyRi 300;
BA_REL_ "GenSigFirstTimeoutTime" BU_SG_REL_ EBS SG_ 554 EstAxle2_SqC 3000;
BA_REL_ "GenSigTimeoutTime" BU_SG_REL_ EBS SG_ 554 EstAxle2_SqC 300;
BA_REL_ "GenSigFirstTimeoutTime" BU_SG_REL_ EBS SG_ 554 EstAxle3_WhlRdEstLe 3000;
BA_REL_ "GenSigTimeoutTime" BU_SG_REL_ EBS SG_ 554 EstAxle3_WhlRdEstLe 300;
BA_REL_ "GenSigFirstTimeoutTime" BU_SG_REL_ EBS SG_ 631 APM_LowAirPressureAlert 3000;
BA_REL_ "GenSigTimeoutTime" BU_SG_REL_ EBS SG_ 631 APM_LowAirPressureAlert 300;
BA_REL_ "GenSigFirstTimeoutTime" BU_SG_REL_ EBS SG_ 631 APM_PBChamberAirPressure 3000;
BA_REL_ "GenSigTimeoutTime" BU_SG_REL_ EBS SG_ 631 APM_PBChamberAirPressure 300;
BA_REL_ "GenSigFirstTimeoutTime" BU_SG_REL_ EBS SG_ 631 EPBHSARequest 3000;
BA_REL_ "GenSigTimeoutTime" BU_SG_REL_ EBS SG_ 631 EPBHSARequest 300;
BA_REL_ "GenSigFirstTimeoutTime" BU_SG_REL_ EBS SG_ 631 APM_ParkBrakeActuationStatus 3000;
BA_REL_ "GenSigTimeoutTime" BU_SG_REL_ EBS SG_ 631 APM_ParkBrakeActuationStatus 300;
BA_REL_ "GenSigFirstTimeoutTime" BU_SG_REL_ FAS SG_ 1448 TotalVehicleDistanceHighRes 24000;
BA_REL_ "GenSigTimeoutTime" BU_SG_REL_ FAS SG_ 1448 TotalVehicleDistanceHighRes 6000;
BA_REL_ "GenSigFirstTimeoutTime" BU_SG_REL_ FAS SG_ 1448 AmbientAirTemperature 24000;
BA_REL_ "GenSigTimeoutTime" BU_SG_REL_ FAS SG_ 1448 AmbientAirTemperature 6000;
BA_REL_ "GenSigFirstTimeoutTime" BU_SG_REL_ FAS SG_ 1319 YearUTC 6000;
BA_REL_ "GenSigTimeoutTime" BU_SG_REL_ FAS SG_ 1319 YearUTC 1500;
BA_REL_ "GenSigFirstTimeoutTime" BU_SG_REL_ FAS SG_ 1319 SecondsUTC 6000;
BA_REL_ "GenSigTimeoutTime" BU_SG_REL_ FAS SG_ 1319 SecondsUTC 1500;
BA_REL_ "GenSigFirstTimeoutTime" BU_SG_REL_ FAS SG_ 1319 DayUTC 6000;
BA_REL_ "GenSigTimeoutTime" BU_SG_REL_ FAS SG_ 1319 DayUTC 1500;
BA_REL_ "GenSigFirstTimeoutTime" BU_SG_REL_ FAS SG_ 1319 MonthUTC 6000;
BA_REL_ "GenSigTimeoutTime" BU_SG_REL_ FAS SG_ 1319 MonthUTC 1500;
BA_REL_ "GenSigFirstTimeoutTime" BU_SG_REL_ FAS SG_ 1319 HoursUTC 6000;
BA_REL_ "GenSigTimeoutTime" BU_SG_REL_ FAS SG_ 1319 HoursUTC 1500;
BA_REL_ "GenSigFirstTimeoutTime" BU_SG_REL_ FAS SG_ 1319 MinutesUTC 6000;
BA_REL_ "GenSigTimeoutTime" BU_SG_REL_ FAS SG_ 1319 MinutesUTC 1500;
BA_REL_ "GenSigFirstTimeoutTime" BU_SG_REL_ FAS SG_ 1447 FasDampingSetting_rqst 24000;
BA_REL_ "GenSigTimeoutTime" BU_SG_REL_ FAS SG_ 1447 FasDampingSetting_rqst 6000;
BA_REL_ "GenSigFirstTimeoutTime" BU_SG_REL_ FAS SG_ 1447 DriverMemory_rqst 24000;
BA_REL_ "GenSigTimeoutTime" BU_SG_REL_ FAS SG_ 1447 DriverMemory_rqst 6000;
BA_REL_ "GenSigFirstTimeoutTime" BU_SG_REL_ FAS SG_ 1447 FasDriver_rqst 24000;
BA_REL_ "GenSigTimeoutTime" BU_SG_REL_ FAS SG_ 1447 FasDriver_rqst 6000;
BA_REL_ "GenSigFirstTimeoutTime" BU_SG_REL_ FAS SG_ 1447 FasLowSpeedReturnSetting_rqst 24000;
BA_REL_ "GenSigTimeoutTime" BU_SG_REL_ FAS SG_ 1447 FasLowSpeedReturnSetting_rqst 6000;
BA_REL_ "GenSigFirstTimeoutTime" BU_SG_REL_ FAS SG_ 1447 FasPersonalSettingsButton_rqst 24000;
BA_REL_ "GenSigTimeoutTime" BU_SG_REL_ FAS SG_ 1447 FasPersonalSettingsButton_rqst 6000;
BA_REL_ "GenSigFirstTimeoutTime" BU_SG_REL_ FAS SG_ 1447 FasStiffnessCurveSetting_rqst 24000;
BA_REL_ "GenSigTimeoutTime" BU_SG_REL_ FAS SG_ 1447 FasStiffnessCurveSetting_rqst 6000;
BA_REL_ "GenSigFirstTimeoutTime" BU_SG_REL_ FAS SG_ 1447 FasUsrDefinedStorage_rqst 24000;
BA_REL_ "GenSigTimeoutTime" BU_SG_REL_ FAS SG_ 1447 FasUsrDefinedStorage_rqst 6000;
BA_REL_ "GenSigFirstTimeoutTime" BU_SG_REL_ FAS SG_ 1447 FasManualOffsetSetting_rqst 24000;
BA_REL_ "GenSigTimeoutTime" BU_SG_REL_ FAS SG_ 1447 FasManualOffsetSetting_rqst 6000;
BA_REL_ "GenSigFirstTimeoutTime" BU_SG_REL_ FAS SG_ 1447 FasStiffStraightSetting_rqst 24000;
BA_REL_ "GenSigTimeoutTime" BU_SG_REL_ FAS SG_ 1447 FasStiffStraightSetting_rqst 6000;
BA_REL_ "GenSigFirstTimeoutTime" BU_SG_REL_ FAS SG_ 1034 RelativeLevelFrontAxleLeft 3000;
BA_REL_ "GenSigTimeoutTime" BU_SG_REL_ FAS SG_ 1034 RelativeLevelFrontAxleLeft 600;
BA_REL_ "GenSigFirstTimeoutTime" BU_SG_REL_ FAS SG_ 1034 FrontAxle1Load 3000;
BA_REL_ "GenSigTimeoutTime" BU_SG_REL_ FAS SG_ 1034 FrontAxle1Load 600;
BA_REL_ "GenSigFirstTimeoutTime" BU_SG_REL_ EBS SG_ 1034 FrontAxle1Load 3000;
BA_REL_ "GenSigTimeoutTime" BU_SG_REL_ EBS SG_ 1034 FrontAxle1Load 600;
BA_REL_ "GenSigFirstTimeoutTime" BU_SG_REL_ FAS SG_ 1034 PusherAxleLoad 3000;
BA_REL_ "GenSigTimeoutTime" BU_SG_REL_ FAS SG_ 1034 PusherAxleLoad 600;
BA_REL_ "GenSigFirstTimeoutTime" BU_SG_REL_ EBS SG_ 1034 PusherAxleLoad 3000;
BA_REL_ "GenSigTimeoutTime" BU_SG_REL_ EBS SG_ 1034 PusherAxleLoad 600;
BA_REL_ "GenSigFirstTimeoutTime" BU_SG_REL_ FAS SG_ 1034 SecondaryDriveAxleLoad 3000;
BA_REL_ "GenSigTimeoutTime" BU_SG_REL_ FAS SG_ 1034 SecondaryDriveAxleLoad 600;
BA_REL_ "GenSigFirstTimeoutTime" BU_SG_REL_ EBS SG_ 1034 SecondaryDriveAxleLoad 3000;
BA_REL_ "GenSigTimeoutTime" BU_SG_REL_ EBS SG_ 1034 SecondaryDriveAxleLoad 600;
BA_REL_ "GenSigFirstTimeoutTime" BU_SG_REL_ FAS SG_ 1034 TagAxleLoad 3000;
BA_REL_ "GenSigTimeoutTime" BU_SG_REL_ FAS SG_ 1034 TagAxleLoad 600;
BA_REL_ "GenSigFirstTimeoutTime" BU_SG_REL_ EBS SG_ 1034 TagAxleLoad 3000;
BA_REL_ "GenSigTimeoutTime" BU_SG_REL_ EBS SG_ 1034 TagAxleLoad 600;
BA_REL_ "GenSigFirstTimeoutTime" BU_SG_REL_ EBS SG_ 1034 ContTrailerBrake_MsgCounter 3000;
BA_REL_ "GenSigTimeoutTime" BU_SG_REL_ EBS SG_ 1034 ContTrailerBrake_MsgCounter 600;
BA_REL_ "GenSigFirstTimeoutTime" BU_SG_REL_ FAS SG_ 1034 FrontAxle2Load 3000;
BA_REL_ "GenSigTimeoutTime" BU_SG_REL_ FAS SG_ 1034 FrontAxle2Load 600;
BA_REL_ "GenSigFirstTimeoutTime" BU_SG_REL_ EBS SG_ 1034 FrontAxle2Load 3000;
BA_REL_ "GenSigTimeoutTime" BU_SG_REL_ EBS SG_ 1034 FrontAxle2Load 600;
BA_REL_ "GenSigFirstTimeoutTime" BU_SG_REL_ EBS SG_ 1034 DriveAxleLoad 3000;
BA_REL_ "GenSigTimeoutTime" BU_SG_REL_ EBS SG_ 1034 DriveAxleLoad 600;
BA_REL_ "GenSigFirstTimeoutTime" BU_SG_REL_ FAS SG_ 1034 DriveAxleLoad 3000;
BA_REL_ "GenSigTimeoutTime" BU_SG_REL_ FAS SG_ 1034 DriveAxleLoad 600;
BA_REL_ "GenSigFirstTimeoutTime" BU_SG_REL_ EBS SG_ 1034 PBAirLvl_AntiCompoundRatio 3000;
BA_REL_ "GenSigTimeoutTime" BU_SG_REL_ EBS SG_ 1034 PBAirLvl_AntiCompoundRatio 600;
BA_REL_ "GenSigFirstTimeoutTime" BU_SG_REL_ EBS SG_ 1034 ContTrailerBrake_MsgChecksum 3000;
BA_REL_ "GenSigTimeoutTime" BU_SG_REL_ EBS SG_ 1034 ContTrailerBrake_MsgChecksum 600;
BA_REL_ "GenSigFirstTimeoutTime" BU_SG_REL_ EBS SG_ 1034 PBAirLvl_SqC 3000;
BA_REL_ "GenSigTimeoutTime" BU_SG_REL_ EBS SG_ 1034 PBAirLvl_SqC 600;
BA_REL_ "GenSigFirstTimeoutTime" BU_SG_REL_ EBS SG_ 1034 PBStatus_CRC 3000;
BA_REL_ "GenSigTimeoutTime" BU_SG_REL_ EBS SG_ 1034 PBStatus_CRC 600;
BA_REL_ "GenSigFirstTimeoutTime" BU_SG_REL_ EBS SG_ 1034 TertiaryDriveAxleLoad 3000;
BA_REL_ "GenSigTimeoutTime" BU_SG_REL_ EBS SG_ 1034 TertiaryDriveAxleLoad 600;
BA_REL_ "GenSigFirstTimeoutTime" BU_SG_REL_ EBS SG_ 1034 PBStatus_Actuation 3000;
BA_REL_ "GenSigTimeoutTime" BU_SG_REL_ EBS SG_ 1034 PBStatus_Actuation 600;
BA_REL_ "GenSigFirstTimeoutTime" BU_SG_REL_ EBS SG_ 1034 PBStatus_SqC 3000;
BA_REL_ "GenSigTimeoutTime" BU_SG_REL_ EBS SG_ 1034 PBStatus_SqC 600;
BA_REL_ "GenSigFirstTimeoutTime" BU_SG_REL_ EBS SG_ 1034 PBAirLvl_CRC 3000;
BA_REL_ "GenSigTimeoutTime" BU_SG_REL_ EBS SG_ 1034 PBAirLvl_CRC 600;
BA_REL_ "GenSigFirstTimeoutTime" BU_SG_REL_ EBS SG_ 1034 PBStatus_IntegrityLvl 3000;
BA_REL_ "GenSigTimeoutTime" BU_SG_REL_ EBS SG_ 1034 PBStatus_IntegrityLvl 600;
BA_REL_ "GenSigFirstTimeoutTime" BU_SG_REL_ EBS SG_ 1034 ContTrailerBrake_Request 3000;
BA_REL_ "GenSigTimeoutTime" BU_SG_REL_ EBS SG_ 1034 ContTrailerBrake_Request 600;
BA_REL_ "GenSigFirstTimeoutTime" BU_SG_REL_ EBS SG_ 1034 PBAirLvl_PressureInChamber 3000;
BA_REL_ "GenSigTimeoutTime" BU_SG_REL_ EBS SG_ 1034 PBAirLvl_PressureInChamber 600;
BA_REL_ "GenSigFirstTimeoutTime" BU_SG_REL_ EBS SG_ 426 ChangeKneelACK 3000;
BA_REL_ "GenSigTimeoutTime" BU_SG_REL_ EBS SG_ 426 ChangeKneelACK 120;
BA_REL_ "GenSigFirstTimeoutTime" BU_SG_REL_ EBS SG_ 426 LiftAxle1PositionStatus 3000;
BA_REL_ "GenSigTimeoutTime" BU_SG_REL_ EBS SG_ 426 LiftAxle1PositionStatus 120;
BA_REL_ "GenSigFirstTimeoutTime" BU_SG_REL_ EBS SG_ 426 FrontFerryFunctionCmd 3000;
BA_REL_ "GenSigTimeoutTime" BU_SG_REL_ EBS SG_ 426 FrontFerryFunctionCmd 120;
BA_REL_ "GenSigFirstTimeoutTime" BU_SG_REL_ FAS SG_ 426 ReverseGearEngaged 3000;
BA_REL_ "GenSigTimeoutTime" BU_SG_REL_ FAS SG_ 426 ReverseGearEngaged 120;
BA_REL_ "GenSigFirstTimeoutTime" BU_SG_REL_ EBS SG_ 426 AirDumpStatus 3000;
BA_REL_ "GenSigTimeoutTime" BU_SG_REL_ EBS SG_ 426 AirDumpStatus 120;
BA_REL_ "GenSigFirstTimeoutTime" BU_SG_REL_ FAS SG_ 426 EngineActiveStatus 3000;
BA_REL_ "GenSigTimeoutTime" BU_SG_REL_ FAS SG_ 426 EngineActiveStatus 120;
BA_REL_ "GenSigFirstTimeoutTime" BU_SG_REL_ EBS SG_ 426 FerryFunctionStatus 3000;
BA_REL_ "GenSigTimeoutTime" BU_SG_REL_ EBS SG_ 426 FerryFunctionStatus 120;
BA_REL_ "GenSigFirstTimeoutTime" BU_SG_REL_ EBS SG_ 426 PitchAngleRef 3000;
BA_REL_ "GenSigTimeoutTime" BU_SG_REL_ EBS SG_ 426 PitchAngleRef 120;
BA_REL_ "GenSigFirstTimeoutTime" BU_SG_REL_ EBS SG_ 426 APM_LowVMPBInfoReq 3000;
BA_REL_ "GenSigTimeoutTime" BU_SG_REL_ EBS SG_ 426 APM_LowVMPBInfoReq 120;
BA_REL_ "GenSigFirstTimeoutTime" BU_SG_REL_ EBS SG_ 426 KneelingInformation 3000;
BA_REL_ "GenSigTimeoutTime" BU_SG_REL_ EBS SG_ 426 KneelingInformation 120;
BA_REL_ "GenSigFirstTimeoutTime" BU_SG_REL_ FAS SG_ 426 FASHapticFeedbackRequest 3000;
BA_REL_ "GenSigTimeoutTime" BU_SG_REL_ FAS SG_ 426 FASHapticFeedbackRequest 120;
BA_REL_ "GenSigFirstTimeoutTime" BU_SG_REL_ EBS SG_ 426 HeightControlMode 3000;
BA_REL_ "GenSigTimeoutTime" BU_SG_REL_ EBS SG_ 426 HeightControlMode 120;
BA_REL_ "GenSigFirstTimeoutTime" BU_SG_REL_ EBS SG_ 426 LoadDistributionFuncSelected 3000;
BA_REL_ "GenSigTimeoutTime" BU_SG_REL_ EBS SG_ 426 LoadDistributionFuncSelected 120;
BA_REL_ "GenSigFirstTimeoutTime" BU_SG_REL_ EBS SG_ 426 PitchAngle 3000;
BA_REL_ "GenSigTimeoutTime" BU_SG_REL_ EBS SG_ 426 PitchAngle 120;
BA_REL_ "GenSigFirstTimeoutTime" BU_SG_REL_ EBS SG_ 426 RollEndPositionStatus 3000;
BA_REL_ "GenSigTimeoutTime" BU_SG_REL_ EBS SG_ 426 RollEndPositionStatus 120;
BA_REL_ "GenSigFirstTimeoutTime" BU_SG_REL_ EBS SG_ 426 SupplyPressure 3000;
BA_REL_ "GenSigTimeoutTime" BU_SG_REL_ EBS SG_ 426 SupplyPressure 120;
BA_REL_ "GenSigFirstTimeoutTime" BU_SG_REL_ FAS SG_ 426 WheelBasedVehicleSpeed 3000;
BA_REL_ "GenSigTimeoutTime" BU_SG_REL_ FAS SG_ 426 WheelBasedVehicleSpeed 120;
BA_REL_ "GenSigFirstTimeoutTime" BU_SG_REL_ EBS SG_ 426 RearAxle2DiffLock_stat 3000;
BA_REL_ "GenSigTimeoutTime" BU_SG_REL_ EBS SG_ 426 RearAxle2DiffLock_stat 120;
BA_REL_ "GenSigFirstTimeoutTime" BU_SG_REL_ EBS SG_ 426 KneelingStatusHMI 3000;
BA_REL_ "GenSigTimeoutTime" BU_SG_REL_ EBS SG_ 426 KneelingStatusHMI 120;
BA_REL_ "GenSigFirstTimeoutTime" BU_SG_REL_ EBS SG_ 426 HeightAdjustmentAllowed 3000;
BA_REL_ "GenSigTimeoutTime" BU_SG_REL_ EBS SG_ 426 HeightAdjustmentAllowed 120;
BA_REL_ "GenSigFirstTimeoutTime" BU_SG_REL_ EBS SG_ 426 RideHeightStatus 3000;
BA_REL_ "GenSigTimeoutTime" BU_SG_REL_ EBS SG_ 426 RideHeightStatus 120;
BA_REL_ "GenSigFirstTimeoutTime" BU_SG_REL_ EBS SG_ 426 CentralRearDiffLock_stat 3000;
BA_REL_ "GenSigTimeoutTime" BU_SG_REL_ EBS SG_ 426 CentralRearDiffLock_stat 120;
BA_REL_ "GenSigFirstTimeoutTime" BU_SG_REL_ EBS SG_ 426 ParkBrakeReleaseMode2 3000;
BA_REL_ "GenSigTimeoutTime" BU_SG_REL_ EBS SG_ 426 ParkBrakeReleaseMode2 120;
BA_REL_ "GenSigFirstTimeoutTime" BU_SG_REL_ EBS SG_ 426 LiftAxle2PositionStatus 3000;
BA_REL_ "GenSigTimeoutTime" BU_SG_REL_ EBS SG_ 426 LiftAxle2PositionStatus 120;
BA_REL_ "GenSigFirstTimeoutTime" BU_SG_REL_ EBS SG_ 426 RampHeightOutsideTargetRange 3000;
BA_REL_ "GenSigTimeoutTime" BU_SG_REL_ EBS SG_ 426 RampHeightOutsideTargetRange 120;
BA_REL_ "GenSigFirstTimeoutTime" BU_SG_REL_ EBS SG_ 426 DirInd_Rear_Status 3000;
BA_REL_ "GenSigTimeoutTime" BU_SG_REL_ EBS SG_ 426 DirInd_Rear_Status 120;
BA_REL_ "GenSigFirstTimeoutTime" BU_SG_REL_ FAS SG_ 426 ExternalRequestManualStiffness 3000;
BA_REL_ "GenSigTimeoutTime" BU_SG_REL_ FAS SG_ 426 ExternalRequestManualStiffness 120;
BA_REL_ "GenSigFirstTimeoutTime" BU_SG_REL_ EBS SG_ 426 APM_ParkingBrake_stat 3000;
BA_REL_ "GenSigTimeoutTime" BU_SG_REL_ EBS SG_ 426 APM_ParkingBrake_stat 180;
BA_REL_ "GenSigFirstTimeoutTime" BU_SG_REL_ EBS SG_ 426 VehicleDistanceRollingCounter 3000;
BA_REL_ "GenSigTimeoutTime" BU_SG_REL_ EBS SG_ 426 VehicleDistanceRollingCounter 120;
BA_REL_ "GenSigFirstTimeoutTime" BU_SG_REL_ EBS SG_ 426 BackToDriveReqACK 3000;
BA_REL_ "GenSigTimeoutTime" BU_SG_REL_ EBS SG_ 426 BackToDriveReqACK 120;
BA_REL_ "GenSigFirstTimeoutTime" BU_SG_REL_ EBS SG_ 426 RearAxle1DiffLock_stat 3000;
BA_REL_ "GenSigTimeoutTime" BU_SG_REL_ EBS SG_ 426 RearAxle1DiffLock_stat 120;
BA_REL_ "GenSigFirstTimeoutTime" BU_SG_REL_ EBS SG_ 426 LevelControlInformation 3000;
BA_REL_ "GenSigTimeoutTime" BU_SG_REL_ EBS SG_ 426 LevelControlInformation 120;
BA_REL_ "GenSigFirstTimeoutTime" BU_SG_REL_ FAS SG_ 426 VehicleMode 3000;
BA_REL_ "GenSigTimeoutTime" BU_SG_REL_ FAS SG_ 426 VehicleMode 120;
BA_REL_ "GenSigFirstTimeoutTime" BU_SG_REL_ EBS SG_ 426 VehicleMode 3000;
BA_REL_ "GenSigTimeoutTime" BU_SG_REL_ EBS SG_ 426 VehicleMode 120;
BA_REL_ "GenSigFirstTimeoutTime" BU_SG_REL_ FAS SG_ 426 ACC_SGO_Status 3000;
BA_REL_ "GenSigTimeoutTime" BU_SG_REL_ FAS SG_ 426 ACC_SGO_Status 120;
BA_REL_ "GenSigFirstTimeoutTime" BU_SG_REL_ EBS SG_ 426 RearEndPositionStatus 3000;
BA_REL_ "GenSigTimeoutTime" BU_SG_REL_ EBS SG_ 426 RearEndPositionStatus 120;
BA_REL_ "GenSigFirstTimeoutTime" BU_SG_REL_ EBS SG_ 426 ECSShutdownCmd 3000;
BA_REL_ "GenSigTimeoutTime" BU_SG_REL_ EBS SG_ 426 ECSShutdownCmd 120;
BA_REL_ "GenSigFirstTimeoutTime" BU_SG_REL_ EBS SG_ 426 APM_ParkBrakeApplicationMode2 3000;
BA_REL_ "GenSigTimeoutTime" BU_SG_REL_ EBS SG_ 426 APM_ParkBrakeApplicationMode2 120;
BA_REL_ "GenSigFirstTimeoutTime" BU_SG_REL_ EBS SG_ 426 VehicleDynamicSuspProhibitStat 3000;
BA_REL_ "GenSigTimeoutTime" BU_SG_REL_ EBS SG_ 426 VehicleDynamicSuspProhibitStat 120;
BA_REL_ "GenSigFirstTimeoutTime" BU_SG_REL_ FAS SG_ 426 ParkingBrake_stat 3000;
BA_REL_ "GenSigTimeoutTime" BU_SG_REL_ FAS SG_ 426 ParkingBrake_stat 120;
BA_REL_ "GenSigFirstTimeoutTime" BU_SG_REL_ EBS SG_ 426 RideHeightFunctionStatus 3000;
BA_REL_ "GenSigTimeoutTime" BU_SG_REL_ EBS SG_ 426 RideHeightFunctionStatus 120;
BA_REL_ "GenSigFirstTimeoutTime" BU_SG_REL_ EBS SG_ 426 APM_TrailerCircPressureStatus 3000;
BA_REL_ "GenSigTimeoutTime" BU_SG_REL_ EBS SG_ 426 APM_TrailerCircPressureStatus 120;
VAL_ 266 ZxbrReqVeh_RetModReq 7 "RetModReq_NotAvailable" 6 "RetModReq_Error" 5 "RetModReq_Spare3" 4 "RetModReq_Spare2" 3 "RetModReq_Spare1" 2 "RetModReq_Maximum" 1 "RetModReq_Addition" 0 "RetModReq_Inactive" ;
VAL_ 266 ZxbrReqVeh_VmmModSts 15 "VmmModSts_NotAvailable" 14 "VmmModSts_Error" 13 "VmmModSts_NotOperational13" 12 "VmmModSts_NotOperational12" 11 "VmmModSts_NotOperational11" 10 "VmmModSts_NotOperational10" 9 "VmmModSts_NotOperational9" 8 "VmmModSts_NotOperational8" 7 "VmmModSts_NotOperational7" 6 "VmmModSts_NotOperational6" 5 "VmmModSts_NotOperational5" 4 "VmmModSts_NotOperational4" 3 "VmmModSts_NotOperational3" 2 "VmmModSts_Operational" 1 "VmmModSts_NotOperational2" 0 "VmmModSts_NotOperational1" ;
VAL_ 266 ZxbrReqVeh_RetEbiModReq 7 "EbiMode3bit_NotAvailable" 6 "EbiMode3bit_Error" 5 "EbiMode3bit_Spare2" 4 "EbiMode3bit_Spare1" 3 "EbiMode3bit_Spare0" 2 "EbiMode3bit_EnduranceBrakeIntegrationAllowed" 1 "EbiMode3bit_OnlyEnduranceBrakesAllowed" 0 "EbiMode3bit_NoEnduranceBrakeIntegrationAllowed" ;
VAL_ 266 ZxbrReqVeh_DrvrModReq 3 "DrvrModReq_NotAvailable" 2 "DrvrModReq_Error" 1 "DrvrModReq_AutonomousControl" 0 "DrvrModReq_ManualControl" ;
VAL_ 262 IxbrReqAxle4_SlipCtrlEna 3 "DisableEnable_NotAvailable" 2 "DisableEnable_Error" 1 "DisableEnable_Enable" 0 "DisableEnable_Disable" ;
VAL_ 262 IxbrReqAxle5_SlipCtrlEna 3 "DisableEnable_NotAvailable" 2 "DisableEnable_Error" 1 "DisableEnable_Enable" 0 "DisableEnable_Disable" ;
VAL_ 262 IxbrReqAxle5_VehSpdLgtWhlQltyLe 15 "QualityEnum4Bit_NotAvailable" 14 "QualityEnum4Bit_Error" 13 "QualityEnum4Bit_Spare12" 12 "QualityEnum4Bit_Spare11" 11 "QualityEnum4Bit_Spare10" 10 "QualityEnum4Bit_Spare9" 9 "QualityEnum4Bit_Spare8" 8 "QualityEnum4Bit_Spare7" 7 "QualityEnum4Bit_Spare6" 6 "QualityEnum4Bit_Spare5" 5 "QualityEnum4Bit_Spare4" 4 "QualityEnum4Bit_Spare3" 3 "QualityEnum4Bit_Spare2" 2 "QualityEnum4Bit_Spare1" 1 "QualityEnum4Bit_Acceptable" 0 "QualityEnum4Bit_NotAcceptable" ;
VAL_ 262 IxbrReqAxle6_VehSpdLgtWhlQltyRi 15 "QualityEnum4Bit_NotAvailable" 14 "QualityEnum4Bit_Error" 13 "QualityEnum4Bit_Spare12" 12 "QualityEnum4Bit_Spare11" 11 "QualityEnum4Bit_Spare10" 10 "QualityEnum4Bit_Spare9" 9 "QualityEnum4Bit_Spare8" 8 "QualityEnum4Bit_Spare7" 7 "QualityEnum4Bit_Spare6" 6 "QualityEnum4Bit_Spare5" 5 "QualityEnum4Bit_Spare4" 4 "QualityEnum4Bit_Spare3" 3 "QualityEnum4Bit_Spare2" 2 "QualityEnum4Bit_Spare1" 1 "QualityEnum4Bit_Acceptable" 0 "QualityEnum4Bit_NotAcceptable" ;
VAL_ 262 IxbrReqAxle4_VehSpdLgtWhlQltyRi 15 "QualityEnum4Bit_NotAvailable" 14 "QualityEnum4Bit_Error" 13 "QualityEnum4Bit_Spare12" 12 "QualityEnum4Bit_Spare11" 11 "QualityEnum4Bit_Spare10" 10 "QualityEnum4Bit_Spare9" 9 "QualityEnum4Bit_Spare8" 8 "QualityEnum4Bit_Spare7" 7 "QualityEnum4Bit_Spare6" 6 "QualityEnum4Bit_Spare5" 5 "QualityEnum4Bit_Spare4" 4 "QualityEnum4Bit_Spare3" 3 "QualityEnum4Bit_Spare2" 2 "QualityEnum4Bit_Spare1" 1 "QualityEnum4Bit_Acceptable" 0 "QualityEnum4Bit_NotAcceptable" ;
VAL_ 262 IxbrReqAxle4_IxbrModReq 7 "IxbrModReq_NotAvailable" 6 "IxbrModReq_Error" 5 "IxbrModReq_Spare5" 4 "IxbrModReq_Spare4" 3 "IxbrModReq_Spare3" 2 "IxbrModReq_Spare2" 1 "IxbrModReq_Spare1" 0 "IxbrModReq_Spare0" ;
VAL_ 262 IxbrReqAxle6_SlipCtrlEna 3 "DisableEnable_NotAvailable" 2 "DisableEnable_Error" 1 "DisableEnable_Enable" 0 "DisableEnable_Disable" ;
VAL_ 262 IxbrReqAxle4_VehSpdLgtWhlQltyLe 15 "QualityEnum4Bit_NotAvailable" 14 "QualityEnum4Bit_Error" 13 "QualityEnum4Bit_Spare12" 12 "QualityEnum4Bit_Spare11" 11 "QualityEnum4Bit_Spare10" 10 "QualityEnum4Bit_Spare9" 9 "QualityEnum4Bit_Spare8" 8 "QualityEnum4Bit_Spare7" 7 "QualityEnum4Bit_Spare6" 6 "QualityEnum4Bit_Spare5" 5 "QualityEnum4Bit_Spare4" 4 "QualityEnum4Bit_Spare3" 3 "QualityEnum4Bit_Spare2" 2 "QualityEnum4Bit_Spare1" 1 "QualityEnum4Bit_Acceptable" 0 "QualityEnum4Bit_NotAcceptable" ;
VAL_ 262 IxbrReqAxle6_VehSpdLgtWhlQltyLe 15 "QualityEnum4Bit_NotAvailable" 14 "QualityEnum4Bit_Error" 13 "QualityEnum4Bit_Spare12" 12 "QualityEnum4Bit_Spare11" 11 "QualityEnum4Bit_Spare10" 10 "QualityEnum4Bit_Spare9" 9 "QualityEnum4Bit_Spare8" 8 "QualityEnum4Bit_Spare7" 7 "QualityEnum4Bit_Spare6" 6 "QualityEnum4Bit_Spare5" 5 "QualityEnum4Bit_Spare4" 4 "QualityEnum4Bit_Spare3" 3 "QualityEnum4Bit_Spare2" 2 "QualityEnum4Bit_Spare1" 1 "QualityEnum4Bit_Acceptable" 0 "QualityEnum4Bit_NotAcceptable" ;
VAL_ 262 IxbrReqAxle5_VehSpdLgtWhlQltyRi 15 "QualityEnum4Bit_NotAvailable" 14 "QualityEnum4Bit_Error" 13 "QualityEnum4Bit_Spare12" 12 "QualityEnum4Bit_Spare11" 11 "QualityEnum4Bit_Spare10" 10 "QualityEnum4Bit_Spare9" 9 "QualityEnum4Bit_Spare8" 8 "QualityEnum4Bit_Spare7" 7 "QualityEnum4Bit_Spare6" 6 "QualityEnum4Bit_Spare5" 5 "QualityEnum4Bit_Spare4" 4 "QualityEnum4Bit_Spare3" 3 "QualityEnum4Bit_Spare2" 2 "QualityEnum4Bit_Spare1" 1 "QualityEnum4Bit_Acceptable" 0 "QualityEnum4Bit_NotAcceptable" ;
VAL_ 262 IxbrReqAxle5_IxbrModReq 7 "IxbrModReq_NotAvailable" 6 "IxbrModReq_Error" 5 "IxbrModReq_Spare5" 4 "IxbrModReq_Spare4" 3 "IxbrModReq_Spare3" 2 "IxbrModReq_Spare2" 1 "IxbrModReq_Spare1" 0 "IxbrModReq_Spare0" ;
VAL_ 262 IxbrReqAxle6_IxbrModReq 7 "IxbrModReq_NotAvailable" 6 "IxbrModReq_Error" 5 "IxbrModReq_Spare5" 4 "IxbrModReq_Spare4" 3 "IxbrModReq_Spare3" 2 "IxbrModReq_Spare2" 1 "IxbrModReq_Spare1" 0 "IxbrModReq_Spare0" ;
VAL_ 261 IxbrReqAxle1_VehSpdLgtWhlQltyRi 15 "QualityEnum4Bit_NotAvailable" 14 "QualityEnum4Bit_Error" 13 "QualityEnum4Bit_Spare12" 12 "QualityEnum4Bit_Spare11" 11 "QualityEnum4Bit_Spare10" 10 "QualityEnum4Bit_Spare9" 9 "QualityEnum4Bit_Spare8" 8 "QualityEnum4Bit_Spare7" 7 "QualityEnum4Bit_Spare6" 6 "QualityEnum4Bit_Spare5" 5 "QualityEnum4Bit_Spare4" 4 "QualityEnum4Bit_Spare3" 3 "QualityEnum4Bit_Spare2" 2 "QualityEnum4Bit_Spare1" 1 "QualityEnum4Bit_Acceptable" 0 "QualityEnum4Bit_NotAcceptable" ;
VAL_ 261 IxbrReqAxle1_SlipCtrlEna 3 "DisableEnable_NotAvailable" 2 "DisableEnable_Error" 1 "DisableEnable_Enable" 0 "DisableEnable_Disable" ;
VAL_ 261 IxbrReqAxle2_SlipCtrlEna 3 "DisableEnable_NotAvailable" 2 "DisableEnable_Error" 1 "DisableEnable_Enable" 0 "DisableEnable_Disable" ;
VAL_ 261 IxbrReqAxle1_IxbrModReq 7 "IxbrModReq_NotAvailable" 6 "IxbrModReq_Error" 5 "IxbrModReq_Spare5" 4 "IxbrModReq_Spare4" 3 "IxbrModReq_Spare3" 2 "IxbrModReq_Spare2" 1 "IxbrModReq_Spare1" 0 "IxbrModReq_Spare0" ;
VAL_ 261 IxbrReqAxle3_VehSpdLgtWhlQltyLe 15 "QualityEnum4Bit_NotAvailable" 14 "QualityEnum4Bit_Error" 13 "QualityEnum4Bit_Spare12" 12 "QualityEnum4Bit_Spare11" 11 "QualityEnum4Bit_Spare10" 10 "QualityEnum4Bit_Spare9" 9 "QualityEnum4Bit_Spare8" 8 "QualityEnum4Bit_Spare7" 7 "QualityEnum4Bit_Spare6" 6 "QualityEnum4Bit_Spare5" 5 "QualityEnum4Bit_Spare4" 4 "QualityEnum4Bit_Spare3" 3 "QualityEnum4Bit_Spare2" 2 "QualityEnum4Bit_Spare1" 1 "QualityEnum4Bit_Acceptable" 0 "QualityEnum4Bit_NotAcceptable" ;
VAL_ 261 IxbrReqAxle2_IxbrModReq 7 "IxbrModReq_NotAvailable" 6 "IxbrModReq_Error" 5 "IxbrModReq_Spare5" 4 "IxbrModReq_Spare4" 3 "IxbrModReq_Spare3" 2 "IxbrModReq_Spare2" 1 "IxbrModReq_Spare1" 0 "IxbrModReq_Spare0" ;
VAL_ 261 IxbrReqAxle3_VehSpdLgtWhlQltyRi 15 "QualityEnum4Bit_NotAvailable" 14 "QualityEnum4Bit_Error" 13 "QualityEnum4Bit_Spare12" 12 "QualityEnum4Bit_Spare11" 11 "QualityEnum4Bit_Spare10" 10 "QualityEnum4Bit_Spare9" 9 "QualityEnum4Bit_Spare8" 8 "QualityEnum4Bit_Spare7" 7 "QualityEnum4Bit_Spare6" 6 "QualityEnum4Bit_Spare5" 5 "QualityEnum4Bit_Spare4" 4 "QualityEnum4Bit_Spare3" 3 "QualityEnum4Bit_Spare2" 2 "QualityEnum4Bit_Spare1" 1 "QualityEnum4Bit_Acceptable" 0 "QualityEnum4Bit_NotAcceptable" ;
VAL_ 261 IxbrReqAxle1_VehSpdLgtWhlQltyLe 15 "QualityEnum4Bit_NotAvailable" 14 "QualityEnum4Bit_Error" 13 "QualityEnum4Bit_Spare12" 12 "QualityEnum4Bit_Spare11" 11 "QualityEnum4Bit_Spare10" 10 "QualityEnum4Bit_Spare9" 9 "QualityEnum4Bit_Spare8" 8 "QualityEnum4Bit_Spare7" 7 "QualityEnum4Bit_Spare6" 6 "QualityEnum4Bit_Spare5" 5 "QualityEnum4Bit_Spare4" 4 "QualityEnum4Bit_Spare3" 3 "QualityEnum4Bit_Spare2" 2 "QualityEnum4Bit_Spare1" 1 "QualityEnum4Bit_Acceptable" 0 "QualityEnum4Bit_NotAcceptable" ;
VAL_ 261 IxbrReqAxle3_IxbrModReq 7 "IxbrModReq_NotAvailable" 6 "IxbrModReq_Error" 5 "IxbrModReq_Spare5" 4 "IxbrModReq_Spare4" 3 "IxbrModReq_Spare3" 2 "IxbrModReq_Spare2" 1 "IxbrModReq_Spare1" 0 "IxbrModReq_Spare0" ;
VAL_ 261 IxbrReqAxle2_VehSpdLgtWhlQltyLe 15 "QualityEnum4Bit_NotAvailable" 14 "QualityEnum4Bit_Error" 13 "QualityEnum4Bit_Spare12" 12 "QualityEnum4Bit_Spare11" 11 "QualityEnum4Bit_Spare10" 10 "QualityEnum4Bit_Spare9" 9 "QualityEnum4Bit_Spare8" 8 "QualityEnum4Bit_Spare7" 7 "QualityEnum4Bit_Spare6" 6 "QualityEnum4Bit_Spare5" 5 "QualityEnum4Bit_Spare4" 4 "QualityEnum4Bit_Spare3" 3 "QualityEnum4Bit_Spare2" 2 "QualityEnum4Bit_Spare1" 1 "QualityEnum4Bit_Acceptable" 0 "QualityEnum4Bit_NotAcceptable" ;
VAL_ 261 IxbrReqAxle3_SlipCtrlEna 3 "DisableEnable_NotAvailable" 2 "DisableEnable_Error" 1 "DisableEnable_Enable" 0 "DisableEnable_Disable" ;
VAL_ 261 IxbrReqAxle2_VehSpdLgtWhlQltyRi 15 "QualityEnum4Bit_NotAvailable" 14 "QualityEnum4Bit_Error" 13 "QualityEnum4Bit_Spare12" 12 "QualityEnum4Bit_Spare11" 11 "QualityEnum4Bit_Spare10" 10 "QualityEnum4Bit_Spare9" 9 "QualityEnum4Bit_Spare8" 8 "QualityEnum4Bit_Spare7" 7 "QualityEnum4Bit_Spare6" 6 "QualityEnum4Bit_Spare5" 5 "QualityEnum4Bit_Spare4" 4 "QualityEnum4Bit_Spare3" 3 "QualityEnum4Bit_Spare2" 2 "QualityEnum4Bit_Spare1" 1 "QualityEnum4Bit_Acceptable" 0 "QualityEnum4Bit_NotAcceptable" ;
VAL_ 554 EstAxle6_WhlRdEstQltyRi 15 "QualityEnum4Bit_NotAvailable" 14 "QualityEnum4Bit_Error" 13 "QualityEnum4Bit_Spare12" 12 "QualityEnum4Bit_Spare11" 11 "QualityEnum4Bit_Spare10" 10 "QualityEnum4Bit_Spare9" 9 "QualityEnum4Bit_Spare8" 8 "QualityEnum4Bit_Spare7" 7 "QualityEnum4Bit_Spare6" 6 "QualityEnum4Bit_Spare5" 5 "QualityEnum4Bit_Spare4" 4 "QualityEnum4Bit_Spare3" 3 "QualityEnum4Bit_Spare2" 2 "QualityEnum4Bit_Spare1" 1 "QualityEnum4Bit_Acceptable" 0 "QualityEnum4Bit_NotAcceptable" ;
VAL_ 554 EstAxle5_WhlRdEstQltyRi 15 "QualityEnum4Bit_NotAvailable" 14 "QualityEnum4Bit_Error" 13 "QualityEnum4Bit_Spare12" 12 "QualityEnum4Bit_Spare11" 11 "QualityEnum4Bit_Spare10" 10 "QualityEnum4Bit_Spare9" 9 "QualityEnum4Bit_Spare8" 8 "QualityEnum4Bit_Spare7" 7 "QualityEnum4Bit_Spare6" 6 "QualityEnum4Bit_Spare5" 5 "QualityEnum4Bit_Spare4" 4 "QualityEnum4Bit_Spare3" 3 "QualityEnum4Bit_Spare2" 2 "QualityEnum4Bit_Spare1" 1 "QualityEnum4Bit_Acceptable" 0 "QualityEnum4Bit_NotAcceptable" ;
VAL_ 554 EstAxle2_LoadNormQltyLe 15 "QualityEnum4Bit_NotAvailable" 14 "QualityEnum4Bit_Error" 13 "QualityEnum4Bit_Spare12" 12 "QualityEnum4Bit_Spare11" 11 "QualityEnum4Bit_Spare10" 10 "QualityEnum4Bit_Spare9" 9 "QualityEnum4Bit_Spare8" 8 "QualityEnum4Bit_Spare7" 7 "QualityEnum4Bit_Spare6" 6 "QualityEnum4Bit_Spare5" 5 "QualityEnum4Bit_Spare4" 4 "QualityEnum4Bit_Spare3" 3 "QualityEnum4Bit_Spare2" 2 "QualityEnum4Bit_Spare1" 1 "QualityEnum4Bit_Acceptable" 0 "QualityEnum4Bit_NotAcceptable" ;
VAL_ 554 EstAxle3_LoadNormQltyRi 15 "QualityEnum4Bit_NotAvailable" 14 "QualityEnum4Bit_Error" 13 "QualityEnum4Bit_Spare12" 12 "QualityEnum4Bit_Spare11" 11 "QualityEnum4Bit_Spare10" 10 "QualityEnum4Bit_Spare9" 9 "QualityEnum4Bit_Spare8" 8 "QualityEnum4Bit_Spare7" 7 "QualityEnum4Bit_Spare6" 6 "QualityEnum4Bit_Spare5" 5 "QualityEnum4Bit_Spare4" 4 "QualityEnum4Bit_Spare3" 3 "QualityEnum4Bit_Spare2" 2 "QualityEnum4Bit_Spare1" 1 "QualityEnum4Bit_Acceptable" 0 "QualityEnum4Bit_NotAcceptable" ;
VAL_ 554 EstAxle4_LoadNormQltyRi 15 "QualityEnum4Bit_NotAvailable" 14 "QualityEnum4Bit_Error" 13 "QualityEnum4Bit_Spare12" 12 "QualityEnum4Bit_Spare11" 11 "QualityEnum4Bit_Spare10" 10 "QualityEnum4Bit_Spare9" 9 "QualityEnum4Bit_Spare8" 8 "QualityEnum4Bit_Spare7" 7 "QualityEnum4Bit_Spare6" 6 "QualityEnum4Bit_Spare5" 5 "QualityEnum4Bit_Spare4" 4 "QualityEnum4Bit_Spare3" 3 "QualityEnum4Bit_Spare2" 2 "QualityEnum4Bit_Spare1" 1 "QualityEnum4Bit_Acceptable" 0 "QualityEnum4Bit_NotAcceptable" ;
VAL_ 554 EstAxle5_LoadNormQltyRi 15 "QualityEnum4Bit_NotAvailable" 14 "QualityEnum4Bit_Error" 13 "QualityEnum4Bit_Spare12" 12 "QualityEnum4Bit_Spare11" 11 "QualityEnum4Bit_Spare10" 10 "QualityEnum4Bit_Spare9" 9 "QualityEnum4Bit_Spare8" 8 "QualityEnum4Bit_Spare7" 7 "QualityEnum4Bit_Spare6" 6 "QualityEnum4Bit_Spare5" 5 "QualityEnum4Bit_Spare4" 4 "QualityEnum4Bit_Spare3" 3 "QualityEnum4Bit_Spare2" 2 "QualityEnum4Bit_Spare1" 1 "QualityEnum4Bit_Acceptable" 0 "QualityEnum4Bit_NotAcceptable" ;
VAL_ 554 EstAxle6_WhlRdEstQltyLe 15 "QualityEnum4Bit_NotAvailable" 14 "QualityEnum4Bit_Error" 13 "QualityEnum4Bit_Spare12" 12 "QualityEnum4Bit_Spare11" 11 "QualityEnum4Bit_Spare10" 10 "QualityEnum4Bit_Spare9" 9 "QualityEnum4Bit_Spare8" 8 "QualityEnum4Bit_Spare7" 7 "QualityEnum4Bit_Spare6" 6 "QualityEnum4Bit_Spare5" 5 "QualityEnum4Bit_Spare4" 4 "QualityEnum4Bit_Spare3" 3 "QualityEnum4Bit_Spare2" 2 "QualityEnum4Bit_Spare1" 1 "QualityEnum4Bit_Acceptable" 0 "QualityEnum4Bit_NotAcceptable" ;
VAL_ 554 EstAxle5_LoadNormQltyLe 15 "QualityEnum4Bit_NotAvailable" 14 "QualityEnum4Bit_Error" 13 "QualityEnum4Bit_Spare12" 12 "QualityEnum4Bit_Spare11" 11 "QualityEnum4Bit_Spare10" 10 "QualityEnum4Bit_Spare9" 9 "QualityEnum4Bit_Spare8" 8 "QualityEnum4Bit_Spare7" 7 "QualityEnum4Bit_Spare6" 6 "QualityEnum4Bit_Spare5" 5 "QualityEnum4Bit_Spare4" 4 "QualityEnum4Bit_Spare3" 3 "QualityEnum4Bit_Spare2" 2 "QualityEnum4Bit_Spare1" 1 "QualityEnum4Bit_Acceptable" 0 "QualityEnum4Bit_NotAcceptable" ;
VAL_ 554 EstAxle3_WhlRdEstQltyLe 15 "QualityEnum4Bit_NotAvailable" 14 "QualityEnum4Bit_Error" 13 "QualityEnum4Bit_Spare12" 12 "QualityEnum4Bit_Spare11" 11 "QualityEnum4Bit_Spare10" 10 "QualityEnum4Bit_Spare9" 9 "QualityEnum4Bit_Spare8" 8 "QualityEnum4Bit_Spare7" 7 "QualityEnum4Bit_Spare6" 6 "QualityEnum4Bit_Spare5" 5 "QualityEnum4Bit_Spare4" 4 "QualityEnum4Bit_Spare3" 3 "QualityEnum4Bit_Spare2" 2 "QualityEnum4Bit_Spare1" 1 "QualityEnum4Bit_Acceptable" 0 "QualityEnum4Bit_NotAcceptable" ;
VAL_ 554 EstAxle4_WhlRdEstQltyRi 15 "QualityEnum4Bit_NotAvailable" 14 "QualityEnum4Bit_Error" 13 "QualityEnum4Bit_Spare12" 12 "QualityEnum4Bit_Spare11" 11 "QualityEnum4Bit_Spare10" 10 "QualityEnum4Bit_Spare9" 9 "QualityEnum4Bit_Spare8" 8 "QualityEnum4Bit_Spare7" 7 "QualityEnum4Bit_Spare6" 6 "QualityEnum4Bit_Spare5" 5 "QualityEnum4Bit_Spare4" 4 "QualityEnum4Bit_Spare3" 3 "QualityEnum4Bit_Spare2" 2 "QualityEnum4Bit_Spare1" 1 "QualityEnum4Bit_Acceptable" 0 "QualityEnum4Bit_NotAcceptable" ;
VAL_ 554 EstAxle6_LoadNormQltyRi 15 "QualityEnum4Bit_NotAvailable" 14 "QualityEnum4Bit_Error" 13 "QualityEnum4Bit_Spare12" 12 "QualityEnum4Bit_Spare11" 11 "QualityEnum4Bit_Spare10" 10 "QualityEnum4Bit_Spare9" 9 "QualityEnum4Bit_Spare8" 8 "QualityEnum4Bit_Spare7" 7 "QualityEnum4Bit_Spare6" 6 "QualityEnum4Bit_Spare5" 5 "QualityEnum4Bit_Spare4" 4 "QualityEnum4Bit_Spare3" 3 "QualityEnum4Bit_Spare2" 2 "QualityEnum4Bit_Spare1" 1 "QualityEnum4Bit_Acceptable" 0 "QualityEnum4Bit_NotAcceptable" ;
VAL_ 554 EstAxle1_LoadNormQltyRi 15 "QualityEnum4Bit_NotAvailable" 14 "QualityEnum4Bit_Error" 13 "QualityEnum4Bit_Spare12" 12 "QualityEnum4Bit_Spare11" 11 "QualityEnum4Bit_Spare10" 10 "QualityEnum4Bit_Spare9" 9 "QualityEnum4Bit_Spare8" 8 "QualityEnum4Bit_Spare7" 7 "QualityEnum4Bit_Spare6" 6 "QualityEnum4Bit_Spare5" 5 "QualityEnum4Bit_Spare4" 4 "QualityEnum4Bit_Spare3" 3 "QualityEnum4Bit_Spare2" 2 "QualityEnum4Bit_Spare1" 1 "QualityEnum4Bit_Acceptable" 0 "QualityEnum4Bit_NotAcceptable" ;
VAL_ 554 EstAxle1_LoadNormQltyLe 15 "QualityEnum4Bit_NotAvailable" 14 "QualityEnum4Bit_Error" 13 "QualityEnum4Bit_Spare12" 12 "QualityEnum4Bit_Spare11" 11 "QualityEnum4Bit_Spare10" 10 "QualityEnum4Bit_Spare9" 9 "QualityEnum4Bit_Spare8" 8 "QualityEnum4Bit_Spare7" 7 "QualityEnum4Bit_Spare6" 6 "QualityEnum4Bit_Spare5" 5 "QualityEnum4Bit_Spare4" 4 "QualityEnum4Bit_Spare3" 3 "QualityEnum4Bit_Spare2" 2 "QualityEnum4Bit_Spare1" 1 "QualityEnum4Bit_Acceptable" 0 "QualityEnum4Bit_NotAcceptable" ;
VAL_ 554 EstAxle4_WhlRdEstQltyLe 15 "QualityEnum4Bit_NotAvailable" 14 "QualityEnum4Bit_Error" 13 "QualityEnum4Bit_Spare12" 12 "QualityEnum4Bit_Spare11" 11 "QualityEnum4Bit_Spare10" 10 "QualityEnum4Bit_Spare9" 9 "QualityEnum4Bit_Spare8" 8 "QualityEnum4Bit_Spare7" 7 "QualityEnum4Bit_Spare6" 6 "QualityEnum4Bit_Spare5" 5 "QualityEnum4Bit_Spare4" 4 "QualityEnum4Bit_Spare3" 3 "QualityEnum4Bit_Spare2" 2 "QualityEnum4Bit_Spare1" 1 "QualityEnum4Bit_Acceptable" 0 "QualityEnum4Bit_NotAcceptable" ;
VAL_ 554 EstAxle1_WhlRdEstQltyLe 15 "QualityEnum4Bit_NotAvailable" 14 "QualityEnum4Bit_Error" 13 "QualityEnum4Bit_Spare12" 12 "QualityEnum4Bit_Spare11" 11 "QualityEnum4Bit_Spare10" 10 "QualityEnum4Bit_Spare9" 9 "QualityEnum4Bit_Spare8" 8 "QualityEnum4Bit_Spare7" 7 "QualityEnum4Bit_Spare6" 6 "QualityEnum4Bit_Spare5" 5 "QualityEnum4Bit_Spare4" 4 "QualityEnum4Bit_Spare3" 3 "QualityEnum4Bit_Spare2" 2 "QualityEnum4Bit_Spare1" 1 "QualityEnum4Bit_Acceptable" 0 "QualityEnum4Bit_NotAcceptable" ;
VAL_ 554 EstAxle2_LoadNormQltyRi 15 "QualityEnum4Bit_NotAvailable" 14 "QualityEnum4Bit_Error" 13 "QualityEnum4Bit_Spare12" 12 "QualityEnum4Bit_Spare11" 11 "QualityEnum4Bit_Spare10" 10 "QualityEnum4Bit_Spare9" 9 "QualityEnum4Bit_Spare8" 8 "QualityEnum4Bit_Spare7" 7 "QualityEnum4Bit_Spare6" 6 "QualityEnum4Bit_Spare5" 5 "QualityEnum4Bit_Spare4" 4 "QualityEnum4Bit_Spare3" 3 "QualityEnum4Bit_Spare2" 2 "QualityEnum4Bit_Spare1" 1 "QualityEnum4Bit_Acceptable" 0 "QualityEnum4Bit_NotAcceptable" ;
VAL_ 554 EstAxle3_LoadNormQltyLe 15 "QualityEnum4Bit_NotAvailable" 14 "QualityEnum4Bit_Error" 13 "QualityEnum4Bit_Spare12" 12 "QualityEnum4Bit_Spare11" 11 "QualityEnum4Bit_Spare10" 10 "QualityEnum4Bit_Spare9" 9 "QualityEnum4Bit_Spare8" 8 "QualityEnum4Bit_Spare7" 7 "QualityEnum4Bit_Spare6" 6 "QualityEnum4Bit_Spare5" 5 "QualityEnum4Bit_Spare4" 4 "QualityEnum4Bit_Spare3" 3 "QualityEnum4Bit_Spare2" 2 "QualityEnum4Bit_Spare1" 1 "QualityEnum4Bit_Acceptable" 0 "QualityEnum4Bit_NotAcceptable" ;
VAL_ 554 EstAxle4_LoadNormQltyLe 15 "QualityEnum4Bit_NotAvailable" 14 "QualityEnum4Bit_Error" 13 "QualityEnum4Bit_Spare12" 12 "QualityEnum4Bit_Spare11" 11 "QualityEnum4Bit_Spare10" 10 "QualityEnum4Bit_Spare9" 9 "QualityEnum4Bit_Spare8" 8 "QualityEnum4Bit_Spare7" 7 "QualityEnum4Bit_Spare6" 6 "QualityEnum4Bit_Spare5" 5 "QualityEnum4Bit_Spare4" 4 "QualityEnum4Bit_Spare3" 3 "QualityEnum4Bit_Spare2" 2 "QualityEnum4Bit_Spare1" 1 "QualityEnum4Bit_Acceptable" 0 "QualityEnum4Bit_NotAcceptable" ;
VAL_ 554 EstAxle2_WhlRdEstQltyRi 15 "QualityEnum4Bit_NotAvailable" 14 "QualityEnum4Bit_Error" 13 "QualityEnum4Bit_Spare12" 12 "QualityEnum4Bit_Spare11" 11 "QualityEnum4Bit_Spare10" 10 "QualityEnum4Bit_Spare9" 9 "QualityEnum4Bit_Spare8" 8 "QualityEnum4Bit_Spare7" 7 "QualityEnum4Bit_Spare6" 6 "QualityEnum4Bit_Spare5" 5 "QualityEnum4Bit_Spare4" 4 "QualityEnum4Bit_Spare3" 3 "QualityEnum4Bit_Spare2" 2 "QualityEnum4Bit_Spare1" 1 "QualityEnum4Bit_Acceptable" 0 "QualityEnum4Bit_NotAcceptable" ;
VAL_ 554 EstAxle6_LoadNormQltyLe 15 "QualityEnum4Bit_NotAvailable" 14 "QualityEnum4Bit_Error" 13 "QualityEnum4Bit_Spare12" 12 "QualityEnum4Bit_Spare11" 11 "QualityEnum4Bit_Spare10" 10 "QualityEnum4Bit_Spare9" 9 "QualityEnum4Bit_Spare8" 8 "QualityEnum4Bit_Spare7" 7 "QualityEnum4Bit_Spare6" 6 "QualityEnum4Bit_Spare5" 5 "QualityEnum4Bit_Spare4" 4 "QualityEnum4Bit_Spare3" 3 "QualityEnum4Bit_Spare2" 2 "QualityEnum4Bit_Spare1" 1 "QualityEnum4Bit_Acceptable" 0 "QualityEnum4Bit_NotAcceptable" ;
VAL_ 554 EstAxle3_WhlRdEstQltyRi 15 "QualityEnum4Bit_NotAvailable" 14 "QualityEnum4Bit_Error" 13 "QualityEnum4Bit_Spare12" 12 "QualityEnum4Bit_Spare11" 11 "QualityEnum4Bit_Spare10" 10 "QualityEnum4Bit_Spare9" 9 "QualityEnum4Bit_Spare8" 8 "QualityEnum4Bit_Spare7" 7 "QualityEnum4Bit_Spare6" 6 "QualityEnum4Bit_Spare5" 5 "QualityEnum4Bit_Spare4" 4 "QualityEnum4Bit_Spare3" 3 "QualityEnum4Bit_Spare2" 2 "QualityEnum4Bit_Spare1" 1 "QualityEnum4Bit_Acceptable" 0 "QualityEnum4Bit_NotAcceptable" ;
VAL_ 554 EstAxle2_WhlRdEstQltyLe 15 "QualityEnum4Bit_NotAvailable" 14 "QualityEnum4Bit_Error" 13 "QualityEnum4Bit_Spare12" 12 "QualityEnum4Bit_Spare11" 11 "QualityEnum4Bit_Spare10" 10 "QualityEnum4Bit_Spare9" 9 "QualityEnum4Bit_Spare8" 8 "QualityEnum4Bit_Spare7" 7 "QualityEnum4Bit_Spare6" 6 "QualityEnum4Bit_Spare5" 5 "QualityEnum4Bit_Spare4" 4 "QualityEnum4Bit_Spare3" 3 "QualityEnum4Bit_Spare2" 2 "QualityEnum4Bit_Spare1" 1 "QualityEnum4Bit_Acceptable" 0 "QualityEnum4Bit_NotAcceptable" ;
VAL_ 554 EstAxle5_WhlRdEstQltyLe 15 "QualityEnum4Bit_NotAvailable" 14 "QualityEnum4Bit_Error" 13 "QualityEnum4Bit_Spare12" 12 "QualityEnum4Bit_Spare11" 11 "QualityEnum4Bit_Spare10" 10 "QualityEnum4Bit_Spare9" 9 "QualityEnum4Bit_Spare8" 8 "QualityEnum4Bit_Spare7" 7 "QualityEnum4Bit_Spare6" 6 "QualityEnum4Bit_Spare5" 5 "QualityEnum4Bit_Spare4" 4 "QualityEnum4Bit_Spare3" 3 "QualityEnum4Bit_Spare2" 2 "QualityEnum4Bit_Spare1" 1 "QualityEnum4Bit_Acceptable" 0 "QualityEnum4Bit_NotAcceptable" ;
VAL_ 554 EstAxle1_WhlRdEstQltyRi 15 "QualityEnum4Bit_NotAvailable" 14 "QualityEnum4Bit_Error" 13 "QualityEnum4Bit_Spare12" 12 "QualityEnum4Bit_Spare11" 11 "QualityEnum4Bit_Spare10" 10 "QualityEnum4Bit_Spare9" 9 "QualityEnum4Bit_Spare8" 8 "QualityEnum4Bit_Spare7" 7 "QualityEnum4Bit_Spare6" 6 "QualityEnum4Bit_Spare5" 5 "QualityEnum4Bit_Spare4" 4 "QualityEnum4Bit_Spare3" 3 "QualityEnum4Bit_Spare2" 2 "QualityEnum4Bit_Spare1" 1 "QualityEnum4Bit_Acceptable" 0 "QualityEnum4Bit_NotAcceptable" ;
VAL_ 631 APM_LowAirPressureAlert 3 "LowAirPressureAlert_NotAvailable" 2 "LowAirPressureAlert_Error" 1 "LowAirPressureAlert_LowPressure" 0 "LowAirPressureAlert_NormalPressure" ;
VAL_ 631 EPBHSARequest 7 "EPBHSARequest_NotAvailable" 6 "EPBHSARequest_Error" 5 "EPBHSARequest_Spare_3" 4 "EPBHSARequest_Spare_2" 3 "EPBHSARequest_Spare_1" 2 "EPBHSARequest_Requested" 1 "EPBHSARequest_NotRequestedReleaseWhenPossible" 0 "EPBHSARequest_NotRequestedReleaseImmediately" ;
VAL_ 631 APM_ParkBrakeActuationStatus 7 "ParkBrakeActuationStatus_NotAvailable" 6 "ParkBrakeActuationStatus_Error" 5 "ParkBrakeActuationStatus_SpareValue_01" 4 "ParkBrakeActuationStatus_SpareValue" 3 "ParkBrakeActuationStatus_AntiCompound" 2 "ParkBrakeActuationStatus_Parked" 1 "ParkBrakeActuationStatus_PartiallyParked" 0 "ParkBrakeActuationStatus_Released" ;
VAL_ 1447 DriverMemory_rqst 31 "DriverMemory_rqst_Error" 30 "DriverMemory_rqst_NotAvailable" 29 "DriverMemory_rqst_Spare_07" 28 "DriverMemory_rqst_Spare_06" 27 "DriverMemory_rqst_Spare_05" 26 "DriverMemory_rqst_Spare_04" 25 "DriverMemory_rqst_Spare_03" 24 "DriverMemory_rqst_Spare_02" 23 "DriverMemory_rqst_Spare_01" 22 "DriverMemory_rqst_Spare" 21 "DriverMemory_rqst_ResetAllMemThenUseDefDriverMem" 20 "DriverMemory_rqst_ResetAndThenUseDriverMemory10" 19 "DriverMemory_rqst_ResetAndThenUseDriverMemory9" 18 "DriverMemory_rqst_ResetAndThenUseDriverMemory8" 17 "DriverMemory_rqst_ResetAndThenUseDriverMemory7" 16 "DriverMemory_rqst_ResetAndThenUseDriverMemory6" 15 "DriverMemory_rqst_ResetAndThenUseDriverMemory5" 14 "DriverMemory_rqst_ResetAndThenUseDriverMemory4" 13 "DriverMemory_rqst_ResetAndThenUseDriverMemory3" 12 "DriverMemory_rqst_ResetAndThenUseDriverMemory2" 11 "DriverMemory_rqst_ResetAndThenUseDriverMemory1" 10 "DriverMemory_rqst_UseDriverMemory10" 9 "DriverMemory_rqst_UseDriverMemory9" 8 "DriverMemory_rqst_UseDriverMemory8" 7 "DriverMemory_rqst_UseDriverMemory7" 6 "DriverMemory_rqst_UseDriverMemory6" 5 "DriverMemory_rqst_UseDriverMemory5" 4 "DriverMemory_rqst_UseDriverMemory4" 3 "DriverMemory_rqst_UseDriverMemory3" 2 "DriverMemory_rqst_UseDriverMemory2" 1 "DriverMemory_rqst_UseDriverMemory1" 0 "DriverMemory_rqst_UseDefaultDriverMemory" ;
VAL_ 1447 FasDriver_rqst 15 "FasDriver_NotAvailable" 14 "FasDriver_Error" 13 "FasDriver_Spare3" 12 "FasDriver_Spare2" 11 "FasDriver_Spare1" 10 "FasDriver_Driver10" 9 "FasDriver_Driver9" 8 "FasDriver_Driver8" 7 "FasDriver_Driver7" 6 "FasDriver_Driver6" 5 "FasDriver_Driver5" 4 "FasDriver_Driver4" 3 "FasDriver_Driver3" 2 "FasDriver_Driver2" 1 "FasDriver_Driver1" 0 "FasDriver_DefaultDriver" ;
VAL_ 1447 FasPersonalSettingsButton_rqst 7 "FasPersSettingsButton_NotAvailable" 6 "FasPersSettingsButton_Error" 5 "FasPersSettingsButton_Spare" 4 "FasPersSettingsButton_UserDefinedButton" 3 "FasPersSettingsButton_PresetButtonHeavy" 2 "FasPersSettingsButton_PresetButtonFirm" 1 "FasPersSettingsButton_PresetButtonLight" 0 "FasPersSettingsButton_PresetButtonDefault" ;
VAL_ 1447 FasUsrDefinedStorage_rqst 3 "FasUsrDefinedStorage_NotAvailable" 2 "FasUsrDefinedStorage_Error" 1 "FasUsrDefinedStorage_StoreUserDefinedSetting" 0 "FasUsrDefinedStorage_DoNotStoreUserDefinedSetting" ;
VAL_ 1034 PBStatus_Actuation 7 "PBActuationStatus_NotAvailable" 6 "PBActuationStatus_Error" 5 "PBActuationStatus_Spare3" 4 "PBActuationStatus_Spare2" 3 "PBActuationStatus_Spare1" 2 "PBActuationStatus_Parked" 1 "PBActuationStatus_Intermediate" 0 "PBActuationStatus_Released" ;
VAL_ 1034 PBStatus_IntegrityLvl 3 "PBIntegrityLvl_HighIntegrity" 2 "PBIntegrityLvl_Spare" 1 "PBIntegrityLvl_LowIntegrity" 0 "PBIntegrityLvl_Downgraded" ;
VAL_ 1034 ContTrailerBrake_Request 7 "ContTrailerBrake_rqst_NotAvailable" 6 "ContTrailerBrake_rqst_Error" 5 "ContTrailerBrake_rqst_Spare_01" 4 "ContTrailerBrake_rqst_Spare" 3 "ContTrailerBrake_rqst_Decrease" 2 "ContTrailerBrake_rqst_Increase" 1 "ContTrailerBrake_rqst_Activate" 0 "ContTrailerBrake_rqst_Deactivate" ;
VAL_ 426 ChangeKneelACK 3 "ChangeKneelACK_NotAvailable" 2 "ChangeKneelACK_Error" 1 "ChangeKneelACK_ChangeAcknowledged" 0 "ChangeKneelACK_NoAction" ;
VAL_ 426 LiftAxle1PositionStatus 7 "LiftAxlePositionStatus_NotAvailable" 6 "LiftAxlePositionStatus_Error" 5 "LiftAxlePositionStatus_Reserved_01" 4 "LiftAxlePositionStatus_Reserved" 3 "LiftAxlePositionStatus_Lifting" 2 "LiftAxlePositionStatus_Lowering" 1 "LiftAxlePositionStatus_Lifted" 0 "LiftAxlePositionStatus_Lowered" ;
VAL_ 426 FrontFerryFunctionCmd 7 "FerryFunctionCmd_NotAvailable" 6 "FerryFunctionCmd_Error" 5 "FerryFunctionCmd_Spare2" 4 "FerryFunctionCmd_Spare1" 3 "FerryFunctionCmd_Spare0" 2 "FerryFunctionCmd_Drain" 1 "FerryFunctionCmd_CloseValves" 0 "FerryFunctionCmd_Inactive" ;
VAL_ 426 ReverseGearEngaged 3 "ReverseGearEngaged_NotAvailable" 2 "ReverseGearEngaged_Error" 1 "ReverseGearEngaged_ReverseGearEngaged" 0 "ReverseGearEngaged_ReverseGearNotEngaged" ;
VAL_ 426 AirDumpStatus 7 "AirDumpStatus_NotAvailable" 6 "AirDumpStatus_Error" 5 "AirDumpStatus_Spare2" 4 "AirDumpStatus_Spare1" 3 "AirDumpStatus_Denied" 2 "AirDumpStatus_ActiveReached" 1 "AirDumpStatus_ActiveNotReached" 0 "AirDumpStatus_Inactive" ;
VAL_ 426 EngineActiveStatus 15 "EngineActiveStatus_NotAvailable" 14 "EngineActiveStatus_Error" 13 "EngineActiveStatus_Spare_10" 12 "EngineActiveStatus_Spare_09" 11 "EngineActiveStatus_Spare_08" 10 "EngineActiveStatus_Spare_07" 9 "EngineActiveStatus_Spare_06" 8 "EngineActiveStatus_Spare_05" 7 "EngineActiveStatus_Spare_04" 6 "EngineActiveStatus_Spare_03" 5 "EngineActiveStatus_Spare_02" 4 "EngineActiveStatus_Spare_01" 3 "EngineActiveStatus_EngineStandby" 2 "EngineActiveStatus_ElectricPropulsionSystemRunning" 1 "EngineActiveStatus_InternalCombustionEngineRunning" 0 "EngineActiveStatus_DrivelineNotActive" ;
VAL_ 426 FerryFunctionStatus 7 "FerryFunctionStatus_NotAvailable" 6 "FerryFunctionStatus_Error" 5 "FerryFunctionStatus_Spare_03" 4 "FerryFunctionStatus_Spare_02" 3 "FerryFunctionStatus_Spare_01" 2 "FerryFunctionStatus_FerryFunctionActiveLeveNotlReached" 1 "FerryFunctionStatus_FerryFunctionActiveLevelReached" 0 "FerryFunctionStatus_FerryFunctionNotActive" ;
VAL_ 426 APM_LowVMPBInfoReq 7 "LevelLow3bit_NotAvailable" 6 "LevelLow3bit_Error" 5 "LevelLow3bit_LowLevel5" 4 "LevelLow3bit_LowLevel4" 3 "LevelLow3bit_LowLevel3" 2 "LevelLow3bit_LowLevel2" 1 "LevelLow3bit_LowLevel1" 0 "LevelLow3bit_NoRequest" ;
VAL_ 426 KneelingInformation 15 "KneelingInformation_NotAvailable" 14 "KneelingInformation_ErrorIndicator" 13 "KneelingInformation_NotDefined_08" 12 "KneelingInformation_NotDefined_07" 11 "KneelingInformation_NotDefined_06" 10 "KneelingInformation_NotDefined_05" 9 "KneelingInformation_NotDefined_04" 8 "KneelingInformation_NotDefined_03" 7 "KneelingInformation_NotDefined_02" 6 "KneelingInformation_NotDefined_01" 5 "KneelingInformation_NotDefined" 4 "KneelingInformation_KneelingAborted" 3 "KneelingInformation_LiftingActiveVehicleIsLiftedDueToRcvrReq" 2 "KneelingInformation_KneelLevelReachedVehicleIsAtFixeKneelLvl" 1 "KneelingInformation_LoweringActiveTheVehIsLoweredDueToKneelReq" 0 "KneelingInformation_NotActiveTheKneelingFunctionIsNotActive" ;
VAL_ 426 FASHapticFeedbackRequest 15 "FASHapticFeedbackRequest_NotAvailable" 14 "FASHapticFeedbackRequest_Error" 13 "FASHapticFeedbackRequest_Spare3" 12 "FASHapticFeedbackRequest_Spare2" 11 "FASHapticFeedbackRequest_Spare1" 10 "FASHapticFeedbackRequest_PredefinedFreqAndAmpl10" 9 "FASHapticFeedbackRequest_PredefinedFreqAndAmpl9" 8 "FASHapticFeedbackRequest_PredefinedFreqAndAmpl8" 7 "FASHapticFeedbackRequest_PredefinedFreqAndAmpl7" 6 "FASHapticFeedbackRequest_PredefinedFreqAndAmpl6" 5 "FASHapticFeedbackRequest_PredefinedFreqAndAmpl5" 4 "FASHapticFeedbackRequest_PredefinedFreqAndAmpl4" 3 "FASHapticFeedbackRequest_PredefinedFreqAndAmpl3" 2 "FASHapticFeedbackRequest_PredefinedFreqAndAmpl2" 1 "FASHapticFeedbackRequest_PredefinedFreqAndAmpl1" 0 "FASHapticFeedbackRequest_NoHapticFeedback" ;
VAL_ 426 HeightControlMode 15 "HeightControlMode_NotAvailable" 14 "HeightControlMode_ErrorIndicator" 13 "HeightControlMode_DumpFunction" 12 "HeightControlMode_FactorySupportMode" 11 "HeightControlMode_Calibration" 10 "HeightControlMode_Prohibit" 9 "HeightControlMode_FunctionTest" 8 "HeightControlMode_Stop" 7 "HeightControlMode_LimpHome" 6 "HeightControlMode_FerryFunction" 5 "HeightControlMode_KneelingHeight" 4 "HeightControlMode_DriveHeight" 3 "HeightControlMode_DockingRampHeight" 2 "HeightControlMode_HeightAdjustment" 1 "HeightControlMode_StartUpHeight" 0 "HeightControlMode_TakeNoAction" ;
VAL_ 426 LoadDistributionFuncSelected 15 "LoadDistributionFuncSelected_NotAvaiable" 14 "LoadDistributionFuncSelected_ErrorIndicator" 13 "LoadDistributionFuncSelected_SpareValue_08" 12 "LoadDistributionFuncSelected_SpareValue_07" 11 "LoadDistributionFuncSelected_SpareValue_06" 10 "LoadDistributionFuncSelected_SpareValue_05" 9 "LoadDistributionFuncSelected_SpareValue_04" 8 "LoadDistributionFuncSelected_SpareValue_03" 7 "LoadDistributionFuncSelected_SpareValue_02" 6 "LoadDistributionFuncSelected_MaximumTractionStartingHelp" 5 "LoadDistributionFuncSelected_VariableAxleLoad" 4 "LoadDistributionFuncSelected_NoLoadDistribution" 3 "LoadDistributionFuncSelected_AlternativeLoad" 2 "LoadDistributionFuncSelected_MaximumTractionTractionHelp" 1 "LoadDistributionFuncSelected_OptimisedTraction" 0 "LoadDistributionFuncSelected_NormalLoad" ;
VAL_ 426 RollEndPositionStatus 7 "RollEndPositionStatus_NotAvailable" 6 "RollEndPositionStatus_Error" 5 "RollEndPositionStatus_Reserved_01" 4 "RollEndPositionStatus_Reserved" 3 "RollEndPositionStatus_NoRollingAllowed" 2 "RollEndPositionStatus_CounterClockwiseEndLevelReached" 1 "RollEndPositionStatus_ClockwiseEndLevelReached" 0 "RollEndPositionStatus_NoEndLevelReached" ;
VAL_ 426 RearAxle2DiffLock_stat 3 "OffOn_NotAvailable" 2 "OffOn_Error" 1 "OffOn_On" 0 "OffOn_Off" ;
VAL_ 426 KneelingStatusHMI 3 "KneelingStatusHMI_NotAvailable" 2 "KneelingStatusHMI_Error" 1 "KneelingStatusHMI_Active" 0 "KneelingStatusHMI_Inactive" ;
VAL_ 426 HeightAdjustmentAllowed 3 "FalseTrue_NotAvaiable" 2 "FalseTrue_Error" 1 "FalseTrue_True" 0 "FalseTrue_False" ;
VAL_ 426 RideHeightStatus 15 "RideHeightStatus_NotAvailable" 14 "RideHeightStatus_ErrorIndicator" 13 "RideHeightStatus_NotDefined_03" 12 "RideHeightStatus_NotDefined_02" 11 "RideHeightStatus_NotDefined_01" 10 "RideHeightStatus_NotDefined" 9 "RideHeightStatus_AlternativeDrivePosition2" 8 "RideHeightStatus_AlternativeDrivePosition1" 7 "RideHeightStatus_AlternativeDrivePosition" 6 "RideHeightStatus_HighDrivePosition" 5 "RideHeightStatus_LowDrivePosition" 4 "RideHeightStatus_SpeedDependentDrivePositionHighSpeed" 3 "RideHeightStatus_SpeedDependentDrivePositionLowSpeed" 2 "RideHeightStatus_StandardUserDrivePosition" 1 "RideHeightStatus_StandardFactoryDrivePosition" 0 "RideHeightStatus_Inactive" ;
VAL_ 426 CentralRearDiffLock_stat 3 "DisengageEngage_NotAvailable" 2 "DisengageEngage_Error" 1 "DisengageEngage_Engage" 0 "DisengageEngage_Disengage" ;
VAL_ 426 ParkBrakeReleaseMode2 15 "ParkBrakeReleaseMode2_NotAvailable" 14 "ParkBrakeReleaseMode2_Error" 13 "ParkBrakeReleaseMode2_Reserved7" 12 "ParkBrakeReleaseMode2_Reserved6" 11 "ParkBrakeReleaseMode2_Reserved5" 10 "ParkBrakeReleaseMode2_Reserved4" 9 "ParkBrakeReleaseMode2_Reserved3" 8 "ParkBrakeReleaseMode2_Reserved2" 7 "ParkBrakeReleaseMode2_RedundantExternalDemand" 6 "ParkBrakeReleaseMode2_AutomaticallyinHillHolder" 5 "ParkBrakeReleaseMode2_AutomaticInBackup" 4 "ParkBrakeReleaseMode2_MainExternalDemand" 3 "ParkBrakeReleaseMode2_AutomaticallyAccelPedal" 2 "ParkBrakeReleaseMode2_ManuallyAtStandstill" 1 "ParkBrakeReleaseMode2_ManuallyInDriving" 0 "ParkBrakeReleaseMode2_Idle" ;
VAL_ 426 LiftAxle2PositionStatus 7 "LiftAxlePositionStatus_NotAvailable" 6 "LiftAxlePositionStatus_Error" 5 "LiftAxlePositionStatus_Reserved_01" 4 "LiftAxlePositionStatus_Reserved" 3 "LiftAxlePositionStatus_Lifting" 2 "LiftAxlePositionStatus_Lowering" 1 "LiftAxlePositionStatus_Lifted" 0 "LiftAxlePositionStatus_Lowered" ;
VAL_ 426 RampHeightOutsideTargetRange 7 "HeightOutsideTargetRange_NotAvailable" 6 "HeightOutsideTargetRange_Error" 5 "HeightOutsideTargetRange_NotDefined_02" 4 "HeightOutsideTargetRange_NotDefined_01" 3 "HeightOutsideTargetRange_NotDefined" 2 "HeightOutsideTargetRange_ToHigh" 1 "HeightOutsideTargetRange_ToLow" 0 "HeightOutsideTargetRange_Inactive" ;
VAL_ 426 DirInd_Rear_Status 7 "DirIndFaultStatus_NotAvailable" 6 "DirIndFaultStatus_Error" 5 "DirIndFaultStatus_SpareValue_01" 4 "DirIndFaultStatus_SpareValue" 3 "DirIndFaultStatus_BothLeftAndRightDirectionIndicatorsFault" 2 "DirIndFaultStatus_RightDirectionIndicatorLampFault" 1 "DirIndFaultStatus_LeftDirectionIndicatorLampFault" 0 "DirIndFaultStatus_NoError" ;
VAL_ 426 APM_ParkingBrake_stat 3 "ParkingBrake_stat_NotAvailable" 2 "ParkingBrake_stat_Error" 1 "ParkingBrake_stat_ParkingBrakeActivated" 0 "ParkingBrake_stat_ParkingBrakeReleased" ;
VAL_ 426 BackToDriveReqACK 3 "BackToDriveReqACK_NotAvailable" 2 "BackToDriveReqACK_Error" 1 "BackToDriveReqACK_ChangeAcknowledged" 0 "BackToDriveReqACK_TakNoAction" ;
VAL_ 426 RearAxle1DiffLock_stat 3 "OffOn_NotAvailable" 2 "OffOn_Error" 1 "OffOn_On" 0 "OffOn_Off" ;
VAL_ 426 LevelControlInformation 15 "LevelControlInformation_NotAvailable" 14 "LevelControlInformation_Error" 13 "LevelControlInformation_Reserved_06" 12 "LevelControlInformation_Reserved_05" 11 "LevelControlInformation_Reserved_04" 10 "LevelControlInformation_Reserved_03" 9 "LevelControlInformation_Reserved_02" 8 "LevelControlInformation_Reserved_01" 7 "LevelControlInformation_Reserved" 6 "LevelControlInformation_LimpHome" 5 "LevelControlInformation_FerryFunction" 4 "LevelControlInformation_KneelingHeight" 3 "LevelControlInformation_DriveHeight" 2 "LevelControlInformation_DockingHeight" 1 "LevelControlInformation_HeightAdjustment" 0 "LevelControlInformation_Prohibit" ;
VAL_ 426 VehicleMode 15 "VehicleMode_NotAvailable" 14 "VehicleMode_Error" 13 "VehicleMode_Spare_7" 12 "VehicleMode_Spare_6" 11 "VehicleMode_Spare_5" 10 "VehicleMode_Spare_4" 9 "VehicleMode_Spare_3" 8 "VehicleMode_Spare_2" 7 "VehicleMode_Spare_1" 6 "VehicleMode_Running" 5 "VehicleMode_Cranking" 4 "VehicleMode_PreRunning" 3 "VehicleMode_Accessory" 2 "VehicleMode_Living" 1 "VehicleMode_Parked" 0 "VehicleMode_Hibernate" ;
VAL_ 426 ACC_SGO_Status 15 "ACC_SGO_Status_NotAvailable" 14 "ACC_SGO_Status_Error" 13 "ACC_SGO_Status_Spare7" 12 "ACC_SGO_Status_Spare6" 11 "ACC_SGO_Status_Spare5" 10 "ACC_SGO_Status_Spare4" 9 "ACC_SGO_Status_Spare3" 8 "ACC_SGO_Status_Spare2" 7 "ACC_SGO_Status_Spare1" 6 "ACC_SGO_Status_ACC_SGO_Active_TakeOffRequest" 5 "ACC_SGO_Status_ACC_SGO_Active_Hold" 4 "ACC_SGO_Status_ACC_SGO_Active_Stationary" 3 "ACC_SGO_Status_ACC_SGO_Stopping" 2 "ACC_SGO_Status_ACC_SGO_Active_Driving" 1 "ACC_SGO_Status_ACC_SGO_Inactive" 0 "ACC_SGO_Status_ACC_SGO_OFF" ;
VAL_ 426 RearEndPositionStatus 7 "EndPositionStatus_NotAvailable" 6 "EndPositionStatus_Error" 5 "EndPositionStatus_Reserved_01" 4 "EndPositionStatus_Reserved" 3 "EndPositionStatus_LiftingAndLoweringNotAllowed" 2 "EndPositionStatus_MinEndLevelReached" 1 "EndPositionStatus_MaxEndLevelReached" 0 "EndPositionStatus_NoEndLevelReached" ;
VAL_ 426 ECSShutdownCmd 3 "FalseTrue_NotAvaiable" 2 "FalseTrue_Error" 1 "FalseTrue_True" 0 "FalseTrue_False" ;
VAL_ 426 APM_ParkBrakeApplicationMode2 15 "ParkBrakeApplicationMode2_NotAvailable" 14 "ParkBrakeApplicationMode2_Error" 13 "ParkBrakeApplicationMode2_Reserved5" 12 "ParkBrakeApplicationMode2_Reserved4" 11 "ParkBrakeApplicationMode2_Reserved3" 10 "ParkBrakeApplicationMode2_Reserved2" 9 "ParkBrakeApplicationMode2_RedundantExternalDemand" 8 "ParkBrakeApplicationMode2_AutomaticcallyDoorOpen" 7 "ParkBrakeApplicationMode2_ParkBrakeBlending" 6 "ParkBrakeApplicationMode2_AutomaticallyHillHolder" 5 "ParkBrakeApplicationMode2_AutomaticInBackup" 4 "ParkBrakeApplicationMode2_MainExternalDemand" 3 "ParkBrakeApplicationMode2_AutomaticallyKeyOff" 2 "ParkBrakeApplicationMode2_ManuallyAtStandstill" 1 "ParkBrakeApplicationMode2_ManuallyInDriving" 0 "ParkBrakeApplicationMode2_Idle" ;
VAL_ 426 VehicleDynamicSuspProhibitStat 3 "InactiveActive_NotAvailable" 2 "InactiveActive_Error" 1 "InactiveActive_Active" 0 "InactiveActive_Inactive" ;
VAL_ 426 ParkingBrake_stat 3 "ParkingBrake_stat_NotAvailable" 2 "ParkingBrake_stat_Error" 1 "ParkingBrake_stat_ParkingBrakeActivated" 0 "ParkingBrake_stat_ParkingBrakeReleased" ;
VAL_ 426 RideHeightFunctionStatus 15 "RideHeightFunction_NotAvailable" 14 "RideHeightFunction_ErrorIndicator" 13 "RideHeightFunction_NotDefined_05" 12 "RideHeightFunction_NotDefined_04" 11 "RideHeightFunction_NotDefined_03" 10 "RideHeightFunction_NotDefined_02" 9 "RideHeightFunction_NotDefined_01" 8 "RideHeightFunction_NotDefined" 7 "RideHeightFunction_AlternativeDrivePosition2" 6 "RideHeightFunction_AlternativeDrivePosition1" 5 "RideHeightFunction_LowDrivePosition" 4 "RideHeightFunction_HighDrivePosition" 3 "RideHeightFunction_SpeedDependentDrivePosition" 2 "RideHeightFunction_AlternativeDrivePosition" 1 "RideHeightFunction_StandardDrivePosition" 0 "RideHeightFunction_Inactive" ;
VAL_ 426 APM_TrailerCircPressureStatus 3 "TrailerCircuitPressureStatus_NotAvailable" 2 "TrailerCircuitPressureStatus_Error" 1 "TrailerCircuitPressureStatus_EnabledLowPressureAlert" 0 "TrailerCircuitPressureStatus_DisabledLowPressureAlert" ;
SIG_GROUP_ 266 ZxbrReqVeh_sg 1 : ZxbrReqVeh_RetReq ZxbrReqVeh_RetModReq ZxbrReqVeh_VmmModSts ZxbrReqVeh_RetEbiModReq ZxbrReqVeh_CRC ZxbrReqVeh_DrvrModReq ZxbrReqVeh_YawRateRefVds ZxbrReqVeh_SqC;
SIG_GROUP_ 262 IxbrReqAxle5_sg 1 : IxbrReqAxle5_SqC IxbrReqAxle5_VehSpdLgtWhlRi IxbrReqAxle5_BrkTqReqRi IxbrReqAxle5_SlipCtrlEna IxbrReqAxle5_WhlSlipLimLoRi IxbrReqAxle5_VehSpdLgtWhlLe IxbrReqAxle5_VehSpdLgtWhlQltyLe IxbrReqAxle5_CRC IxbrReqAxle5_BrkTqReqLe IxbrReqAxle5_VehSpdLgtWhlQltyRi IxbrReqAxle5_WhlSlipLimHiRi IxbrReqAxle5_WhlSlipLimLoLe IxbrReqAxle5_IxbrModReq IxbrReqAxle5_WhlSlipLimHiLe;
SIG_GROUP_ 262 IxbrReqAxle6_sg 1 : IxbrReqAxle6_WhlSlipLimLoLe IxbrReqAxle6_WhlSlipLimHiRi IxbrReqAxle6_SqC IxbrReqAxle6_WhlSlipLimLoRi IxbrReqAxle6_VehSpdLgtWhlRi IxbrReqAxle6_CRC IxbrReqAxle6_VehSpdLgtWhlQltyRi IxbrReqAxle6_BrkTqReqLe IxbrReqAxle6_BrkTqReqRi IxbrReqAxle6_SlipCtrlEna IxbrReqAxle6_VehSpdLgtWhlQltyLe IxbrReqAxle6_IxbrModReq IxbrReqAxle6_WhlSlipLimHiLe IxbrReqAxle6_VehSpdLgtWhlLe;
SIG_GROUP_ 262 IxbrReqAxle4_sg 1 : IxbrReqAxle4_SlipCtrlEna IxbrReqAxle4_BrkTqReqLe IxbrReqAxle4_CRC IxbrReqAxle4_BrkTqReqRi IxbrReqAxle4_SqC IxbrReqAxle4_VehSpdLgtWhlRi IxbrReqAxle4_WhlSlipLimHiLe IxbrReqAxle4_VehSpdLgtWhlLe IxbrReqAxle4_WhlSlipLimLoLe IxbrReqAxle4_WhlSlipLimLoRi IxbrReqAxle4_VehSpdLgtWhlQltyRi IxbrReqAxle4_IxbrModReq IxbrReqAxle4_VehSpdLgtWhlQltyLe IxbrReqAxle4_WhlSlipLimHiRi;
SIG_GROUP_ 261 IxbrReqAxle2_sg 1 : IxbrReqAxle2_WhlSlipLimHiRi IxbrReqAxle2_BrkTqReqLe IxbrReqAxle2_BrkTqReqRi IxbrReqAxle2_SlipCtrlEna IxbrReqAxle2_WhlSlipLimLoRi IxbrReqAxle2_IxbrModReq IxbrReqAxle2_SqC IxbrReqAxle2_WhlSlipLimLoLe IxbrReqAxle2_VehSpdLgtWhlLe IxbrReqAxle2_WhlSlipLimHiLe IxbrReqAxle2_CRC IxbrReqAxle2_VehSpdLgtWhlQltyLe IxbrReqAxle2_VehSpdLgtWhlRi IxbrReqAxle2_VehSpdLgtWhlQltyRi;
SIG_GROUP_ 261 IxbrReqAxle3_sg 1 : IxbrReqAxle3_BrkTqReqLe IxbrReqAxle3_WhlSlipLimHiLe IxbrReqAxle3_WhlSlipLimLoRi IxbrReqAxle3_BrkTqReqRi IxbrReqAxle3_VehSpdLgtWhlQltyLe IxbrReqAxle3_SqC IxbrReqAxle3_WhlSlipLimLoLe IxbrReqAxle3_VehSpdLgtWhlRi IxbrReqAxle3_WhlSlipLimHiRi IxbrReqAxle3_VehSpdLgtWhlQltyRi IxbrReqAxle3_IxbrModReq IxbrReqAxle3_VehSpdLgtWhlLe IxbrReqAxle3_SlipCtrlEna IxbrReqAxle3_CRC;
SIG_GROUP_ 261 IxbrReqAxle1_sg 1 : IxbrReqAxle1_BrkTqReqLe IxbrReqAxle1_WhlSlipLimLoLe IxbrReqAxle1_VehSpdLgtWhlQltyRi IxbrReqAxle1_WhlSlipLimHiLe IxbrReqAxle1_SlipCtrlEna IxbrReqAxle1_WhlSlipLimLoRi IxbrReqAxle1_IxbrModReq IxbrReqAxle1_SqC IxbrReqAxle1_WhlSlipLimHiRi IxbrReqAxle1_VehSpdLgtWhlLe IxbrReqAxle1_VehSpdLgtWhlQltyLe IxbrReqAxle1_BrkTqReqRi IxbrReqAxle1_VehSpdLgtWhlRi IxbrReqAxle1_CRC;
SIG_GROUP_ 554 EstAxle4_sg 1 : EstAxle4_LoadNormQltyRi EstAxle4_LoadNormRi EstAxle4_WhlRdEstRi EstAxle4_SqC EstAxle4_WhlRdEstQltyRi EstAxle4_WhlRdEstQltyLe EstAxle4_WhlRdEstLe EstAxle4_LoadNormQltyLe EstAxle4_CRC EstAxle4_LoadNormLe;
SIG_GROUP_ 554 EstAxle2_sg 1 : EstAxle2_LoadNormQltyLe EstAxle2_WhlRdEstLe EstAxle2_LoadNormRi EstAxle2_LoadNormLe EstAxle2_LoadNormQltyRi EstAxle2_WhlRdEstQltyRi EstAxle2_WhlRdEstRi EstAxle2_CRC EstAxle2_WhlRdEstQltyLe EstAxle2_SqC;
SIG_GROUP_ 554 EstAxle1_sg 1 : EstAxle1_WhlRdEstRi EstAxle1_LoadNormQltyRi EstAxle1_LoadNormQltyLe EstAxle1_WhlRdEstQltyLe EstAxle1_LoadNormLe EstAxle1_CRC EstAxle1_LoadNormRi EstAxle1_WhlRdEstLe EstAxle1_SqC EstAxle1_WhlRdEstQltyRi;
SIG_GROUP_ 554 EstAxle6_sg 1 : EstAxle6_WhlRdEstQltyRi EstAxle6_SqC EstAxle6_LoadNormRi EstAxle6_CRC EstAxle6_WhlRdEstLe EstAxle6_WhlRdEstQltyLe EstAxle6_LoadNormLe EstAxle6_WhlRdEstRi EstAxle6_LoadNormQltyRi EstAxle6_LoadNormQltyLe;
SIG_GROUP_ 554 EstAxle5_sg 1 : EstAxle5_WhlRdEstQltyRi EstAxle5_SqC EstAxle5_LoadNormQltyRi EstAxle5_LoadNormRi EstAxle5_LoadNormQltyLe EstAxle5_CRC EstAxle5_LoadNormLe EstAxle5_WhlRdEstLe EstAxle5_WhlRdEstRi EstAxle5_WhlRdEstQltyLe;
SIG_GROUP_ 554 EstAxle3_sg 1 : EstAxle3_LoadNormLe EstAxle3_LoadNormQltyRi EstAxle3_WhlRdEstRi EstAxle3_WhlRdEstQltyLe EstAxle3_CRC EstAxle3_LoadNormQltyLe EstAxle3_WhlRdEstQltyRi EstAxle3_LoadNormRi EstAxle3_SqC EstAxle3_WhlRdEstLe;
SIG_GROUP_ 1034 PBStatus_sg 1 : PBStatus_CRC PBStatus_Actuation PBStatus_SqC PBStatus_IntegrityLvl;
SIG_GROUP_ 1034 PBAirLvl_sg 1 : PBAirLvl_AntiCompoundRatio PBAirLvl_SqC PBAirLvl_CRC PBAirLvl_PressureInChamber;
SIG_GROUP_ 1034 ContTrailerBrake_sg 1 : ContTrailerBrake_MsgCounter ContTrailerBrake_MsgChecksum ContTrailerBrake_Request;
